VERSION ""

NS_ :

BS_:

BU_: AHLM ASBS CADM CBC DIAGNOST DPDM DTCM ECM EHPS ESC ESL ESM ETM EVCU2 GPF IC IRCM LTM OCM ORC PTS RF_HUB SCCM SGW TBM TCM

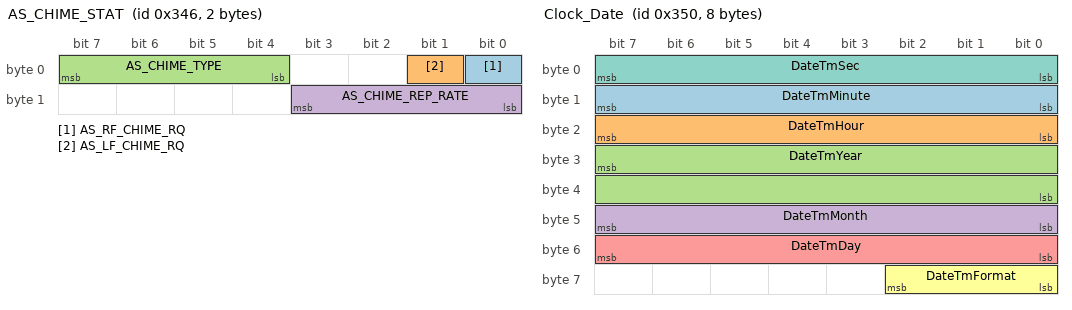
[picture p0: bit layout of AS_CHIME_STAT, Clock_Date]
BO_ 838 AS_CHIME_STAT: 2 CADM
 SG_ AS_RF_CHIME_RQ : 0|1@1+ (1,0) [0|0] ""  CBC,SGW
 SG_ AS_LF_CHIME_RQ : 1|1@1+ (1,0) [0|0] ""  CBC,SGW
 SG_ AS_CHIME_TYPE : 4|4@1+ (1,0) [0|0] ""  CBC,ORC,SGW
 SG_ AS_CHIME_REP_RATE : 8|4@1+ (1,0) [0|15] "Hz"  CBC,SGW

BO_ 840 ESP_C1: 8 ESC
 SG_ FailSafeError : 7|16@0+ (1,0) [0|65534] ""  CADM,IRCM,SGW

BO_ 848 Clock_Date: 8 CBC
 SG_ DateTmMinute : 8|8@1+ (1,0) [0|59] "min"  EVCU2,IC,RF_HUB,SGW
 SG_ DateTmHour : 16|8@1+ (1,0) [0|23] "Hours"  EVCU2,IC,RF_HUB,SGW
 SG_ DateTmYear : 31|16@0+ (1,0) [0|65534] "Years"  EVCU2,IC,RF_HUB,SGW
 SG_ DateTmMonth : 40|8@1+ (1,0) [1|12] "Months"  EVCU2,IC,RF_HUB,SGW
 SG_ DateTmDay : 48|8@1+ (1,0) [1|31] "Days"  EVCU2,IC,RF_HUB,SGW
 SG_ DateTmFormat : 56|3@1+ (1,0) [0|0] ""  EVCU2,IC,SGW
 SG_ DateTmSec : 0|8@1+ (1,0) [0|59] "sec"  EVCU2,IC,SGW

BO_ 850 ECM_APPL2: 8 DIAGNOST
 SG_ ECM_APPL2 : 7|64@0+ (1,0) [0|0] ""  ECM

BO_ 856 COMPASS_A1: 4 CBC
 SG_ CMP_DIR : 0|4@1+ (1,0) [0|0] ""  IC,SGW

BO_ 860 DIRECT_INFO: 6 CBC
 SG_ NAVPrsnt : 30|1@1+ (1,0) [0|0] ""  IC,SGW

BO_ 864 ECM_APPL1: 8 ECM
 SG_ ECM_APPL1 : 7|64@0+ (1,0) [0|0] ""  DIAGNOST,SGW

BO_ 872 TCM_HSA: 8 TCM
 SG_ TCM_HSA : 7|64@0+ (1,0) [0|0] ""  DIAGNOST,SGW

BO_ 880 ECM_APPL3: 8 ECM
 SG_ ECM_APPL3 : 7|64@0+ (1,0) [0|0] ""  DIAGNOST,SGW

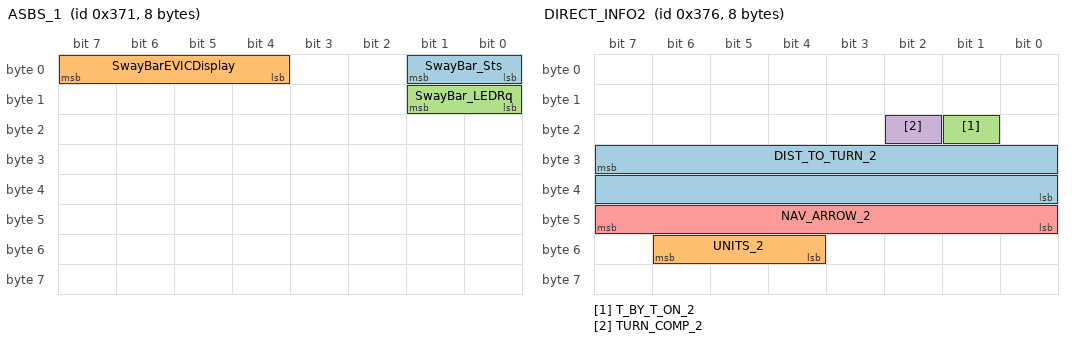
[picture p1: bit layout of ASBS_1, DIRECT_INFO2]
BO_ 881 ASBS_1: 8 ASBS
 SG_ SwayBar_Sts : 0|2@1+ (1,0) [0|0] ""  ETM,IC,SGW
 SG_ SwayBarEVICDisplay : 4|4@1+ (1,0) [0|0] ""  ETM,IC,SGW
 SG_ SwayBar_LEDRq : 8|2@1+ (1,0) [0|0] ""  CBC,SGW

BO_ 886 DIRECT_INFO2: 8 CBC
 SG_ DIST_TO_TURN_2 : 31|16@0+ (1,0) [0|65534] ""  IC,SGW
 SG_ UNITS_2 : 52|3@1+ (1,0) [0|0] ""  IC,SGW
 SG_ T_BY_T_ON_2 : 17|1@1+ (1,0) [0|0] ""  IC,SGW
 SG_ TURN_COMP_2 : 18|1@1+ (1,0) [0|0] ""  IC,SGW
 SG_ NAV_ARROW_2 : 40|8@1+ (1,0) [1|63] "Arrow"  IC,SGW

BO_ 888 TCM_HSB: 8 TCM
 SG_ TCM_HSB : 7|64@0+ (1,0) [0|0] ""  DIAGNOST,SGW

BO_ 896 ECM_APPL4: 8 ECM
 SG_ ECM_APPL4 : 7|64@0+ (1,0) [0|0] ""  DIAGNOST,SGW

BO_ 897 VehCfg7: 8 CBC
 SG_ VC_PBTyp : 29|3@1+ (1,0) [0|0] ""  CADM,IRCM,ORC,RF_HUB,SGW
 SG_ VC_TPMS_Configuration : 32|3@1+ (1,0) [0|0] ""  IC,RF_HUB,SGW
 SG_ VC_SmartAlternator : 35|1@1+ (1,0) [0|0] ""  ECM,RF_HUB,SGW
 SG_ VC_HybridType : 36|3@1+ (1,0) [0|0] ""  AHLM,CADM,DTCM,ECM,EHPS,ESC,EVCU2,IC,IRCM,ORC,PTS,RF_HUB,SGW,TCM
 SG_ VC_TSBM_Prsnt : 39|1@1+ (1,0) [0|0] ""  RF_HUB,SGW
 SG_ VC_ADR_PRSNT : 40|1@1+ (1,0) [0|0] ""  RF_HUB,SGW
 SG_ VC_Temp_Display_Resolution : 42|1@1+ (1,0) [0|0] ""  RF_HUB,SGW
 SG_ VC_AGSprsnt : 41|1@1+ (1,0) [0|0] ""  RF_HUB,SGW
 SG_ VC_PTCPrsnt : 43|1@1+ (1,0) [0|0] ""  ECM,RF_HUB,SGW
 SG_ VC_Glovebox : 44|1@1+ (1,0) [0|0] ""  RF_HUB,SGW
 SG_ VC_MOC_Type : 45|2@1+ (1,0) [0|0] ""  RF_HUB,SGW
 SG_ VC_SUNR_Prsnt : 47|1@1+ (1,0) [0|0] ""  RF_HUB,SGW
 SG_ VC_Brake_Type : 56|4@1+ (1,0) [0|0] ""  RF_HUB,SGW
 SG_ VC_Suspension_Type : 60|4@1+ (1,0) [0|0] ""  RF_HUB,SGW
 SG_ VC_GlareFree_Prsnt : 48|1@1+ (1,0) [0|0] ""  RF_HUB,SGW
 SG_ VC_PAD_Lamp_Ctrl : 49|1@1+ (1,0) [0|0] ""  RF_HUB,SGW
 SG_ VC_Vehicle_Package : 50|3@1+ (1,0) [0|0] ""  RF_HUB,SGW
 SG_ VC_TrafficSignInfo : 53|1@1+ (1,0) [0|0] ""  CADM,IC,RF_HUB,SGW
 SG_ VC_LaneCentering : 54|1@1+ (1,0) [0|0] ""  RF_HUB,SGW
 SG_ VC_LDW_Audio : 55|1@1+ (1,0) [0|0] ""  RF_HUB,SGW
 SG_ VC_VehCfg7_Stat : 0|2@1+ (1,0) [0|0] ""  CADM,DTCM,ECM,EHPS,ESC,EVCU2,IC,IRCM,ORC,PTS,RF_HUB,SCCM,SGW,TCM
 SG_ VC_LDW : 2|1@1+ (1,0) [0|0] ""  CADM,IC,IRCM,ORC,RF_HUB,SGW
 SG_ VC_TrnsDrvMdPrsnt : 3|1@1+ (1,0) [0|0] ""  RF_HUB,SGW,TCM
 SG_ VC_PdlsMdPrsnt : 4|1@1+ (1,0) [0|0] ""  RF_HUB,SGW,TCM
 SG_ VC_DST_Present : 5|1@1+ (1,0) [0|0] ""  ORC,RF_HUB,SGW
 SG_ VC_STP_PRSNT : 6|1@1+ (1,0) [0|0] ""  RF_HUB,SGW
 SG_ VC_eShifter_Prsnt : 7|1@1+ (1,0) [0|0] ""  RF_HUB,SGW
 SG_ VC_TransType : 8|6@1+ (1,0) [0|0] ""  DTCM,ESC,IC,RF_HUB,SGW
 SG_ VC_AS_ERS : 14|2@1+ (1,0) [0|0] ""  RF_HUB,SGW,TCM
 SG_ VC_TeenKey : 16|1@1+ (1,0) [0|0] ""  RF_HUB,SGW
 SG_ VC_SVC_Prsnt : 17|1@1+ (1,0) [0|0] ""  RF_HUB,SGW
 SG_ VC_FullSpeedRange_FCW : 18|1@1+ (1,0) [0|0] ""  CADM,ESC,IC,IRCM,RF_HUB,SGW
 SG_ VC_ACC_Type : 19|2@1+ (1,0) [0|0] ""  CADM,ECM,ESC,EVCU2,IC,IRCM,ORC,RF_HUB,SCCM,SGW,TCM
 SG_ VC_SuspPrsnt : 21|1@1+ (1,0) [0|0] ""  RF_HUB,SGW
 SG_ VC_DampingPrsnt : 22|1@1+ (1,0) [0|0] ""  RF_HUB,SGW
 SG_ VC_Trans_N_Hold_Prsnt : 23|1@1+ (1,0) [0|0] ""  RF_HUB,SGW
 SG_ VC_RedKey : 24|1@1+ (1,0) [0|0] ""  RF_HUB,SGW
 SG_ VC_ABSM : 25|1@1+ (1,0) [0|0] ""  RF_HUB,SGW
 SG_ VC_AxleLockerPrsnt : 26|2@1+ (1,0) [0|0] ""  DTCM,IC,RF_HUB,SGW
 SG_ VC_Trans_Equipped : 28|1@1+ (1,0) [0|0] ""  CADM,CBC,DTCM,ESC,IC,IRCM,ORC,PTS,RF_HUB,SGW

BO_ 898 VehCfgBu7: 8 RF_HUB
 SG_ VC_BU_VehCfg7_Stat : 0|2@1+ (1,0) [0|0] ""  CBC,SGW
 SG_ VC_BU_LDW : 2|1@1+ (1,0) [0|0] ""  CBC,SGW
 SG_ VC_BU_TrnsDrvMdPrsnt : 3|1@1+ (1,0) [0|0] ""  CBC,SGW
 SG_ VC_BU_PdlsMdPrsnt : 4|1@1+ (1,0) [0|0] ""  CBC,SGW
 SG_ VC_BU_DST_Present : 5|1@1+ (1,0) [0|0] ""  CBC,SGW
 SG_ VC_BU_STP_PRSNT : 6|1@1+ (1,0) [0|0] ""  CBC,SGW
 SG_ VC_BU_eShifter_Prsnt : 7|1@1+ (1,0) [0|0] ""  CBC,SGW
 SG_ VC_BU_TransType : 8|6@1+ (1,0) [0|0] ""  CBC,SGW
 SG_ VC_BU_AS_ERS : 14|2@1+ (1,0) [0|0] ""  CBC,SGW
 SG_ VC_BU_TeenKey : 16|1@1+ (1,0) [0|0] ""  CBC,SGW
 SG_ VC_BU_SVC_Prsnt : 17|1@1+ (1,0) [0|0] ""  CBC,SGW
 SG_ VC_BU_FullSpeedRange_FCW : 18|1@1+ (1,0) [0|0] ""  CBC,SGW
 SG_ VC_BU_ACC_Type : 19|2@1+ (1,0) [0|0] ""  CBC,SGW
 SG_ VC_BU_SuspPrsnt : 21|1@1+ (1,0) [0|0] ""  CBC,SGW
 SG_ VC_BU_DampingPrsnt : 22|1@1+ (1,0) [0|0] ""  CBC,SGW
 SG_ VC_BU_Trans_N_Hold_Prsnt : 23|1@1+ (1,0) [0|0] ""  CBC,SGW
 SG_ VC_BU_RedKey : 24|1@1+ (1,0) [0|0] ""  CBC,SGW
 SG_ VC_BU_ABSM : 25|1@1+ (1,0) [0|0] ""  CBC,SGW
 SG_ VC_BU_AxleLockerPrsnt : 26|2@1+ (1,0) [0|0] ""  CBC,SGW
 SG_ VC_BU_Trans_Equipped : 28|1@1+ (1,0) [0|0] ""  CBC,SGW
 SG_ VC_BU_PBTyp : 29|3@1+ (1,0) [0|0] ""  CBC,SGW
 SG_ VC_BU_TPMS_Configuration : 32|3@1+ (1,0) [0|0] ""  CBC,SGW
 SG_ VC_BU_SmartAlternator : 35|1@1+ (1,0) [0|0] ""  CBC,SGW
 SG_ VC_BU_HybridType : 36|3@1+ (1,0) [0|0] ""  CBC,SGW
 SG_ VC_BU_TSBM_Prsnt : 39|1@1+ (1,0) [0|0] ""  CBC,SGW
 SG_ VC_BU_ADR_PRSNT : 40|1@1+ (1,0) [0|0] ""  CBC,SGW
 SG_ VC_BU_Temp_Display_Resolution : 42|1@1+ (1,0) [0|0] ""  CBC,SGW
 SG_ VC_BU_AGSprsnt : 41|1@1+ (1,0) [0|0] ""  CBC,SGW
 SG_ VC_BU_PTCPrsnt : 43|1@1+ (1,0) [0|0] ""  CBC,SGW
 SG_ VC_BU_Glovebox : 44|1@1+ (1,0) [0|0] ""  CBC,SGW
 SG_ VC_BU_MOC_Type : 45|2@1+ (1,0) [0|0] ""  CBC,SGW
 SG_ VC_BU_SUNR_Prsnt : 47|1@1+ (1,0) [0|0] ""  CBC,SGW
 SG_ VC_BU_Brake_Type : 56|4@1+ (1,0) [0|0] ""  CBC,SGW
 SG_ VC_BU_Suspension_Type : 60|4@1+ (1,0) [0|0] ""  CBC,SGW
 SG_ VC_BU_GlareFree_Prsnt : 48|1@1+ (1,0) [0|0] ""  CBC,SGW
 SG_ VC_BU_PAD_Lamp_Ctrl : 49|1@1+ (1,0) [0|0] ""  CBC,SGW
 SG_ VC_BU_Vehicle_Package : 50|3@1+ (1,0) [0|0] ""  CBC,SGW
 SG_ VC_BU_TrafficSignInfo : 53|1@1+ (1,0) [0|0] ""  CBC,SGW
 SG_ VC_BU_LDW_Audio : 55|1@1+ (1,0) [0|0] ""  CBC,SGW
 SG_ VC_BU_LaneCentering : 54|1@1+ (1,0) [0|0] ""  CBC,SGW

BO_ 904 TCM_HSC: 8 TCM
 SG_ TCM_HSC : 7|64@0+ (1,0) [0|0] ""  DIAGNOST,SGW

BO_ 906 VehCfg8: 8 CBC
 SG_ VC_VehCfg8_Stat : 0|2@1+ (1,0) [0|0] ""  DTCM,ECM,EVCU2,IC,IRCM,RF_HUB,SGW,TCM
 SG_ VC_TIPL_LOT : 39|1@1+ (1,0) [0|0] ""  RF_HUB,SGW
 SG_ VC_STFA_Prsnt : 53|1@1+ (1,0) [0|0] ""  RF_HUB,SGW
 SG_ VC_Trans_Brake_PRSNT : 8|1@1+ (1,0) [0|0] ""  RF_HUB,SGW
 SG_ VC_Steering_Cfactor : 2|2@1+ (1,0) [0|0] ""  CADM,IRCM,RF_HUB,SGW
 SG_ VC_LineLock_PRSNT : 4|1@1+ (1,0) [0|0] ""  RF_HUB,SGW
 SG_ VC_HighOctane_PRSNT : 7|1@1+ (1,0) [0|0] ""  RF_HUB,SGW
 SG_ VC_CHILLER_PRSNT : 6|1@1+ (1,0) [0|0] ""  RF_HUB,SGW
 SG_ VC_ARC_PRSNT : 5|1@1+ (1,0) [0|0] ""  RF_HUB,SGW
 SG_ VC_Speedometer_Tolerance : 9|4@1+ (1,0) [0|0] ""  CADM,ECM,EVCU2,IC,IRCM,RF_HUB,SGW
 SG_ VC_Increasing_Speed_Constant : 13|3@1+ (1,0) [0|0] ""  CADM,ECM,EVCU2,IC,IRCM,RF_HUB,SGW
 SG_ VC_OvertakingBan : 16|1@1+ (1,0) [0|0] ""  IC,RF_HUB,SGW
 SG_ VC_SBL_FBL_CORNERING_PRSNT : 17|2@1+ (1,0) [0|0] ""  RF_HUB,SGW
 SG_ VC_BEAM_SHAPING_PRSNT : 19|1@1+ (1,0) [0|0] ""  RF_HUB,SGW
 SG_ VC_DBL_PRSNT : 20|1@1+ (1,0) [0|0] ""  RF_HUB,SGW
 SG_ VC_FADPrsnt : 38|1@1+ (1,0) [0|0] ""  DTCM,RF_HUB,SGW
 SG_ VC_AVAC_PRSNT : 21|1@1+ (1,0) [0|0] ""  RF_HUB,SGW
 SG_ VC_WHL_BASE_LENGTH : 56|4@1+ (1,0) [0|0] ""  CADM,IRCM,RF_HUB,SGW
 SG_ VC_VP_Level : 43|4@1+ (1,0) [0|0] ""  EVCU2,RF_HUB,SGW
 SG_ VC_OFFRoadModePrsnt : 22|1@1+ (1,0) [0|0] ""  CADM,DTCM,ECM,ESC,EVCU2,IC,IRCM,RF_HUB,SGW,TCM
 SG_ VC_OFFroad_Camera : 23|1@1+ (1,0) [0|0] ""  RF_HUB,SGW
 SG_ VC_PPPAHardBtn : 24|1@1+ (1,0) [0|0] ""  RF_HUB,SGW
 SG_ VC_PEB_PRSNT : 62|1@1+ (1,0) [0|0] ""  RF_HUB,SGW
 SG_ VC_TACHO_TYPE : 54|2@1+ (1,0) [0|0] ""  ECM,IC,RF_HUB,SGW
 SG_ VC_INDIA_SPEED_WARNING : 41|1@1+ (1,0) [0|0] ""  IC,RF_HUB,SGW

BO_ 907 VehCfgBu8: 8 RF_HUB
 SG_ VC_BU_Increasing_Speed_Constant : 13|3@1+ (1,0) [0|0] ""  CBC,SGW
 SG_ VC_BU_OvertakingBan : 16|1@1+ (1,0) [0|0] ""  CBC,SGW
 SG_ VC_BU_SBL_FBL_CORNERING_PRSNT : 17|2@1+ (1,0) [0|0] ""  CBC,SGW
 SG_ VC_BU_BEAM_SHAPING_PRSNT : 19|1@1+ (1,0) [0|0] ""  CBC,SGW
 SG_ VC_BU_DBL_PRSNT : 20|1@1+ (1,0) [0|0] ""  CBC,SGW
 SG_ VC_BU_FADPrsnt : 38|1@1+ (1,0) [0|0] ""  CBC,SGW
 SG_ VC_BU_AVAC_PRSNT : 21|1@1+ (1,0) [0|0] ""  CBC,SGW
 SG_ VC_BU_WHL_BASE_LENGTH : 56|4@1+ (1,0) [0|0] ""  CBC,SGW
 SG_ VC_BU_VP_Level : 43|4@1+ (1,0) [0|0] ""  CBC,SGW
 SG_ VC_BU_OFFRoadModePrsnt : 22|1@1+ (1,0) [0|0] ""  CBC,SGW
 SG_ VC_BU_OFFroad_Camera : 23|1@1+ (1,0) [0|0] ""  CBC,SGW
 SG_ VC_BU_PPPAHardBtn : 24|1@1+ (1,0) [0|0] ""  CBC,SGW
 SG_ VC_BU_Speedometer_Tolerance : 9|4@1+ (1,0) [0|0] ""  CBC,SGW
 SG_ VC_BU_VehCfg8_Stat : 0|2@1+ (1,0) [0|0] ""  CBC,SGW
 SG_ VC_BU_TIPL_LOT : 39|1@1+ (1,0) [0|0] ""  CBC,SGW
 SG_ VC_BU_STFA_Prsnt : 53|1@1+ (1,0) [0|0] ""  CBC,SGW
 SG_ VC_BU_Steering_Cfactor : 2|2@1+ (1,0) [0|0] ""  CBC,SGW
 SG_ VC_BU_LineLock_PRSNT : 4|1@1+ (1,0) [0|0] ""  CBC,SGW
 SG_ VC_BU_ARC_PRSNT : 5|1@1+ (1,0) [0|0] ""  CBC,SGW
 SG_ VC_BU_CHILLER_PRSNT : 6|1@1+ (1,0) [0|0] ""  CBC,SGW
 SG_ VC_BU_HighOctane_PRSNT : 7|1@1+ (1,0) [0|0] ""  CBC,SGW
 SG_ VC_BU_Trans_Brake_PRSNT : 8|1@1+ (1,0) [0|0] ""  CBC,SGW
 SG_ VC_BU_PEB_PRSNT : 62|1@1+ (1,0) [0|0] ""  CBC,SGW
 SG_ VC_BU_TACHO_TYPE : 54|2@1+ (1,0) [0|0] ""  CBC,SGW
 SG_ VC_BU_INDIA_SPEED_WARNING : 41|1@1+ (1,0) [0|0] ""  CBC,SGW

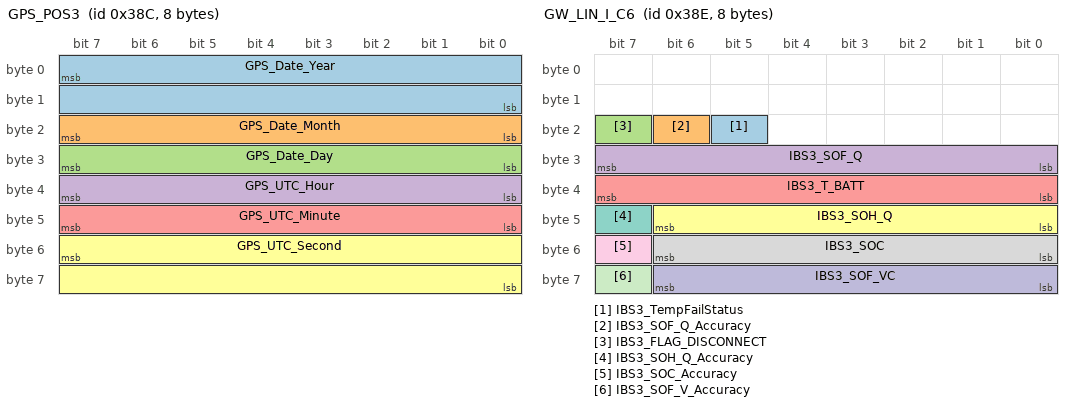
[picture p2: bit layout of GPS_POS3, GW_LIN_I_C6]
BO_ 908 GPS_POS3: 8 CBC
 SG_ GPS_Date_Year : 7|16@0+ (1,0) [0|65534] "Years"  EVCU2,ORC,SGW
 SG_ GPS_Date_Month : 16|8@1+ (1,0) [1|12] "Months"  EVCU2,ORC,SGW
 SG_ GPS_Date_Day : 24|8@1+ (1,0) [1|31] "Days"  EVCU2,ORC,SGW
 SG_ GPS_UTC_Hour : 32|8@1+ (1,0) [0|23] "h"  EVCU2,ORC,SGW
 SG_ GPS_UTC_Minute : 40|8@1+ (1,0) [0|59] "min"  EVCU2,ORC,SGW
 SG_ GPS_UTC_Second : 55|16@0+ (0.01,0) [0|59.99] "s"  EVCU2,ORC,SGW

BO_ 910 GW_LIN_I_C6: 8 CBC
 SG_ IBS3_TempFailStatus : 21|1@1+ (1,0) [0|0] ""  ECM,EVCU2,SGW
 SG_ IBS3_SOF_Q_Accuracy : 22|1@1+ (1,0) [0|0] ""  ECM,SGW
 SG_ IBS3_FLAG_DISCONNECT : 23|1@1+ (1,0) [0|0] ""  ECM,SGW
 SG_ IBS3_SOF_Q : 24|8@1+ (1,0) [0|254] "Ah"  ECM,SGW
 SG_ IBS3_T_BATT : 32|8@1+ (1,-40) [-40|105] "∞C"  ECM,ETM,EVCU2,SGW,TBM
 SG_ IBS3_SOH_Q : 40|7@1+ (2,0) [0|252] "Ah"  ECM,SGW
 SG_ IBS3_SOH_Q_Accuracy : 47|1@1+ (1,0) [0|0] ""  ECM,SGW
 SG_ IBS3_SOC : 48|7@1+ (1,0) [0|100] "%"  ECM,ETM,EVCU2,ORC,SGW,TBM
 SG_ IBS3_SOC_Accuracy : 55|1@1+ (1,0) [0|0] ""  ECM,ETM,EVCU2,SGW,TBM
 SG_ IBS3_SOF_VC : 56|7@1+ (0.05,5) [5|11.3] "V"  ECM,SGW
 SG_ IBS3_SOF_V_Accuracy : 63|1@1+ (1,0) [0|0] ""  ECM,SGW

BO_ 912 ECM_APPL5: 8 ECM
 SG_ ECM_APPL5 : 7|64@0+ (1,0) [0|0] ""  DIAGNOST,SGW

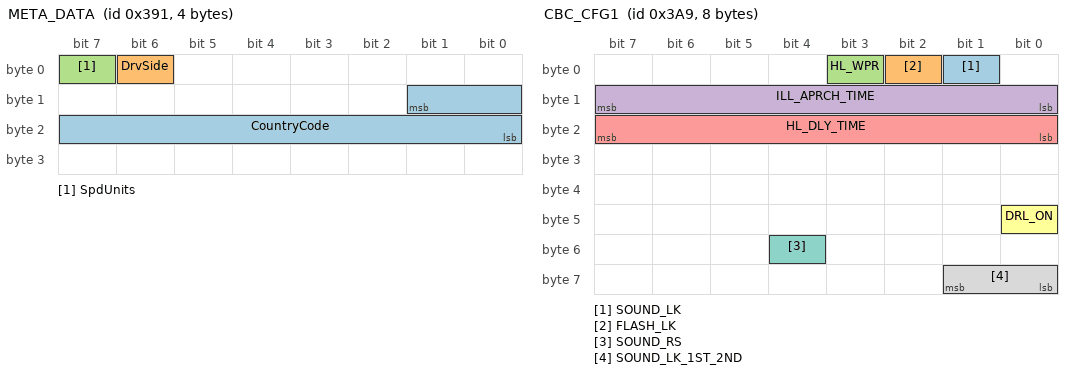
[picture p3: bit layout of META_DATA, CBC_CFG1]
BO_ 913 META_DATA: 4 CBC
 SG_ CountryCode : 9|10@0+ (1,0) [0|0] ""  CADM,SGW
 SG_ DrvSide : 6|1@1+ (1,0) [0|0] ""  CADM,SGW
 SG_ SpdUnits : 7|1@1+ (1,0) [0|0] ""  CADM,SGW

BO_ 920 TCM_HSD: 8 TCM
 SG_ TCM_HSD : 7|64@0+ (1,0) [0|0] ""  DIAGNOST,SGW

BO_ 926 NET_CFG_EPT: 3 CBC
 SG_ NetCfg_IDCM_ePT : 15|1@1+ (1,0) [0|0] ""  RF_HUB,SGW,TBM
 SG_ NetCfg_MCPA_ePT : 16|1@1+ (1,0) [0|0] ""  RF_HUB,SGW
 SG_ NET_CFG_STAT_ePT : 0|2@1+ (1,0) [0|0] ""  ESC,ESM,EVCU2,ORC,RF_HUB,SGW
 SG_ NetCfg_EBCM_ePT : 2|1@1+ (1,0) [0|0] ""  RF_HUB,SGW
 SG_ NetCfg_ORC_ePT : 3|1@1+ (1,0) [0|0] ""  RF_HUB,SGW,TBM
 SG_ NetCfg_ESM_ePT : 4|1@1+ (1,0) [0|0] ""  RF_HUB,SGW,TBM
 SG_ NetCfg_ESC_ePT : 5|1@1+ (1,0) [0|0] ""  RF_HUB,SGW,TBM
 SG_ NetCfg_ECM_ePT : 6|1@1+ (1,0) [0|0] ""  RF_HUB,SGW,TBM
 SG_ NetCfg_HCP_ePT : 7|1@1+ (1,0) [0|0] ""  RF_HUB,SGW
 SG_ NetCfg_OBCM_ePT : 8|1@1+ (1,0) [0|0] ""  RF_HUB,SGW
 SG_ NetCfg_AHCP_ePT : 9|1@1+ (1,0) [0|0] ""  RF_HUB,SGW
 SG_ NetCfg_SCA_ePT : 10|1@1+ (1,0) [0|0] ""  RF_HUB,SGW
 SG_ NetCfg_EAC_ePT : 11|1@1+ (1,0) [0|0] ""  RF_HUB,SGW
 SG_ NetCfg_BPCM_ePT : 12|1@1+ (1,0) [0|0] ""  RF_HUB,SGW,TBM
 SG_ NetCfg_APM_ePT : 13|1@1+ (1,0) [0|0] ""  RF_HUB,SGW
 SG_ NetCfg_BSMO_ePT : 14|1@1+ (1,0) [0|0] ""  RF_HUB,SGW,TBM
 SG_ NetCfg_EVCU2_ePT : 19|1@1+ (1,0) [0|0] ""  RF_HUB,SGW,TBM

BO_ 927 BU_NET_CFG_ePT: 3 RF_HUB
 SG_ BU_NET_CFG_STAT_ePT : 0|2@1+ (1,0) [0|0] ""  CBC,SGW
 SG_ BU_NetCfg_EBCM_ePT : 2|1@1+ (1,0) [0|0] ""  CBC,SGW
 SG_ BU_NetCfg_ORC_ePT : 3|1@1+ (1,0) [0|0] ""  CBC,SGW
 SG_ BU_NetCfg_ESM_ePT : 4|1@1+ (1,0) [0|0] ""  CBC,SGW
 SG_ BU_NetCfg_ESC_ePT : 5|1@1+ (1,0) [0|0] ""  CBC,SGW
 SG_ BU_NetCfg_ECM_ePT : 6|1@1+ (1,0) [0|0] ""  CBC,SGW
 SG_ BU_NetCfg_HCP_ePT : 7|1@1+ (1,0) [0|0] ""  CBC,SGW
 SG_ BU_NetCfg_OBCM_ePT : 8|1@1+ (1,0) [0|0] ""  CBC,SGW
 SG_ BU_NetCfg_AHCP_ePT : 9|1@1+ (1,0) [0|0] ""  CBC,SGW
 SG_ BU_NetCfg_SCA_ePT : 10|1@1+ (1,0) [0|0] ""  CBC,SGW
 SG_ BU_NetCfg_EAC_ePT : 11|1@1+ (1,0) [0|0] ""  CBC,SGW
 SG_ BU_NetCfg_BPCM_ePT : 12|1@1+ (1,0) [0|0] ""  CBC,SGW
 SG_ BU_NetCfg_APM_ePT : 13|1@1+ (1,0) [0|0] ""  CBC,SGW
 SG_ BU_NetCfg_BSMO_ePT : 14|1@1+ (1,0) [0|0] ""  CBC,SGW
 SG_ BU_NetCfg_IDCM_ePT : 15|1@1+ (1,0) [0|0] ""  CBC,SGW
 SG_ BU_NetCfg_MCPA_ePT : 16|1@1+ (1,0) [0|0] ""  CBC,SGW
 SG_ BU_NetCfg_EVCU2_ePT : 17|1@1+ (1,0) [0|0] ""  CBC,SGW
 SG_ BU_NetCfg_MCPB_ePT : 18|1@1+ (1,0) [0|0] ""  CBC,SGW

BO_ 928 ECM_APPL6: 8 ECM
 SG_ ECM_APPL6 : 7|64@0+ (1,0) [0|0] ""  DIAGNOST,SGW

BO_ 929 Radio_A3: 8 CBC
 SG_ Nav_Display_Cluster_Setting : 54|1@1+ (1,0) [0|0] ""  IC,SGW

BO_ 936 ECM_APPL7: 8 ECM
 SG_ ECM_APPL7 : 7|64@0+ (1,0) [0|0] ""  DIAGNOST,SGW

BO_ 937 CBC_CFG1: 8 CBC
 SG_ SOUND_LK : 1|1@1+ (1,0) [0|0] ""  SGW
 SG_ FLASH_LK : 2|1@1+ (1,0) [0|0] ""  SGW
 SG_ HL_WPR : 3|1@1+ (1,0) [0|0] ""  SGW
 SG_ ILL_APRCH_TIME : 8|8@1+ (1,0) [0|254] "sec"  SGW
 SG_ HL_DLY_TIME : 16|8@1+ (1,0) [0|254] "sec"  SGW
 SG_ DRL_ON : 40|1@1+ (1,0) [0|0] ""  SGW
 SG_ SOUND_RS : 52|1@1+ (1,0) [0|0] ""  SGW
 SG_ SOUND_LK_1ST_2ND : 56|2@1+ (1,0) [0|0] ""  SGW

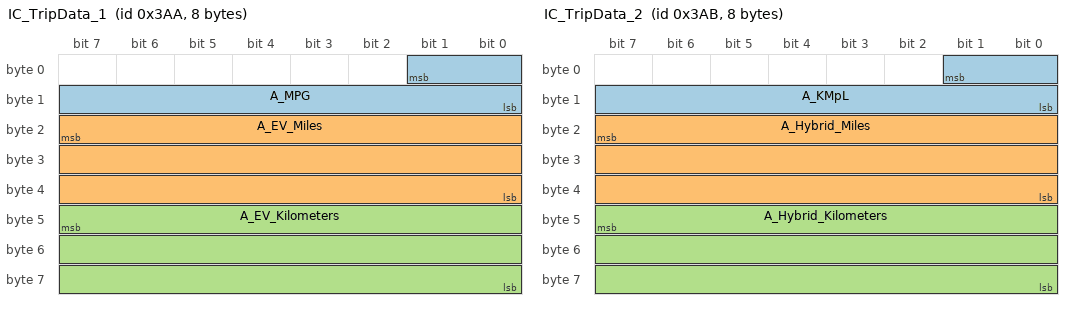
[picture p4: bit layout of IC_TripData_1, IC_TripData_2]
BO_ 938 IC_TripData_1: 8 IC
 SG_ A_MPG : 1|10@0+ (0.1,0) [0|99.9] "MPG"  ETM,SGW,TBM
 SG_ A_EV_Miles : 23|24@0+ (0.1,0) [0|9999.9] "Mile"  ETM,SGW,TBM
 SG_ A_EV_Kilometers : 47|24@0+ (0.1,0) [0|16093.3] "km"  ETM,SGW,TBM

BO_ 939 IC_TripData_2: 8 IC
 SG_ A_KMpL : 1|10@0+ (0.1,0) [0|99.9] "kmpl"  ETM,SGW,TBM
 SG_ A_Hybrid_Miles : 23|24@0+ (0.1,0) [0|9999.9] "Mile"  ETM,SGW,TBM
 SG_ A_Hybrid_Kilometers : 47|24@0+ (0.1,0) [0|16093.3] "km"  ETM,SGW,TBM

BO_ 940 IC_TripData_3: 8 IC
 SG_ A_Total_Dist_Miles : 23|24@0+ (0.1,0) [0|9999.9] "Mile"  ETM,SGW,TBM
 SG_ A_Total_Dist_Kilometers : 47|24@0+ (0.1,0) [0|16093.3] "km"  ETM,SGW,TBM

BO_TX_BU_ 838 : CADM,IRCM;
BO_TX_BU_ 850 : DIAGNOST,SGW;
CM_ SG_ 838 AS_RF_CHIME_RQ "AS right front chime on request; True = [1]";
CM_ SG_ 838 AS_LF_CHIME_RQ "AS left front chime on request; True = [1]";
CM_ SG_ 838 AS_CHIME_TYPE "AS chime type";
CM_ SG_ 838 AS_CHIME_REP_RATE "AS chime repetition rate";
CM_ SG_ 840 FailSafeError "Fail safe error";
CM_ SG_ 848 DateTmMinute "Time of day: MINUTES";
CM_ SG_ 848 DateTmHour "Time of day: HOURS";
CM_ SG_ 848 DateTmYear "Date year";
CM_ SG_ 848 DateTmMonth "Month";
CM_ SG_ 848 DateTmDay "Day";
CM_ SG_ 848 DateTmFormat "Date and Time Format";
CM_ SG_ 848 DateTmSec "Time of day: SECONDS";
CM_ SG_ 850 ECM_APPL2 "Application";
CM_ SG_ 856 CMP_DIR "Compass direction (WK/LX)";
CM_ SG_ 860 NAVPrsnt "A navigation system module is present";
CM_ SG_ 864 ECM_APPL1 "Application";
CM_ SG_ 872 TCM_HSA "Manual control at test bench";
CM_ SG_ 880 ECM_APPL3 "CCP synchronous - TDC event DAQ";
CM_ SG_ 881 SwayBar_Sts "Swaybar status";
CM_ SG_ 881 SwayBarEVICDisplay "Sway Bar HMI display request";
CM_ SG_ 881 SwayBar_LEDRq "Sway Bar disconnect switch LED request";
CM_ SG_ 886 DIST_TO_TURN_2 "Numeric distance to next turn";
CM_ SG_ 886 UNITS_2 "Unit of measure";
CM_ SG_ 886 T_BY_T_ON_2 "Turn by turn on";
CM_ SG_ 886 TURN_COMP_2 "Turn complete";
CM_ SG_ 886 NAV_ARROW_2 "Navigation arrow type";
CM_ SG_ 888 TCM_HSB "Manual control at test bench";
CM_ SG_ 896 ECM_APPL4 "CCP 5ms DAQ  (from ENGINE to external tool)";
CM_ SG_ 897 VC_PBTyp "Park brake type";
CM_ SG_ 897 VC_TPMS_Configuration "TPMS configuration";
CM_ SG_ 897 VC_SmartAlternator "Smart alternator is present; True = [1]";
CM_ SG_ 897 VC_HybridType "Identify the kind of hybrid vehicle";
CM_ SG_ 897 VC_TSBM_Prsnt "TSBM LIN slave is present; True = [1]";
CM_ SG_ 897 VC_ADR_PRSNT "ADR feature present; True = [1]";
CM_ SG_ 897 VC_Temp_Display_Resolution "Toggle between 0.5degC and 1degC temperature display";
CM_ SG_ 897 VC_AGSprsnt "AGS Present/Absent;  Present = 1";
CM_ SG_ 897 VC_PTCPrsnt "PTC Present/Absent;  Present = 1";
CM_ SG_ 897 VC_Glovebox "Glovebox control; Present = 1";
CM_ SG_ 897 VC_MOC_Type "Motor on caliper type";
CM_ SG_ 897 VC_SUNR_Prsnt "Sunroof is present; True = 1";
CM_ SG_ 897 VC_Brake_Type "Brake type";
CM_ SG_ 897 VC_Suspension_Type "Suspension type";
CM_ SG_ 897 VC_GlareFree_Prsnt "Glare Free Present";
CM_ SG_ 897 VC_PAD_Lamp_Ctrl "ECU Controlling PAD Lamp";
CM_ SG_ 897 VC_Vehicle_Package "Vehicle Package Content";
CM_ SG_ 897 VC_TrafficSignInfo "Traffic Sign Information Feature";
CM_ SG_ 897 VC_LaneCentering "Lane Centering / HAS feature";
CM_ SG_ 897 VC_LDW_Audio "LDW without Haptic Feedback feature";
CM_ SG_ 897 VC_VehCfg7_Stat "Configuration messages status 7";
CM_ SG_ 897 VC_LDW "Lane Departure Warning present; present = [1]";
CM_ SG_ 897 VC_TrnsDrvMdPrsnt "Transmission drive mode feature; present = [1]";
CM_ SG_ 897 VC_PdlsMdPrsnt "Paddles lock-out feature; present = [1]";
CM_ SG_ 897 VC_DST_Present "Dynamic steering torque present; True = [1]";
CM_ SG_ 897 VC_STP_PRSNT "Super trac pack present; True = [1]";
CM_ SG_ 897 VC_eShifter_Prsnt "e-shifter present; present = [1]";
CM_ SG_ 897 VC_TransType "Automatic transmission type";
CM_ SG_ 897 VC_AS_ERS "Shift feature autostick / electronic range select status";
CM_ SG_ 897 VC_TeenKey "TeenKey feature is present; Present = [1]";
CM_ SG_ 897 VC_SVC_Prsnt "Surround view camera; present = [1]";
CM_ SG_ 897 VC_FullSpeedRange_FCW "Full speed range forward collision warning plus system present; Present = 1";
CM_ SG_ 897 VC_ACC_Type "Type of adaptive cruise control (ACC) system present";
CM_ SG_ 897 VC_SuspPrsnt "NetCfg_ASCM contains suspension; present = [1]";
CM_ SG_ 897 VC_DampingPrsnt "NetCfg_ASCM contains active damping; present = [1]";
CM_ SG_ 897 VC_Trans_N_Hold_Prsnt "Transmission neutral hold feature; present = [1]";
CM_ SG_ 897 VC_RedKey "RedKey feature is present; Present = [1]";
CM_ SG_ 897 VC_ABSM "Active Blind Spot present; present = [1]";
CM_ SG_ 897 VC_AxleLockerPrsnt "Axle locker configuration";
CM_ SG_ 897 VC_Trans_Equipped "Transmission equipped: 0 = Automatic & 1 = Manual";
CM_ SG_ 898 VC_BU_VehCfg7_Stat "Backup for Configuration messages status 7";
CM_ SG_ 898 VC_BU_LDW "Lane departure warning present; present = [1]";
CM_ SG_ 898 VC_BU_TrnsDrvMdPrsnt "Backup for transmission drive mode feature; present = [1]";
CM_ SG_ 898 VC_BU_PdlsMdPrsnt "Backup for paddles lock-out feature; present = [1]";
CM_ SG_ 898 VC_BU_DST_Present "Backup for dynamic steering torque present; True = [1]";
CM_ SG_ 898 VC_BU_STP_PRSNT "Backup for super trac pack present; True = [1]";
CM_ SG_ 898 VC_BU_eShifter_Prsnt "Backup for e-shifter present; present = [1]";
CM_ SG_ 898 VC_BU_TransType "Backup for automatic transmission type";
CM_ SG_ 898 VC_BU_AS_ERS "Backup for shift feature autostick / electronic range select status";
CM_ SG_ 898 VC_BU_TeenKey "Backup for teenKey feature is present; Present = [1]";
CM_ SG_ 898 VC_BU_SVC_Prsnt "Backup for surround view camera; present = [1]";
CM_ SG_ 898 VC_BU_FullSpeedRange_FCW "Backup for full speed range forward collision warning plus system present; Present = 1";
CM_ SG_ 898 VC_BU_ACC_Type "Backup for type of adaptive cruise control (ACC) system present";
CM_ SG_ 898 VC_BU_SuspPrsnt "backup for ASCM contains suspension; present = [1]";
CM_ SG_ 898 VC_BU_DampingPrsnt "Backup for ASCM contains active damping; present = [1]";
CM_ SG_ 898 VC_BU_Trans_N_Hold_Prsnt "Backup for Transmission neutral hold feature; present = [1]";
CM_ SG_ 898 VC_BU_RedKey "Backup for RedKey feature is present; Present = [1]";
CM_ SG_ 898 VC_BU_ABSM "Backup for Active Blind Spot present; present = [1]";
CM_ SG_ 898 VC_BU_AxleLockerPrsnt "Backup for axle locker configuration";
CM_ SG_ 898 VC_BU_Trans_Equipped "Backup for Transmission equipped: 0 = Automatic & 1 = Manual";
CM_ SG_ 898 VC_BU_PBTyp "Backup for park brake type";
CM_ SG_ 898 VC_BU_TPMS_Configuration "Backup for TPMS configuration";
CM_ SG_ 898 VC_BU_SmartAlternator "Backup for smart alternator is present; True = [1]";
CM_ SG_ 898 VC_BU_HybridType "Backup for identify the kind of hybrid vehicle";
CM_ SG_ 898 VC_BU_TSBM_Prsnt "Backup for TSBM LIN slave is present; True = [1]";
CM_ SG_ 898 VC_BU_ADR_PRSNT "Backup for ADR feature present; True = [1]";
CM_ SG_ 898 VC_BU_Temp_Display_Resolution "Backup for toggle between 0.5degC and 1degC temperature display";
CM_ SG_ 898 VC_BU_AGSprsnt "Backup for AGS present/absent config signal;  Present = 1";
CM_ SG_ 898 VC_BU_PTCPrsnt "Backup for PTC present/absent config signal;  Present = 1";
CM_ SG_ 898 VC_BU_Glovebox "Backup for Glovebox control; Present = 1";
CM_ SG_ 898 VC_BU_MOC_Type "Backup for motor on caliper type";
CM_ SG_ 898 VC_BU_SUNR_Prsnt "Backup for sunroof is present; True = 1";
CM_ SG_ 898 VC_BU_Brake_Type "Backup for brake type";
CM_ SG_ 898 VC_BU_Suspension_Type "Backup for suspension type";
CM_ SG_ 898 VC_BU_GlareFree_Prsnt "Glare Free Present";
CM_ SG_ 898 VC_BU_PAD_Lamp_Ctrl "ECU Controlling PAD Lamp";
CM_ SG_ 898 VC_BU_Vehicle_Package "Vehicle Package Content";
CM_ SG_ 898 VC_BU_TrafficSignInfo "Backup for Traffic Sign Information Feature";
CM_ SG_ 898 VC_BU_LDW_Audio "LDW without Haptic Feedback feature";
CM_ SG_ 898 VC_BU_LaneCentering "Lane Centering / HAS feature";
CM_ SG_ 904 TCM_HSC "Manual control at test bench";
CM_ SG_ 906 VC_VehCfg8_Stat "Configuration messages status 8";
CM_ SG_ 906 VC_TIPL_LOT "Traffic in Parallel and Lock on Target (1=present)";
CM_ SG_ 906 VC_STFA_Prsnt "Selectable Tire Fill Alert Present; True = [1]";
CM_ SG_ 906 VC_Trans_Brake_PRSNT "Transmission Brake feature present; True = [1]";
CM_ SG_ 906 VC_Steering_Cfactor "Steering Cfactor feature";
CM_ SG_ 906 VC_LineLock_PRSNT "Line Lock feature present; True = [1]";
CM_ SG_ 906 VC_HighOctane_PRSNT "High Octane feature present; True = [1]";
CM_ SG_ 906 VC_CHILLER_PRSNT "Chiller present; True = [1]";
CM_ SG_ 906 VC_ARC_PRSNT "After Run Cooling (Race Cool Down) feature present; True = [1]";
CM_ SG_ 906 VC_Speedometer_Tolerance "Speedometer Tolerance Percentage (Gain for Speedometer Biasing)";
CM_ SG_ 906 VC_Increasing_Speed_Constant "Increasing Speed Constant (Offset for Speedometer Biasing)";
CM_ SG_ 906 VC_OvertakingBan "Overtaking Ban present; present = [1]";
CM_ SG_ 906 VC_SBL_FBL_CORNERING_PRSNT "Configuration messages status 8";
CM_ SG_ 906 VC_BEAM_SHAPING_PRSNT "Present = 1";
CM_ SG_ 906 VC_DBL_PRSNT "Present = 1";
CM_ SG_ 906 VC_FADPrsnt "Present = 1";
CM_ SG_ 906 VC_AVAC_PRSNT "Present = 1";
CM_ SG_ 906 VC_WHL_BASE_LENGTH "Wheel Base Length";
CM_ SG_ 906 VC_VP_Level "Radio Type Identifier";
CM_ SG_ 906 VC_OFFRoadModePrsnt "OFF ROAD MODE Present, Present = 1";
CM_ SG_ 906 VC_OFFroad_Camera "OFF Road Camera Present, Present = 1";
CM_ SG_ 906 VC_PPPAHardBtn "PPPA Hard button present, Present = 1";
CM_ SG_ 906 VC_PEB_PRSNT "Vehicle config to learn the presence of PEB";
CM_ SG_ 906 VC_TACHO_TYPE "CBC VC Config of Tachometer Type";
CM_ SG_ 906 VC_INDIA_SPEED_WARNING "INDIA EQUIPPED SPEED WARNING Feature";
CM_ SG_ 907 VC_BU_Increasing_Speed_Constant "Backup for Increasing Speed Constant (Offset for Speedometer Biasing)";
CM_ SG_ 907 VC_BU_OvertakingBan "Backup for Overtaking Ban present; present = [1]";
CM_ SG_ 907 VC_BU_SBL_FBL_CORNERING_PRSNT "Configuration messages status 8";
CM_ SG_ 907 VC_BU_BEAM_SHAPING_PRSNT "Present = 1";
CM_ SG_ 907 VC_BU_DBL_PRSNT "Present = 1";
CM_ SG_ 907 VC_BU_FADPrsnt "Present = 1";
CM_ SG_ 907 VC_BU_AVAC_PRSNT "Present = 1";
CM_ SG_ 907 VC_BU_WHL_BASE_LENGTH "Back up Wheel Base Length";
CM_ SG_ 907 VC_BU_VP_Level "Back up for Radio Type Identifier";
CM_ SG_ 907 VC_BU_OFFRoadModePrsnt "OFF ROAD MODE Present BackUp Configuration, Present = 1";
CM_ SG_ 907 VC_BU_OFFroad_Camera "OFF Road Camera Present, Present = 1";
CM_ SG_ 907 VC_BU_PPPAHardBtn "PPPA Hard button present; Present = [1]";
CM_ SG_ 907 VC_BU_Speedometer_Tolerance "Backup for Speedometer Tolerance Percentage (Gain for Speedometer Biasing)";
CM_ SG_ 907 VC_BU_VehCfg8_Stat "Backup for Configuration messages status 8";
CM_ SG_ 907 VC_BU_TIPL_LOT "Backup for Traffic in Parallel and Lock on Target (1=present)";
CM_ SG_ 907 VC_BU_STFA_Prsnt "Back up for Selectable Tire Fill Alert Present; True = [1]";
CM_ SG_ 907 VC_BU_Steering_Cfactor "Backup for Steering Cfactor feature";
CM_ SG_ 907 VC_BU_LineLock_PRSNT "Backup for Line Lock feature present; True = [1]";
CM_ SG_ 907 VC_BU_ARC_PRSNT "Backup for After Run Cooling (Race Cool Down) feature present; True = [1]";
CM_ SG_ 907 VC_BU_CHILLER_PRSNT "Backup for Chiller present; True = [1]";
CM_ SG_ 907 VC_BU_HighOctane_PRSNT "Backup for High Octane feature present; True = [1]";
CM_ SG_ 907 VC_BU_Trans_Brake_PRSNT "Backup for Transmission Brake feature present; True = [1]";
CM_ SG_ 907 VC_BU_PEB_PRSNT "Vehicle config to learn the presence of PEB";
CM_ SG_ 907 VC_BU_TACHO_TYPE "Backup Vehicle Configuration 8 Packet";
CM_ SG_ 907 VC_BU_INDIA_SPEED_WARNING "Back up for INDIA EQUIPPED SPEED WARNING Feature";
CM_ SG_ 908 GPS_Date_Year "GPS date year";
CM_ SG_ 908 GPS_Date_Month "GPS date month";
CM_ SG_ 908 GPS_Date_Day "GPS date day";
CM_ SG_ 908 GPS_UTC_Hour "GPS UTC hour";
CM_ SG_ 908 GPS_UTC_Minute "GPS UTC minute";
CM_ SG_ 908 GPS_UTC_Second "GPS UTC second";
CM_ SG_ 910 IBS3_TempFailStatus "Failure of ASIC Temperature meas. (internal defect)";
CM_ SG_ 910 IBS3_SOF_Q_Accuracy "SOF_Q accuracy status";
CM_ SG_ 910 IBS3_FLAG_DISCONNECT "Battery disconnection flag";
CM_ SG_ 910 IBS3_SOF_Q "Residual battery charge in Ah";
CM_ SG_ 910 IBS3_T_BATT "Battery temperature";
CM_ SG_ 910 IBS3_SOH_Q "State of health related to capacity (energy)";
CM_ SG_ 910 IBS3_SOH_Q_Accuracy "SOH_Q accuracy status";
CM_ SG_ 910 IBS3_SOC "State of charge";
CM_ SG_ 910 IBS3_SOC_Accuracy "SOC accuracy status";
CM_ SG_ 910 IBS3_SOF_VC "Predicted initial battery voltage dip during cranking (old CG spec)";
CM_ SG_ 910 IBS3_SOF_V_Accuracy "SOF_V accuracy; Data reliable = [0], unreliable = [1]";
CM_ SG_ 912 ECM_APPL5 "CCP 10ms DAQ  (from ENGINE to external tool)";
CM_ SG_ 913 CountryCode "Country Code (Coding based on ISO 3166-1 numeric)";
CM_ SG_ 913 DrvSide "Driving Side";
CM_ SG_ 913 SpdUnits "Speed Units";
CM_ SG_ 920 TCM_HSD "Manual control at test bench";
CM_ SG_ 926 NetCfg_IDCM_ePT "Integrated Dual Charge Module Net Config (1=present)";
CM_ SG_ 926 NetCfg_MCPA_ePT "Motor Control Processor A (1=present)";
CM_ SG_ 926 NET_CFG_STAT_ePT "Network configuration status.";
CM_ SG_ 926 NetCfg_EBCM_ePT "Electronic Boost Control Module (1=present)";
CM_ SG_ 926 NetCfg_ORC_ePT "Occupant Restraint Controller (1=present)";
CM_ SG_ 926 NetCfg_ESM_ePT "Electronic Shifter Module (1=present)";
CM_ SG_ 926 NetCfg_ESC_ePT "Electronic Stability Control (1=present)";
CM_ SG_ 926 NetCfg_ECM_ePT "Engine Controller Module (1=present)";
CM_ SG_ 926 NetCfg_HCP_ePT "Hybrid Control Processor (1=present)";
CM_ SG_ 926 NetCfg_OBCM_ePT "On Board Charging Module. 1=present";
CM_ SG_ 926 NetCfg_AHCP_ePT "Transmission Control Processor (1=present)";
CM_ SG_ 926 NetCfg_SCA_ePT "Smart Cluch Actuator (1=present)";
CM_ SG_ 926 NetCfg_EAC_ePT "Electric AC Compressor (1=present)";
CM_ SG_ 926 NetCfg_BPCM_ePT "Battery Pack Control Module (1=present)";
CM_ SG_ 926 NetCfg_APM_ePT "Auxiliary Power Module (1=present)";
CM_ SG_ 926 NetCfg_BSMO_ePT "Brake System Module - OBD (1=present)";
CM_ SG_ 926 NetCfg_EVCU2_ePT "Electric Vehicle Control Unit 2 (1=present)";
CM_ SG_ 927 BU_NET_CFG_STAT_ePT "Backup for network configuration status";
CM_ SG_ 927 BU_NetCfg_EBCM_ePT "Backup for Electronic Boost Control Module (1=present)";
CM_ SG_ 927 BU_NetCfg_ORC_ePT "Backup for Occupant Restraint Controller (1=present)";
CM_ SG_ 927 BU_NetCfg_ESM_ePT "Backup for Electronic Shifter Module (1=present)";
CM_ SG_ 927 BU_NetCfg_ESC_ePT "Backup for Electronic Stability Control (1=present)";
CM_ SG_ 927 BU_NetCfg_ECM_ePT "Backup for Engine Controller Module (1=present)";
CM_ SG_ 927 BU_NetCfg_HCP_ePT "Backup for Hybrid Control Processor (1=present)";
CM_ SG_ 927 BU_NetCfg_OBCM_ePT "Backup for On Board Charging Module (1=present)";
CM_ SG_ 927 BU_NetCfg_AHCP_ePT "Backup for Auxiliary Hybrid Control Processor (1=present)";
CM_ SG_ 927 BU_NetCfg_SCA_ePT "Backup for Smart Cluch Actuator (1=present)";
CM_ SG_ 927 BU_NetCfg_EAC_ePT "Backup for Electric AC Compressor (1=present)";
CM_ SG_ 927 BU_NetCfg_BPCM_ePT "Backup for Battery Pack Control Module (1=present)";
CM_ SG_ 927 BU_NetCfg_APM_ePT "Backup for Auxiliary Power Module (1=present)";
CM_ SG_ 927 BU_NetCfg_BSMO_ePT "Backup for Brake System Module - OBD (1=present)";
CM_ SG_ 927 BU_NetCfg_IDCM_ePT "Backup for Integrated Dual Charge Module Net Config (1=present)";
CM_ SG_ 927 BU_NetCfg_MCPA_ePT "Backup for Motor Control Processor A (1=present)";
CM_ SG_ 927 BU_NetCfg_EVCU2_ePT "Electric Vehicle Control Unit 2 (1=present)";
CM_ SG_ 927 BU_NetCfg_MCPB_ePT "Motor Control Processor B (1=present)";
CM_ SG_ 928 ECM_APPL6 "CCP 80ms DAQ  (from ENGINE to external tool)";
CM_ SG_ 929 Nav_Display_Cluster_Setting "Navigation Setting for Turn by Turn display on the Cluster;0h: Not_Active,1h: Active";
CM_ SG_ 936 ECM_APPL7 "Application";
CM_ SG_ 937 SOUND_LK "Sound horn on lock; no = [0], yes = [1]";
CM_ SG_ 937 FLASH_LK "Flash lamps with lock; no = [0], yes = [1]";
CM_ SG_ 937 HL_WPR "Headlamp on with wiper; no = [0], yes =[1]";
CM_ SG_ 937 ILL_APRCH_TIME "Illuminated approach time";
CM_ SG_ 937 HL_DLY_TIME "Headlamp delay time";
CM_ SG_ 937 DRL_ON "Daytime running lamps on; enabled = [1]";
CM_ SG_ 937 SOUND_RS "Sound horn on Remote Start ; no = [0], yes = [1]";
CM_ SG_ 937 SOUND_LK_1ST_2ND "Sound horn on lock status";
CM_ SG_ 938 A_MPG "Trip A Combined fuel economy in US MPG";
CM_ SG_ 938 A_EV_Miles "Trip A EV distance in US miles";
CM_ SG_ 938 A_EV_Kilometers "Trip A EV distance in kilometers";
CM_ SG_ 939 A_KMpL "Trip A Combined fuel economy in Km/L";
CM_ SG_ 939 A_Hybrid_Miles "Trip A hybrid distance in US miles";
CM_ SG_ 939 A_Hybrid_Kilometers "Trip A hybrid distance in kilometers";
CM_ SG_ 940 A_Total_Dist_Miles "Trip A total distance in US miles";
CM_ SG_ 940 A_Total_Dist_Kilometers "Trip A total distance in kilometers";
BA_DEF_ BO_  "App-Botschaft" ENUM  "nein","ja";
BA_DEF_ BO_  "CanMsgMinLen" INT 0 8;
BA_DEF_ BO_  "DiagRequest" ENUM  "nein","ja";
BA_DEF_ BO_  "DiagResponse" ENUM  "nein","ja";
BA_DEF_ BO_  "DiagState" ENUM  "nein","ja";
BA_DEF_ BO_  "GenMsgCycleTime" INT 0 65535;
BA_DEF_ BO_  "GenMsgCycleTimeActive" INT 0 65535;
BA_DEF_ BO_  "GenMsgDelayTime" INT 0 65535;
BA_DEF_ BO_  "GenMsgNrOfRepetitions" INT 0 65535;
BA_DEF_ BO_  "GenMsgSendType" ENUM  "cyclicX","spontanX","cyclicIfActiveX","spontanWithDelay","cyclicAndSpontanX","cyclicAndSpontanWithDelay","spontanWithRepitition","cyclicIfActiveAndSpontanWD","cyclicIfActiveFast","cyclicWithRepeatOnDemand","none";
BA_DEF_ BO_  "GenMsgStartDelayTime" INT 0 65535;
BA_DEF_ BO_  "GenMsgStartValue" STRING ;
BA_DEF_ BO_  "NWM-Botschaft" ENUM  "nein","ja";
BA_DEF_ BO_  "TpTxIndex" INT 0 99;
BA_DEF_ SG_  "FlexKomComment" STRING ;
BA_DEF_ SG_  "FlexKomIsMotorola" ENUM  "nein","ja";
BA_DEF_ SG_  "FlexKomSID" INT 0 2147483647;
BA_DEF_ SG_  "FlexKomSigLaenge" INT 0 64;
BA_DEF_ SG_  "FlexKomSigName" STRING ;
BA_DEF_ SG_  "FlexKomSigStartPos" INT 0 63;
BA_DEF_ SG_  "FlexKomSigStartValue" STRING ;
BA_DEF_ SG_  "GenSigCycleTime" INT 0 65535;
BA_DEF_ SG_  "GenSigCycleTimeActive" INT 0 65535;
BA_DEF_ SG_  "GenSigSendType" ENUM  "cyclicX","spontanX","cyclicIfActiveX","spontanWithDelay","cyclicAndSpontanX","cyclicAndSpontanWithDelay","spontanWithRepitition","cyclicIfActiveAndSpontanWD","cyclicIfActiveFast","cyclicWithRepeatOnDemand","none";
BA_DEF_ SG_  "GenSigSNA" STRING ;
BA_DEF_ SG_  "GenSigStartValue" HEX 0 2147483648;
BA_DEF_ SG_  "GenSigTimeout_AHLM" INT 0 65535;
BA_DEF_ SG_  "GenSigTimeout_ASBS" INT 0 65535;
BA_DEF_ SG_  "GenSigTimeout_CBC" INT 0 65535;
BA_DEF_ SG_  "GenSigTimeout_DPDM" INT 0 65535;
BA_DEF_ SG_  "GenSigTimeout_DTCM" INT 0 65535;
BA_DEF_ SG_  "GenSigTimeout_EHPS" INT 0 65535;
BA_DEF_ SG_  "GenSigTimeout_ESC" INT 0 65535;
BA_DEF_ SG_  "GenSigTimeout_ESL" INT 0 65535;
BA_DEF_ SG_  "GenSigTimeout_ESM" INT 0 65535;
BA_DEF_ SG_  "GenSigTimeout_ETM" INT 0 65535;
BA_DEF_ SG_  "GenSigTimeout_IC" INT 0 65535;
BA_DEF_ SG_  "GenSigTimeout_OCM" INT 0 65535;
BA_DEF_ SG_  "GenSigTimeout_ORC" INT 0 65535;
BA_DEF_ SG_  "GenSigTimeout_PTS" INT 0 65535;
BA_DEF_ SG_  "GenSigTimeout_RF_HUB" INT 0 65535;
BA_DEF_ SG_  "GenSigTimeout_SCCM" INT 0 65535;
BA_DEF_ SG_  "GenSigTimeout_TBM" INT 0 65535;
BA_DEF_ SG_  "GenSigTimeout_TCM" INT 0 65535;
BA_DEF_ SG_  "GenSigTimeout_TPM" INT 0 65535;
BA_DEF_ SG_  "RID" STRING ;
BA_DEF_ SG_  "SystemSignalLongSymbol" STRING ;
BA_DEF_DEF_  "App-Botschaft" "nein";
BA_DEF_DEF_  "CanMsgMinLen" 0;
BA_DEF_DEF_  "DiagRequest" "nein";
BA_DEF_DEF_  "DiagResponse" "nein";
BA_DEF_DEF_  "DiagState" "nein";
BA_DEF_DEF_  "GenMsgCycleTime" 0;
BA_DEF_DEF_  "GenMsgCycleTimeActive" 0;
BA_DEF_DEF_  "GenMsgDelayTime" 0;
BA_DEF_DEF_  "GenMsgNrOfRepetitions" 0;
BA_DEF_DEF_  "GenMsgSendType" "cyclicX";
BA_DEF_DEF_  "GenMsgStartDelayTime" 0;
BA_DEF_DEF_  "GenMsgStartValue" "";
BA_DEF_DEF_  "NWM-Botschaft" "nein";
BA_DEF_DEF_  "TpTxIndex" 0;
BA_DEF_DEF_  "FlexKomComment" "";
BA_DEF_DEF_  "FlexKomIsMotorola" "nein";
BA_DEF_DEF_  "FlexKomSID" 0;
BA_DEF_DEF_  "FlexKomSigLaenge" 0;
BA_DEF_DEF_  "FlexKomSigName" "";
BA_DEF_DEF_  "FlexKomSigStartPos" 0;
BA_DEF_DEF_  "FlexKomSigStartValue" "";
BA_DEF_DEF_  "GenSigCycleTime" 0;
BA_DEF_DEF_  "GenSigCycleTimeActive" 0;
BA_DEF_DEF_  "GenSigSendType" "cyclicX";
BA_DEF_DEF_  "GenSigSNA" "";
BA_DEF_DEF_  "GenSigStartValue" 0;
BA_DEF_DEF_  "GenSigTimeout_AHLM" 0;
BA_DEF_DEF_  "GenSigTimeout_ASBS" 0;
BA_DEF_DEF_  "GenSigTimeout_CBC" 0;
BA_DEF_DEF_  "GenSigTimeout_DPDM" 0;
BA_DEF_DEF_  "GenSigTimeout_DTCM" 0;
BA_DEF_DEF_  "GenSigTimeout_EHPS" 0;
BA_DEF_DEF_  "GenSigTimeout_ESC" 0;
BA_DEF_DEF_  "GenSigTimeout_ESL" 0;
BA_DEF_DEF_  "GenSigTimeout_ESM" 0;
BA_DEF_DEF_  "GenSigTimeout_ETM" 0;
BA_DEF_DEF_  "GenSigTimeout_IC" 0;
BA_DEF_DEF_  "GenSigTimeout_OCM" 0;
BA_DEF_DEF_  "GenSigTimeout_ORC" 0;
BA_DEF_DEF_  "GenSigTimeout_PTS" 0;
BA_DEF_DEF_  "GenSigTimeout_RF_HUB" 0;
BA_DEF_DEF_  "GenSigTimeout_SCCM" 0;
BA_DEF_DEF_  "GenSigTimeout_TBM" 0;
BA_DEF_DEF_  "GenSigTimeout_TCM" 0;
BA_DEF_DEF_  "GenSigTimeout_TPM" 0;
BA_DEF_DEF_  "RID" "";
BA_DEF_DEF_  "SystemSignalLongSymbol" "";
BA_ "GenMsgStartValue" BO_ 838 "0000h";
BA_ "GenMsgSendType" BO_ 838 5;
BA_ "GenMsgNrOfRepetitions" BO_ 838 2;
BA_ "GenMsgDelayTime" BO_ 838 20;
BA_ "GenMsgCycleTime" BO_ 838 1000;
BA_ "GenMsgStartValue" BO_ 840 "0000000000000000h";
BA_ "GenMsgSendType" BO_ 840 1;
BA_ "GenMsgNrOfRepetitions" BO_ 840 2;
BA_ "GenMsgDelayTime" BO_ 840 20;
BA_ "GenMsgStartValue" BO_ 848 "FFFFFFFFFFFFFF3Fh";
BA_ "GenMsgNrOfRepetitions" BO_ 848 2;
BA_ "GenMsgDelayTime" BO_ 848 20;
BA_ "GenMsgCycleTime" BO_ 848 1000;
BA_ "GenMsgStartValue" BO_ 850 "0000000000000000h";
BA_ "GenMsgSendType" BO_ 850 1;
BA_ "GenMsgNrOfRepetitions" BO_ 850 2;
BA_ "GenMsgDelayTime" BO_ 850 20;
BA_ "GenMsgStartValue" BO_ 856 "FF000000h";
BA_ "GenMsgStartDelayTime" BO_ 856 50;
BA_ "GenMsgNrOfRepetitions" BO_ 856 2;
BA_ "GenMsgDelayTime" BO_ 856 20;
BA_ "GenMsgCycleTime" BO_ 856 1000;
BA_ "GenMsgStartValue" BO_ 860 "000000000FFFh";
BA_ "GenMsgSendType" BO_ 860 5;
BA_ "GenMsgNrOfRepetitions" BO_ 860 2;
BA_ "GenMsgDelayTime" BO_ 860 20;
BA_ "GenMsgCycleTime" BO_ 860 1000;
BA_ "GenMsgStartValue" BO_ 864 "0000000000000000h";
BA_ "GenMsgSendType" BO_ 864 1;
BA_ "GenMsgNrOfRepetitions" BO_ 864 2;
BA_ "GenMsgDelayTime" BO_ 864 20;
BA_ "GenMsgStartValue" BO_ 872 "0000000000000000h";
BA_ "GenMsgSendType" BO_ 872 1;
BA_ "GenMsgNrOfRepetitions" BO_ 872 2;
BA_ "GenMsgDelayTime" BO_ 872 20;
BA_ "GenMsgStartValue" BO_ 880 "0000000000000000h";
BA_ "GenMsgSendType" BO_ 880 1;
BA_ "GenMsgNrOfRepetitions" BO_ 880 2;
BA_ "GenMsgDelayTime" BO_ 880 20;
BA_ "GenMsgStartValue" BO_ 881 "0000000000000000h";
BA_ "GenMsgSendType" BO_ 881 5;
BA_ "GenMsgNrOfRepetitions" BO_ 881 2;
BA_ "GenMsgDelayTime" BO_ 881 20;
BA_ "GenMsgCycleTime" BO_ 881 1000;
BA_ "GenMsgStartValue" BO_ 886 "FFFF000000000FFFh";
BA_ "GenMsgStartDelayTime" BO_ 886 120;
BA_ "GenMsgSendType" BO_ 886 5;
BA_ "GenMsgNrOfRepetitions" BO_ 886 2;
BA_ "GenMsgDelayTime" BO_ 886 20;
BA_ "GenMsgCycleTime" BO_ 886 1000;
BA_ "GenMsgStartValue" BO_ 888 "0000000000000000h";
BA_ "GenMsgSendType" BO_ 888 1;
BA_ "GenMsgNrOfRepetitions" BO_ 888 2;
BA_ "GenMsgDelayTime" BO_ 888 20;
BA_ "GenMsgStartValue" BO_ 896 "0000000000000000h";
BA_ "GenMsgSendType" BO_ 896 1;
BA_ "GenMsgNrOfRepetitions" BO_ 896 2;
BA_ "GenMsgDelayTime" BO_ 896 20;
BA_ "GenMsgStartValue" BO_ 897 "033F000000000000h";
BA_ "GenMsgSendType" BO_ 897 5;
BA_ "GenMsgNrOfRepetitions" BO_ 897 2;
BA_ "GenMsgDelayTime" BO_ 897 20;
BA_ "GenMsgCycleTime" BO_ 897 2000;
BA_ "GenMsgStartValue" BO_ 898 "033F000000000000h";
BA_ "GenMsgSendType" BO_ 898 1;
BA_ "GenMsgNrOfRepetitions" BO_ 898 2;
BA_ "GenMsgDelayTime" BO_ 898 20;
BA_ "GenMsgStartValue" BO_ 904 "0000000000000000h";
BA_ "GenMsgSendType" BO_ 904 1;
BA_ "GenMsgNrOfRepetitions" BO_ 904 2;
BA_ "GenMsgDelayTime" BO_ 904 20;
BA_ "GenMsgStartValue" BO_ 906 "0300000000000000h";
BA_ "GenMsgSendType" BO_ 906 5;
BA_ "GenMsgNrOfRepetitions" BO_ 906 2;
BA_ "GenMsgDelayTime" BO_ 906 20;
BA_ "GenMsgCycleTime" BO_ 906 2000;
BA_ "GenMsgStartValue" BO_ 907 "0300000000000000h";
BA_ "GenMsgSendType" BO_ 907 1;
BA_ "GenMsgNrOfRepetitions" BO_ 907 2;
BA_ "GenMsgDelayTime" BO_ 907 20;
BA_ "GenMsgStartValue" BO_ 908 "FFFFFFFFFFFFFFFFh";
BA_ "GenMsgNrOfRepetitions" BO_ 908 2;
BA_ "GenMsgDelayTime" BO_ 908 20;
BA_ "GenMsgCycleTime" BO_ 908 1000;
BA_ "GenMsgStartValue" BO_ 910 "000000FFFF7F7F00h";
BA_ "GenMsgNrOfRepetitions" BO_ 910 2;
BA_ "GenMsgDelayTime" BO_ 910 20;
BA_ "GenMsgCycleTime" BO_ 910 2000;
BA_ "GenMsgStartValue" BO_ 912 "0000000000000000h";
BA_ "GenMsgSendType" BO_ 912 1;
BA_ "GenMsgNrOfRepetitions" BO_ 912 2;
BA_ "GenMsgDelayTime" BO_ 912 20;
BA_ "GenMsgStartValue" BO_ 913 "0000000000000000h";
BA_ "GenMsgNrOfRepetitions" BO_ 913 2;
BA_ "GenMsgDelayTime" BO_ 913 20;
BA_ "GenMsgCycleTime" BO_ 913 5000;
BA_ "GenMsgStartValue" BO_ 920 "0000000000000000h";
BA_ "GenMsgSendType" BO_ 920 1;
BA_ "GenMsgNrOfRepetitions" BO_ 920 2;
BA_ "GenMsgDelayTime" BO_ 920 20;
BA_ "GenMsgStartValue" BO_ 926 "030000h";
BA_ "GenMsgSendType" BO_ 926 5;
BA_ "GenMsgNrOfRepetitions" BO_ 926 2;
BA_ "GenMsgDelayTime" BO_ 926 20;
BA_ "GenMsgCycleTime" BO_ 926 2000;
BA_ "GenMsgStartValue" BO_ 927 "030000h";
BA_ "GenMsgSendType" BO_ 927 1;
BA_ "GenMsgNrOfRepetitions" BO_ 927 2;
BA_ "GenMsgDelayTime" BO_ 927 20;
BA_ "GenMsgStartValue" BO_ 928 "0000000000000000h";
BA_ "GenMsgSendType" BO_ 928 1;
BA_ "GenMsgNrOfRepetitions" BO_ 928 2;
BA_ "GenMsgDelayTime" BO_ 928 20;
BA_ "GenMsgStartValue" BO_ 929 "07FFFFFFFF004000h";
BA_ "GenMsgSendType" BO_ 929 5;
BA_ "GenMsgNrOfRepetitions" BO_ 929 2;
BA_ "GenMsgDelayTime" BO_ 929 20;
BA_ "GenMsgCycleTime" BO_ 929 1000;
BA_ "GenMsgStartValue" BO_ 936 "0000000000000000h";
BA_ "GenMsgSendType" BO_ 936 1;
BA_ "GenMsgNrOfRepetitions" BO_ 936 2;
BA_ "GenMsgDelayTime" BO_ 936 20;
BA_ "GenMsgStartValue" BO_ 937 "00FFFFFFFF60C003h";
BA_ "GenMsgStartDelayTime" BO_ 937 10;
BA_ "GenMsgSendType" BO_ 937 5;
BA_ "GenMsgNrOfRepetitions" BO_ 937 2;
BA_ "GenMsgDelayTime" BO_ 937 20;
BA_ "GenMsgCycleTime" BO_ 937 1000;
BA_ "GenMsgStartValue" BO_ 938 "0000000000000000h";
BA_ "GenMsgNrOfRepetitions" BO_ 938 2;
BA_ "GenMsgDelayTime" BO_ 938 20;
BA_ "GenMsgCycleTime" BO_ 938 1000;
BA_ "GenMsgStartValue" BO_ 939 "0000000000000000h";
BA_ "GenMsgStartDelayTime" BO_ 939 50;
BA_ "GenMsgNrOfRepetitions" BO_ 939 2;
BA_ "GenMsgDelayTime" BO_ 939 20;
BA_ "GenMsgCycleTime" BO_ 939 1000;
BA_ "GenMsgStartValue" BO_ 940 "00FF000000000000h";
BA_ "GenMsgStartDelayTime" BO_ 940 100;
BA_ "GenMsgNrOfRepetitions" BO_ 940 2;
BA_ "GenMsgDelayTime" BO_ 940 20;
BA_ "GenMsgCycleTime" BO_ 940 1000;
BA_ "RID" SG_ 838 AS_RF_CHIME_RQ "1245";
BA_ "GenSigSNA" SG_ 838 AS_RF_CHIME_RQ "0h";
BA_ "GenSigSendType" SG_ 838 AS_RF_CHIME_RQ 5;
BA_ "GenSigCycleTime" SG_ 838 AS_RF_CHIME_RQ 1000;
BA_ "FlexKomSigStartValue" SG_ 838 AS_RF_CHIME_RQ "0000h";
BA_ "FlexKomSigStartPos" SG_ 838 AS_RF_CHIME_RQ 7;
BA_ "FlexKomSigName" SG_ 838 AS_RF_CHIME_RQ "AS_CHIME_STAT";
BA_ "FlexKomSigLaenge" SG_ 838 AS_RF_CHIME_RQ 16;
BA_ "FlexKomSID" SG_ 838 AS_RF_CHIME_RQ 1016;
BA_ "FlexKomIsMotorola" SG_ 838 AS_RF_CHIME_RQ 1;
BA_ "FlexKomComment" SG_ 838 AS_RF_CHIME_RQ "AS chime status";
BA_ "RID" SG_ 838 AS_LF_CHIME_RQ "1121";
BA_ "GenSigSNA" SG_ 838 AS_LF_CHIME_RQ "0h";
BA_ "GenSigSendType" SG_ 838 AS_LF_CHIME_RQ 5;
BA_ "GenSigCycleTime" SG_ 838 AS_LF_CHIME_RQ 1000;
BA_ "FlexKomSigStartValue" SG_ 838 AS_LF_CHIME_RQ "0000h";
BA_ "FlexKomSigStartPos" SG_ 838 AS_LF_CHIME_RQ 7;
BA_ "FlexKomSigName" SG_ 838 AS_LF_CHIME_RQ "AS_CHIME_STAT";
BA_ "FlexKomSigLaenge" SG_ 838 AS_LF_CHIME_RQ 16;
BA_ "FlexKomSID" SG_ 838 AS_LF_CHIME_RQ 1016;
BA_ "FlexKomIsMotorola" SG_ 838 AS_LF_CHIME_RQ 1;
BA_ "FlexKomComment" SG_ 838 AS_LF_CHIME_RQ "AS chime status";
BA_ "RID" SG_ 838 AS_CHIME_TYPE "1056";
BA_ "GenSigTimeout_ORC" SG_ 838 AS_CHIME_TYPE 3500;
BA_ "GenSigTimeout_IC" SG_ 838 AS_CHIME_TYPE 10500;
BA_ "GenSigSNA" SG_ 838 AS_CHIME_TYPE "Fh";
BA_ "GenSigSendType" SG_ 838 AS_CHIME_TYPE 5;
BA_ "GenSigCycleTime" SG_ 838 AS_CHIME_TYPE 1000;
BA_ "FlexKomSigStartValue" SG_ 838 AS_CHIME_TYPE "0000h";
BA_ "FlexKomSigStartPos" SG_ 838 AS_CHIME_TYPE 7;
BA_ "FlexKomSigName" SG_ 838 AS_CHIME_TYPE "AS_CHIME_STAT";
BA_ "FlexKomSigLaenge" SG_ 838 AS_CHIME_TYPE 16;
BA_ "FlexKomSID" SG_ 838 AS_CHIME_TYPE 1016;
BA_ "FlexKomIsMotorola" SG_ 838 AS_CHIME_TYPE 1;
BA_ "FlexKomComment" SG_ 838 AS_CHIME_TYPE "AS chime status";
BA_ "RID" SG_ 838 AS_CHIME_REP_RATE "1192";
BA_ "GenSigSNA" SG_ 838 AS_CHIME_REP_RATE "0h";
BA_ "GenSigSendType" SG_ 838 AS_CHIME_REP_RATE 5;
BA_ "GenSigCycleTime" SG_ 838 AS_CHIME_REP_RATE 1000;
BA_ "FlexKomSigStartValue" SG_ 838 AS_CHIME_REP_RATE "0000h";
BA_ "FlexKomSigStartPos" SG_ 838 AS_CHIME_REP_RATE 7;
BA_ "FlexKomSigName" SG_ 838 AS_CHIME_REP_RATE "AS_CHIME_STAT";
BA_ "FlexKomSigLaenge" SG_ 838 AS_CHIME_REP_RATE 16;
BA_ "FlexKomSID" SG_ 838 AS_CHIME_REP_RATE 1016;
BA_ "FlexKomIsMotorola" SG_ 838 AS_CHIME_REP_RATE 1;
BA_ "FlexKomComment" SG_ 838 AS_CHIME_REP_RATE "AS chime status";
BA_ "GenSigSNA" SG_ 840 FailSafeError "FFFFh";
BA_ "GenSigSendType" SG_ 840 FailSafeError 1;
BA_ "FlexKomSigStartValue" SG_ 840 FailSafeError "0000h";
BA_ "FlexKomSigStartPos" SG_ 840 FailSafeError 7;
BA_ "FlexKomSigName" SG_ 840 FailSafeError "FailSafeError";
BA_ "FlexKomSigLaenge" SG_ 840 FailSafeError 16;
BA_ "FlexKomSID" SG_ 840 FailSafeError 13;
BA_ "FlexKomIsMotorola" SG_ 840 FailSafeError 1;
BA_ "FlexKomComment" SG_ 840 FailSafeError "Fail safe error";
BA_ "RID" SG_ 848 DateTmMinute "1174";
BA_ "GenSigTimeout_RF_HUB" SG_ 848 DateTmMinute 10500;
BA_ "GenSigTimeout_IC" SG_ 848 DateTmMinute 10500;
BA_ "GenSigStartValue" SG_ 848 DateTmMinute 255;
BA_ "GenSigSNA" SG_ 848 DateTmMinute "FFh";
BA_ "GenSigCycleTime" SG_ 848 DateTmMinute 1000;
BA_ "FlexKomSigStartValue" SG_ 848 DateTmMinute "FFFFFFh";
BA_ "FlexKomSigStartPos" SG_ 848 DateTmMinute 7;
BA_ "FlexKomSigName" SG_ 848 DateTmMinute "Clock";
BA_ "FlexKomSigLaenge" SG_ 848 DateTmMinute 24;
BA_ "FlexKomSID" SG_ 848 DateTmMinute 398;
BA_ "FlexKomIsMotorola" SG_ 848 DateTmMinute 1;
BA_ "FlexKomComment" SG_ 848 DateTmMinute "Time of day clock";
BA_ "RID" SG_ 848 DateTmHour "1116";
BA_ "GenSigTimeout_RF_HUB" SG_ 848 DateTmHour 10500;
BA_ "GenSigTimeout_IC" SG_ 848 DateTmHour 10500;
BA_ "GenSigStartValue" SG_ 848 DateTmHour 255;
BA_ "GenSigSNA" SG_ 848 DateTmHour "FFh";
BA_ "GenSigCycleTime" SG_ 848 DateTmHour 1000;
BA_ "FlexKomSigStartValue" SG_ 848 DateTmHour "FFFFFFh";
BA_ "FlexKomSigStartPos" SG_ 848 DateTmHour 7;
BA_ "FlexKomSigName" SG_ 848 DateTmHour "Clock";
BA_ "FlexKomSigLaenge" SG_ 848 DateTmHour 24;
BA_ "FlexKomSID" SG_ 848 DateTmHour 398;
BA_ "FlexKomIsMotorola" SG_ 848 DateTmHour 1;
BA_ "FlexKomComment" SG_ 848 DateTmHour "Time of day clock";
BA_ "RID" SG_ 848 DateTmYear "1218";
BA_ "GenSigTimeout_RF_HUB" SG_ 848 DateTmYear 10500;
BA_ "GenSigTimeout_IC" SG_ 848 DateTmYear 10500;
BA_ "GenSigStartValue" SG_ 848 DateTmYear 65535;
BA_ "GenSigSNA" SG_ 848 DateTmYear "FFFFh";
BA_ "GenSigCycleTime" SG_ 848 DateTmYear 1000;
BA_ "FlexKomSigStartValue" SG_ 848 DateTmYear "FFFFFFFFh";
BA_ "FlexKomSigStartPos" SG_ 848 DateTmYear 31;
BA_ "FlexKomSigName" SG_ 848 DateTmYear "DATE";
BA_ "FlexKomSigLaenge" SG_ 848 DateTmYear 32;
BA_ "FlexKomSID" SG_ 848 DateTmYear 645;
BA_ "FlexKomIsMotorola" SG_ 848 DateTmYear 1;
BA_ "FlexKomComment" SG_ 848 DateTmYear "DATE";
BA_ "RID" SG_ 848 DateTmMonth "1112";
BA_ "GenSigTimeout_RF_HUB" SG_ 848 DateTmMonth 10500;
BA_ "GenSigTimeout_IC" SG_ 848 DateTmMonth 10500;
BA_ "GenSigStartValue" SG_ 848 DateTmMonth 255;
BA_ "GenSigSNA" SG_ 848 DateTmMonth "FFh";
BA_ "GenSigCycleTime" SG_ 848 DateTmMonth 1000;
BA_ "FlexKomSigStartValue" SG_ 848 DateTmMonth "FFFFFFFFh";
BA_ "FlexKomSigStartPos" SG_ 848 DateTmMonth 31;
BA_ "FlexKomSigName" SG_ 848 DateTmMonth "DATE";
BA_ "FlexKomSigLaenge" SG_ 848 DateTmMonth 32;
BA_ "FlexKomSID" SG_ 848 DateTmMonth 645;
BA_ "FlexKomIsMotorola" SG_ 848 DateTmMonth 1;
BA_ "FlexKomComment" SG_ 848 DateTmMonth "DATE";
BA_ "RID" SG_ 848 DateTmDay "1029";
BA_ "GenSigTimeout_RF_HUB" SG_ 848 DateTmDay 10500;
BA_ "GenSigTimeout_IC" SG_ 848 DateTmDay 10500;
BA_ "GenSigStartValue" SG_ 848 DateTmDay 255;
BA_ "GenSigSNA" SG_ 848 DateTmDay "FFh";
BA_ "GenSigCycleTime" SG_ 848 DateTmDay 1000;
BA_ "FlexKomSigStartValue" SG_ 848 DateTmDay "FFFFFFFFh";
BA_ "FlexKomSigStartPos" SG_ 848 DateTmDay 31;
BA_ "FlexKomSigName" SG_ 848 DateTmDay "DATE";
BA_ "FlexKomSigLaenge" SG_ 848 DateTmDay 32;
BA_ "FlexKomSID" SG_ 848 DateTmDay 645;
BA_ "FlexKomIsMotorola" SG_ 848 DateTmDay 1;
BA_ "FlexKomComment" SG_ 848 DateTmDay "DATE";
BA_ "RID" SG_ 848 DateTmFormat "1111";
BA_ "GenSigTimeout_IC" SG_ 848 DateTmFormat 10500;
BA_ "GenSigStartValue" SG_ 848 DateTmFormat 7;
BA_ "GenSigSNA" SG_ 848 DateTmFormat "7h";
BA_ "GenSigCycleTime" SG_ 848 DateTmFormat 1000;
BA_ "FlexKomSigStartValue" SG_ 848 DateTmFormat "07h";
BA_ "FlexKomSigStartPos" SG_ 848 DateTmFormat 58;
BA_ "FlexKomSigName" SG_ 848 DateTmFormat "DateTmFormat";
BA_ "FlexKomSigLaenge" SG_ 848 DateTmFormat 3;
BA_ "FlexKomSID" SG_ 848 DateTmFormat 971;
BA_ "FlexKomIsMotorola" SG_ 848 DateTmFormat 1;
BA_ "FlexKomComment" SG_ 848 DateTmFormat "Date and Time Format";
BA_ "RID" SG_ 848 DateTmSec "1071";
BA_ "GenSigTimeout_RF_HUB" SG_ 848 DateTmSec 10500;
BA_ "GenSigTimeout_IC" SG_ 848 DateTmSec 10500;
BA_ "GenSigStartValue" SG_ 848 DateTmSec 255;
BA_ "GenSigSNA" SG_ 848 DateTmSec "FFh";
BA_ "GenSigCycleTime" SG_ 848 DateTmSec 1000;
BA_ "FlexKomSigStartValue" SG_ 848 DateTmSec "FFFFFFh";
BA_ "FlexKomSigStartPos" SG_ 848 DateTmSec 7;
BA_ "FlexKomSigName" SG_ 848 DateTmSec "Clock";
BA_ "FlexKomSigLaenge" SG_ 848 DateTmSec 24;
BA_ "FlexKomSID" SG_ 848 DateTmSec 398;
BA_ "FlexKomIsMotorola" SG_ 848 DateTmSec 1;
BA_ "FlexKomComment" SG_ 848 DateTmSec "Time of day clock";
BA_ "GenSigSNA" SG_ 850 ECM_APPL2 "0h";
BA_ "GenSigSendType" SG_ 850 ECM_APPL2 1;
BA_ "FlexKomSigStartValue" SG_ 850 ECM_APPL2 "0000000000000000h";
BA_ "FlexKomSigStartPos" SG_ 850 ECM_APPL2 7;
BA_ "FlexKomSigName" SG_ 850 ECM_APPL2 "ECM_APPL2";
BA_ "FlexKomSigLaenge" SG_ 850 ECM_APPL2 64;
BA_ "FlexKomSID" SG_ 850 ECM_APPL2 1110;
BA_ "FlexKomIsMotorola" SG_ 850 ECM_APPL2 1;
BA_ "FlexKomComment" SG_ 850 ECM_APPL2 "Application";
BA_ "RID" SG_ 856 CMP_DIR "289";
BA_ "GenSigTimeout_IC" SG_ 856 CMP_DIR 10500;
BA_ "GenSigStartValue" SG_ 856 CMP_DIR 15;
BA_ "GenSigSNA" SG_ 856 CMP_DIR "Fh";
BA_ "GenSigCycleTime" SG_ 856 CMP_DIR 1000;
BA_ "FlexKomSigStartValue" SG_ 856 CMP_DIR "0Fh";
BA_ "FlexKomSigStartPos" SG_ 856 CMP_DIR 3;
BA_ "FlexKomSigName" SG_ 856 CMP_DIR "CMP_DIR";
BA_ "FlexKomSigLaenge" SG_ 856 CMP_DIR 4;
BA_ "FlexKomSID" SG_ 856 CMP_DIR 817;
BA_ "FlexKomIsMotorola" SG_ 856 CMP_DIR 1;
BA_ "FlexKomComment" SG_ 856 CMP_DIR "Compass direction (WK/LX)";
BA_ "RID" SG_ 860 NAVPrsnt "1198";
BA_ "GenSigSNA" SG_ 860 NAVPrsnt "0h";
BA_ "GenSigSendType" SG_ 860 NAVPrsnt 5;
BA_ "GenSigCycleTime" SG_ 860 NAVPrsnt 1000;
BA_ "FlexKomSigStartValue" SG_ 860 NAVPrsnt "00000000h";
BA_ "FlexKomSigStartPos" SG_ 860 NAVPrsnt 7;
BA_ "FlexKomSigName" SG_ 860 NAVPrsnt "TURN_INFO";
BA_ "FlexKomSigLaenge" SG_ 860 NAVPrsnt 32;
BA_ "FlexKomSID" SG_ 860 NAVPrsnt 986;
BA_ "FlexKomIsMotorola" SG_ 860 NAVPrsnt 1;
BA_ "FlexKomComment" SG_ 860 NAVPrsnt "Navigation turn information packet";
BA_ "GenSigSNA" SG_ 864 ECM_APPL1 "0h";
BA_ "GenSigSendType" SG_ 864 ECM_APPL1 1;
BA_ "FlexKomSigStartValue" SG_ 864 ECM_APPL1 "0000000000000000h";
BA_ "FlexKomSigStartPos" SG_ 864 ECM_APPL1 7;
BA_ "FlexKomSigName" SG_ 864 ECM_APPL1 "ECM_APPL1";
BA_ "FlexKomSigLaenge" SG_ 864 ECM_APPL1 64;
BA_ "FlexKomSID" SG_ 864 ECM_APPL1 780;
BA_ "FlexKomIsMotorola" SG_ 864 ECM_APPL1 1;
BA_ "FlexKomComment" SG_ 864 ECM_APPL1 "Application";
BA_ "GenSigSNA" SG_ 872 TCM_HSA "0h";
BA_ "GenSigSendType" SG_ 872 TCM_HSA 1;
BA_ "FlexKomSigStartValue" SG_ 872 TCM_HSA "0000000000000000h";
BA_ "FlexKomSigStartPos" SG_ 872 TCM_HSA 7;
BA_ "FlexKomSigName" SG_ 872 TCM_HSA "TCM_HSA";
BA_ "FlexKomSigLaenge" SG_ 872 TCM_HSA 64;
BA_ "FlexKomSID" SG_ 872 TCM_HSA 799;
BA_ "FlexKomIsMotorola" SG_ 872 TCM_HSA 1;
BA_ "FlexKomComment" SG_ 872 TCM_HSA "Manual control at test bench";
BA_ "GenSigSNA" SG_ 880 ECM_APPL3 "0h";
BA_ "GenSigSendType" SG_ 880 ECM_APPL3 1;
BA_ "FlexKomSigStartValue" SG_ 880 ECM_APPL3 "0000000000000000h";
BA_ "FlexKomSigStartPos" SG_ 880 ECM_APPL3 7;
BA_ "FlexKomSigName" SG_ 880 ECM_APPL3 "ECM_APPL3";
BA_ "FlexKomSigLaenge" SG_ 880 ECM_APPL3 64;
BA_ "FlexKomSID" SG_ 880 ECM_APPL3 781;
BA_ "FlexKomIsMotorola" SG_ 880 ECM_APPL3 1;
BA_ "FlexKomComment" SG_ 880 ECM_APPL3 "CCP synchronous - TDC event DAQ";
BA_ "GenSigTimeout_IC" SG_ 881 SwayBar_Sts 10500;
BA_ "GenSigSNA" SG_ 881 SwayBar_Sts "3h";
BA_ "GenSigSendType" SG_ 881 SwayBar_Sts 5;
BA_ "GenSigCycleTime" SG_ 881 SwayBar_Sts 1000;
BA_ "FlexKomSigStartValue" SG_ 881 SwayBar_Sts "0000000000000000h";
BA_ "FlexKomSigStartPos" SG_ 881 SwayBar_Sts 7;
BA_ "FlexKomSigName" SG_ 881 SwayBar_Sts "ASBS_1_Pkt";
BA_ "FlexKomSigLaenge" SG_ 881 SwayBar_Sts 64;
BA_ "FlexKomSID" SG_ 881 SwayBar_Sts 2631;
BA_ "FlexKomIsMotorola" SG_ 881 SwayBar_Sts 1;
BA_ "FlexKomComment" SG_ 881 SwayBar_Sts "ASBS message 1 packet";
BA_ "GenSigTimeout_IC" SG_ 881 SwayBarEVICDisplay 10500;
BA_ "GenSigSNA" SG_ 881 SwayBarEVICDisplay "Fh";
BA_ "GenSigSendType" SG_ 881 SwayBarEVICDisplay 5;
BA_ "GenSigCycleTime" SG_ 881 SwayBarEVICDisplay 1000;
BA_ "FlexKomSigStartValue" SG_ 881 SwayBarEVICDisplay "0000000000000000h";
BA_ "FlexKomSigStartPos" SG_ 881 SwayBarEVICDisplay 7;
BA_ "FlexKomSigName" SG_ 881 SwayBarEVICDisplay "ASBS_1_Pkt";
BA_ "FlexKomSigLaenge" SG_ 881 SwayBarEVICDisplay 64;
BA_ "FlexKomSID" SG_ 881 SwayBarEVICDisplay 2631;
BA_ "FlexKomIsMotorola" SG_ 881 SwayBarEVICDisplay 1;
BA_ "FlexKomComment" SG_ 881 SwayBarEVICDisplay "ASBS message 1 packet";
BA_ "GenSigTimeout_CBC" SG_ 881 SwayBar_LEDRq 10500;
BA_ "GenSigSNA" SG_ 881 SwayBar_LEDRq "3h";
BA_ "GenSigSendType" SG_ 881 SwayBar_LEDRq 5;
BA_ "GenSigCycleTime" SG_ 881 SwayBar_LEDRq 1000;
BA_ "FlexKomSigStartValue" SG_ 881 SwayBar_LEDRq "0000000000000000h";
BA_ "FlexKomSigStartPos" SG_ 881 SwayBar_LEDRq 7;
BA_ "FlexKomSigName" SG_ 881 SwayBar_LEDRq "ASBS_1_Pkt";
BA_ "FlexKomSigLaenge" SG_ 881 SwayBar_LEDRq 64;
BA_ "FlexKomSID" SG_ 881 SwayBar_LEDRq 2631;
BA_ "FlexKomIsMotorola" SG_ 881 SwayBar_LEDRq 1;
BA_ "FlexKomComment" SG_ 881 SwayBar_LEDRq "ASBS message 1 packet";
BA_ "RID" SG_ 886 DIST_TO_TURN_2 "6607";
BA_ "GenSigSNA" SG_ 886 DIST_TO_TURN_2 "FFFFh";
BA_ "GenSigSendType" SG_ 886 DIST_TO_TURN_2 5;
BA_ "GenSigCycleTime" SG_ 886 DIST_TO_TURN_2 1000;
BA_ "FlexKomSigStartValue" SG_ 886 DIST_TO_TURN_2 "FFFF000000000FFFh";
BA_ "FlexKomSigStartPos" SG_ 886 DIST_TO_TURN_2 7;
BA_ "FlexKomSigName" SG_ 886 DIST_TO_TURN_2 "DIRECT_INFO2";
BA_ "FlexKomSigLaenge" SG_ 886 DIST_TO_TURN_2 64;
BA_ "FlexKomSID" SG_ 886 DIST_TO_TURN_2 3117;
BA_ "FlexKomIsMotorola" SG_ 886 DIST_TO_TURN_2 1;
BA_ "FlexKomComment" SG_ 886 DIST_TO_TURN_2 "DIRECT_INFO2";
BA_ "RID" SG_ 886 UNITS_2 "6601";
BA_ "GenSigSNA" SG_ 886 UNITS_2 "7h";
BA_ "GenSigSendType" SG_ 886 UNITS_2 5;
BA_ "GenSigCycleTime" SG_ 886 UNITS_2 1000;
BA_ "FlexKomSigStartValue" SG_ 886 UNITS_2 "FFFF000000000FFFh";
BA_ "FlexKomSigStartPos" SG_ 886 UNITS_2 7;
BA_ "FlexKomSigName" SG_ 886 UNITS_2 "DIRECT_INFO2";
BA_ "FlexKomSigLaenge" SG_ 886 UNITS_2 64;
BA_ "FlexKomSID" SG_ 886 UNITS_2 3117;
BA_ "FlexKomIsMotorola" SG_ 886 UNITS_2 1;
BA_ "FlexKomComment" SG_ 886 UNITS_2 "DIRECT_INFO2";
BA_ "RID" SG_ 886 T_BY_T_ON_2 "6600";
BA_ "GenSigSNA" SG_ 886 T_BY_T_ON_2 "0h";
BA_ "GenSigSendType" SG_ 886 T_BY_T_ON_2 5;
BA_ "GenSigCycleTime" SG_ 886 T_BY_T_ON_2 1000;
BA_ "FlexKomSigStartValue" SG_ 886 T_BY_T_ON_2 "FFFF000000000FFFh";
BA_ "FlexKomSigStartPos" SG_ 886 T_BY_T_ON_2 7;
BA_ "FlexKomSigName" SG_ 886 T_BY_T_ON_2 "DIRECT_INFO2";
BA_ "FlexKomSigLaenge" SG_ 886 T_BY_T_ON_2 64;
BA_ "FlexKomSID" SG_ 886 T_BY_T_ON_2 3117;
BA_ "FlexKomIsMotorola" SG_ 886 T_BY_T_ON_2 1;
BA_ "FlexKomComment" SG_ 886 T_BY_T_ON_2 "DIRECT_INFO2";
BA_ "RID" SG_ 886 TURN_COMP_2 "6606";
BA_ "GenSigSNA" SG_ 886 TURN_COMP_2 "0h";
BA_ "GenSigSendType" SG_ 886 TURN_COMP_2 5;
BA_ "GenSigCycleTime" SG_ 886 TURN_COMP_2 1000;
BA_ "FlexKomSigStartValue" SG_ 886 TURN_COMP_2 "FFFF000000000FFFh";
BA_ "FlexKomSigStartPos" SG_ 886 TURN_COMP_2 7;
BA_ "FlexKomSigName" SG_ 886 TURN_COMP_2 "DIRECT_INFO2";
BA_ "FlexKomSigLaenge" SG_ 886 TURN_COMP_2 64;
BA_ "FlexKomSID" SG_ 886 TURN_COMP_2 3117;
BA_ "FlexKomIsMotorola" SG_ 886 TURN_COMP_2 1;
BA_ "FlexKomComment" SG_ 886 TURN_COMP_2 "DIRECT_INFO2";
BA_ "RID" SG_ 886 NAV_ARROW_2 "6605";
BA_ "GenSigSNA" SG_ 886 NAV_ARROW_2 "0h";
BA_ "GenSigSendType" SG_ 886 NAV_ARROW_2 5;
BA_ "GenSigCycleTime" SG_ 886 NAV_ARROW_2 1000;
BA_ "FlexKomSigStartValue" SG_ 886 NAV_ARROW_2 "FFFF000000000FFFh";
BA_ "FlexKomSigStartPos" SG_ 886 NAV_ARROW_2 7;
BA_ "FlexKomSigName" SG_ 886 NAV_ARROW_2 "DIRECT_INFO2";
BA_ "FlexKomSigLaenge" SG_ 886 NAV_ARROW_2 64;
BA_ "FlexKomSID" SG_ 886 NAV_ARROW_2 3117;
BA_ "FlexKomIsMotorola" SG_ 886 NAV_ARROW_2 1;
BA_ "FlexKomComment" SG_ 886 NAV_ARROW_2 "DIRECT_INFO2";
BA_ "GenSigSNA" SG_ 888 TCM_HSB "0h";
BA_ "GenSigSendType" SG_ 888 TCM_HSB 1;
BA_ "FlexKomSigStartValue" SG_ 888 TCM_HSB "0000000000000000h";
BA_ "FlexKomSigStartPos" SG_ 888 TCM_HSB 7;
BA_ "FlexKomSigName" SG_ 888 TCM_HSB "TCM_HSB";
BA_ "FlexKomSigLaenge" SG_ 888 TCM_HSB 64;
BA_ "FlexKomSID" SG_ 888 TCM_HSB 800;
BA_ "FlexKomIsMotorola" SG_ 888 TCM_HSB 1;
BA_ "FlexKomComment" SG_ 888 TCM_HSB "Manual control at test bench";
BA_ "GenSigSNA" SG_ 896 ECM_APPL4 "0h";
BA_ "GenSigSendType" SG_ 896 ECM_APPL4 1;
BA_ "FlexKomSigStartValue" SG_ 896 ECM_APPL4 "0000000000000000h";
BA_ "FlexKomSigStartPos" SG_ 896 ECM_APPL4 7;
BA_ "FlexKomSigName" SG_ 896 ECM_APPL4 "ECM_APPL4";
BA_ "FlexKomSigLaenge" SG_ 896 ECM_APPL4 64;
BA_ "FlexKomSID" SG_ 896 ECM_APPL4 782;
BA_ "FlexKomIsMotorola" SG_ 896 ECM_APPL4 1;
BA_ "FlexKomComment" SG_ 896 ECM_APPL4 "CCP 5ms DAQ  (from ENGINE to external tool)";
BA_ "GenSigTimeout_ORC" SG_ 897 VC_PBTyp 7000;
BA_ "GenSigSNA" SG_ 897 VC_PBTyp "7h";
BA_ "GenSigSendType" SG_ 897 VC_PBTyp 5;
BA_ "GenSigCycleTime" SG_ 897 VC_PBTyp 2000;
BA_ "FlexKomSigStartValue" SG_ 897 VC_PBTyp "033F000000000000h";
BA_ "FlexKomSigStartPos" SG_ 897 VC_PBTyp 7;
BA_ "FlexKomSigName" SG_ 897 VC_PBTyp "VehCfg7_Pkt";
BA_ "FlexKomSigLaenge" SG_ 897 VC_PBTyp 64;
BA_ "FlexKomSID" SG_ 897 VC_PBTyp 2026;
BA_ "FlexKomIsMotorola" SG_ 897 VC_PBTyp 1;
BA_ "FlexKomComment" SG_ 897 VC_PBTyp "Vehicle Configuration 7 Packet";
BA_ "GenSigTimeout_IC" SG_ 897 VC_TPMS_Configuration 21000;
BA_ "GenSigSNA" SG_ 897 VC_TPMS_Configuration "7h";
BA_ "GenSigSendType" SG_ 897 VC_TPMS_Configuration 5;
BA_ "GenSigCycleTime" SG_ 897 VC_TPMS_Configuration 2000;
BA_ "FlexKomSigStartValue" SG_ 897 VC_TPMS_Configuration "033F000000000000h";
BA_ "FlexKomSigStartPos" SG_ 897 VC_TPMS_Configuration 7;
BA_ "FlexKomSigName" SG_ 897 VC_TPMS_Configuration "VehCfg7_Pkt";
BA_ "FlexKomSigLaenge" SG_ 897 VC_TPMS_Configuration 64;
BA_ "FlexKomSID" SG_ 897 VC_TPMS_Configuration 2026;
BA_ "FlexKomIsMotorola" SG_ 897 VC_TPMS_Configuration 1;
BA_ "FlexKomComment" SG_ 897 VC_TPMS_Configuration "Vehicle Configuration 7 Packet";
BA_ "GenSigSNA" SG_ 897 VC_SmartAlternator "0h";
BA_ "GenSigSendType" SG_ 897 VC_SmartAlternator 5;
BA_ "GenSigCycleTime" SG_ 897 VC_SmartAlternator 2000;
BA_ "FlexKomSigStartValue" SG_ 897 VC_SmartAlternator "033F000000000000h";
BA_ "FlexKomSigStartPos" SG_ 897 VC_SmartAlternator 7;
BA_ "FlexKomSigName" SG_ 897 VC_SmartAlternator "VehCfg7_Pkt";
BA_ "FlexKomSigLaenge" SG_ 897 VC_SmartAlternator 64;
BA_ "FlexKomSID" SG_ 897 VC_SmartAlternator 2026;
BA_ "FlexKomIsMotorola" SG_ 897 VC_SmartAlternator 1;
BA_ "FlexKomComment" SG_ 897 VC_SmartAlternator "Vehicle Configuration 7 Packet";
BA_ "GenSigTimeout_ORC" SG_ 897 VC_HybridType 7000;
BA_ "GenSigSNA" SG_ 897 VC_HybridType "0h";
BA_ "GenSigSendType" SG_ 897 VC_HybridType 5;
BA_ "GenSigCycleTime" SG_ 897 VC_HybridType 2000;
BA_ "FlexKomSigStartValue" SG_ 897 VC_HybridType "033F000000000000h";
BA_ "FlexKomSigStartPos" SG_ 897 VC_HybridType 7;
BA_ "FlexKomSigName" SG_ 897 VC_HybridType "VehCfg7_Pkt";
BA_ "FlexKomSigLaenge" SG_ 897 VC_HybridType 64;
BA_ "FlexKomSID" SG_ 897 VC_HybridType 2026;
BA_ "FlexKomIsMotorola" SG_ 897 VC_HybridType 1;
BA_ "FlexKomComment" SG_ 897 VC_HybridType "Vehicle Configuration 7 Packet";
BA_ "GenSigSNA" SG_ 897 VC_TSBM_Prsnt "0h";
BA_ "GenSigSendType" SG_ 897 VC_TSBM_Prsnt 5;
BA_ "GenSigCycleTime" SG_ 897 VC_TSBM_Prsnt 2000;
BA_ "FlexKomSigStartValue" SG_ 897 VC_TSBM_Prsnt "033F000000000000h";
BA_ "FlexKomSigStartPos" SG_ 897 VC_TSBM_Prsnt 7;
BA_ "FlexKomSigName" SG_ 897 VC_TSBM_Prsnt "VehCfg7_Pkt";
BA_ "FlexKomSigLaenge" SG_ 897 VC_TSBM_Prsnt 64;
BA_ "FlexKomSID" SG_ 897 VC_TSBM_Prsnt 2026;
BA_ "FlexKomIsMotorola" SG_ 897 VC_TSBM_Prsnt 1;
BA_ "FlexKomComment" SG_ 897 VC_TSBM_Prsnt "Vehicle Configuration 7 Packet";
BA_ "GenSigSNA" SG_ 897 VC_ADR_PRSNT "0h";
BA_ "GenSigSendType" SG_ 897 VC_ADR_PRSNT 5;
BA_ "GenSigCycleTime" SG_ 897 VC_ADR_PRSNT 2000;
BA_ "FlexKomSigStartValue" SG_ 897 VC_ADR_PRSNT "033F000000000000h";
BA_ "FlexKomSigStartPos" SG_ 897 VC_ADR_PRSNT 7;
BA_ "FlexKomSigName" SG_ 897 VC_ADR_PRSNT "VehCfg7_Pkt";
BA_ "FlexKomSigLaenge" SG_ 897 VC_ADR_PRSNT 64;
BA_ "FlexKomSID" SG_ 897 VC_ADR_PRSNT 2026;
BA_ "FlexKomIsMotorola" SG_ 897 VC_ADR_PRSNT 1;
BA_ "FlexKomComment" SG_ 897 VC_ADR_PRSNT "Vehicle Configuration 7 Packet";
BA_ "GenSigSNA" SG_ 897 VC_Temp_Display_Resolution "0h";
BA_ "GenSigSendType" SG_ 897 VC_Temp_Display_Resolution 5;
BA_ "GenSigCycleTime" SG_ 897 VC_Temp_Display_Resolution 2000;
BA_ "FlexKomSigStartValue" SG_ 897 VC_Temp_Display_Resolution "033F000000000000h";
BA_ "FlexKomSigStartPos" SG_ 897 VC_Temp_Display_Resolution 7;
BA_ "FlexKomSigName" SG_ 897 VC_Temp_Display_Resolution "VehCfg7_Pkt";
BA_ "FlexKomSigLaenge" SG_ 897 VC_Temp_Display_Resolution 64;
BA_ "FlexKomSID" SG_ 897 VC_Temp_Display_Resolution 2026;
BA_ "FlexKomIsMotorola" SG_ 897 VC_Temp_Display_Resolution 1;
BA_ "FlexKomComment" SG_ 897 VC_Temp_Display_Resolution "Vehicle Configuration 7 Packet";
BA_ "GenSigSNA" SG_ 897 VC_AGSprsnt "0h";
BA_ "GenSigSendType" SG_ 897 VC_AGSprsnt 5;
BA_ "GenSigCycleTime" SG_ 897 VC_AGSprsnt 2000;
BA_ "FlexKomSigStartValue" SG_ 897 VC_AGSprsnt "033F000000000000h";
BA_ "FlexKomSigStartPos" SG_ 897 VC_AGSprsnt 7;
BA_ "FlexKomSigName" SG_ 897 VC_AGSprsnt "VehCfg7_Pkt";
BA_ "FlexKomSigLaenge" SG_ 897 VC_AGSprsnt 64;
BA_ "FlexKomSID" SG_ 897 VC_AGSprsnt 2026;
BA_ "FlexKomIsMotorola" SG_ 897 VC_AGSprsnt 1;
BA_ "FlexKomComment" SG_ 897 VC_AGSprsnt "Vehicle Configuration 7 Packet";
BA_ "GenSigSNA" SG_ 897 VC_PTCPrsnt "0h";
BA_ "GenSigSendType" SG_ 897 VC_PTCPrsnt 5;
BA_ "GenSigCycleTime" SG_ 897 VC_PTCPrsnt 2000;
BA_ "FlexKomSigStartValue" SG_ 897 VC_PTCPrsnt "033F000000000000h";
BA_ "FlexKomSigStartPos" SG_ 897 VC_PTCPrsnt 7;
BA_ "FlexKomSigName" SG_ 897 VC_PTCPrsnt "VehCfg7_Pkt";
BA_ "FlexKomSigLaenge" SG_ 897 VC_PTCPrsnt 64;
BA_ "FlexKomSID" SG_ 897 VC_PTCPrsnt 2026;
BA_ "FlexKomIsMotorola" SG_ 897 VC_PTCPrsnt 1;
BA_ "FlexKomComment" SG_ 897 VC_PTCPrsnt "Vehicle Configuration 7 Packet";
BA_ "GenSigSNA" SG_ 897 VC_Glovebox "0h";
BA_ "GenSigSendType" SG_ 897 VC_Glovebox 5;
BA_ "GenSigCycleTime" SG_ 897 VC_Glovebox 2000;
BA_ "FlexKomSigStartValue" SG_ 897 VC_Glovebox "033F000000000000h";
BA_ "FlexKomSigStartPos" SG_ 897 VC_Glovebox 7;
BA_ "FlexKomSigName" SG_ 897 VC_Glovebox "VehCfg7_Pkt";
BA_ "FlexKomSigLaenge" SG_ 897 VC_Glovebox 64;
BA_ "FlexKomSID" SG_ 897 VC_Glovebox 2026;
BA_ "FlexKomIsMotorola" SG_ 897 VC_Glovebox 1;
BA_ "FlexKomComment" SG_ 897 VC_Glovebox "Vehicle Configuration 7 Packet";
BA_ "GenSigTimeout_IC" SG_ 897 VC_MOC_Type 21000;
BA_ "GenSigSNA" SG_ 897 VC_MOC_Type "0h";
BA_ "GenSigSendType" SG_ 897 VC_MOC_Type 5;
BA_ "GenSigCycleTime" SG_ 897 VC_MOC_Type 2000;
BA_ "FlexKomSigStartValue" SG_ 897 VC_MOC_Type "033F000000000000h";
BA_ "FlexKomSigStartPos" SG_ 897 VC_MOC_Type 7;
BA_ "FlexKomSigName" SG_ 897 VC_MOC_Type "VehCfg7_Pkt";
BA_ "FlexKomSigLaenge" SG_ 897 VC_MOC_Type 64;
BA_ "FlexKomSID" SG_ 897 VC_MOC_Type 2026;
BA_ "FlexKomIsMotorola" SG_ 897 VC_MOC_Type 1;
BA_ "FlexKomComment" SG_ 897 VC_MOC_Type "Vehicle Configuration 7 Packet";
BA_ "GenSigSNA" SG_ 897 VC_SUNR_Prsnt "0h";
BA_ "GenSigSendType" SG_ 897 VC_SUNR_Prsnt 5;
BA_ "GenSigCycleTime" SG_ 897 VC_SUNR_Prsnt 2000;
BA_ "FlexKomSigStartValue" SG_ 897 VC_SUNR_Prsnt "033F000000000000h";
BA_ "FlexKomSigStartPos" SG_ 897 VC_SUNR_Prsnt 7;
BA_ "FlexKomSigName" SG_ 897 VC_SUNR_Prsnt "VehCfg7_Pkt";
BA_ "FlexKomSigLaenge" SG_ 897 VC_SUNR_Prsnt 64;
BA_ "FlexKomSID" SG_ 897 VC_SUNR_Prsnt 2026;
BA_ "FlexKomIsMotorola" SG_ 897 VC_SUNR_Prsnt 1;
BA_ "FlexKomComment" SG_ 897 VC_SUNR_Prsnt "Vehicle Configuration 7 Packet";
BA_ "GenSigSNA" SG_ 897 VC_Brake_Type "0h";
BA_ "GenSigSendType" SG_ 897 VC_Brake_Type 5;
BA_ "GenSigCycleTime" SG_ 897 VC_Brake_Type 2000;
BA_ "FlexKomSigStartValue" SG_ 897 VC_Brake_Type "033F000000000000h";
BA_ "FlexKomSigStartPos" SG_ 897 VC_Brake_Type 7;
BA_ "FlexKomSigName" SG_ 897 VC_Brake_Type "VehCfg7_Pkt";
BA_ "FlexKomSigLaenge" SG_ 897 VC_Brake_Type 64;
BA_ "FlexKomSID" SG_ 897 VC_Brake_Type 2026;
BA_ "FlexKomIsMotorola" SG_ 897 VC_Brake_Type 1;
BA_ "FlexKomComment" SG_ 897 VC_Brake_Type "Vehicle Configuration 7 Packet";
BA_ "GenSigSNA" SG_ 897 VC_Suspension_Type "0h";
BA_ "GenSigSendType" SG_ 897 VC_Suspension_Type 5;
BA_ "GenSigCycleTime" SG_ 897 VC_Suspension_Type 2000;
BA_ "FlexKomSigStartValue" SG_ 897 VC_Suspension_Type "033F000000000000h";
BA_ "FlexKomSigStartPos" SG_ 897 VC_Suspension_Type 7;
BA_ "FlexKomSigName" SG_ 897 VC_Suspension_Type "VehCfg7_Pkt";
BA_ "FlexKomSigLaenge" SG_ 897 VC_Suspension_Type 64;
BA_ "FlexKomSID" SG_ 897 VC_Suspension_Type 2026;
BA_ "FlexKomIsMotorola" SG_ 897 VC_Suspension_Type 1;
BA_ "FlexKomComment" SG_ 897 VC_Suspension_Type "Vehicle Configuration 7 Packet";
BA_ "GenSigSNA" SG_ 897 VC_GlareFree_Prsnt "0h";
BA_ "GenSigSendType" SG_ 897 VC_GlareFree_Prsnt 5;
BA_ "GenSigCycleTime" SG_ 897 VC_GlareFree_Prsnt 2000;
BA_ "FlexKomSigStartValue" SG_ 897 VC_GlareFree_Prsnt "033F000000000000h";
BA_ "FlexKomSigStartPos" SG_ 897 VC_GlareFree_Prsnt 7;
BA_ "FlexKomSigName" SG_ 897 VC_GlareFree_Prsnt "VehCfg7_Pkt";
BA_ "FlexKomSigLaenge" SG_ 897 VC_GlareFree_Prsnt 64;
BA_ "FlexKomSID" SG_ 897 VC_GlareFree_Prsnt 2026;
BA_ "FlexKomIsMotorola" SG_ 897 VC_GlareFree_Prsnt 1;
BA_ "FlexKomComment" SG_ 897 VC_GlareFree_Prsnt "Vehicle Configuration 7 Packet";
BA_ "GenSigSNA" SG_ 897 VC_PAD_Lamp_Ctrl "0h";
BA_ "GenSigSendType" SG_ 897 VC_PAD_Lamp_Ctrl 5;
BA_ "GenSigCycleTime" SG_ 897 VC_PAD_Lamp_Ctrl 2000;
BA_ "FlexKomSigStartValue" SG_ 897 VC_PAD_Lamp_Ctrl "033F000000000000h";
BA_ "FlexKomSigStartPos" SG_ 897 VC_PAD_Lamp_Ctrl 7;
BA_ "FlexKomSigName" SG_ 897 VC_PAD_Lamp_Ctrl "VehCfg7_Pkt";
BA_ "FlexKomSigLaenge" SG_ 897 VC_PAD_Lamp_Ctrl 64;
BA_ "FlexKomSID" SG_ 897 VC_PAD_Lamp_Ctrl 2026;
BA_ "FlexKomIsMotorola" SG_ 897 VC_PAD_Lamp_Ctrl 1;
BA_ "FlexKomComment" SG_ 897 VC_PAD_Lamp_Ctrl "Vehicle Configuration 7 Packet";
BA_ "GenSigSNA" SG_ 897 VC_Vehicle_Package "0h";
BA_ "GenSigSendType" SG_ 897 VC_Vehicle_Package 5;
BA_ "GenSigCycleTime" SG_ 897 VC_Vehicle_Package 2000;
BA_ "FlexKomSigStartValue" SG_ 897 VC_Vehicle_Package "033F000000000000h";
BA_ "FlexKomSigStartPos" SG_ 897 VC_Vehicle_Package 7;
BA_ "FlexKomSigName" SG_ 897 VC_Vehicle_Package "VehCfg7_Pkt";
BA_ "FlexKomSigLaenge" SG_ 897 VC_Vehicle_Package 64;
BA_ "FlexKomSID" SG_ 897 VC_Vehicle_Package 2026;
BA_ "FlexKomIsMotorola" SG_ 897 VC_Vehicle_Package 1;
BA_ "FlexKomComment" SG_ 897 VC_Vehicle_Package "Vehicle Configuration 7 Packet";
BA_ "GenSigSNA" SG_ 897 VC_TrafficSignInfo "0h";
BA_ "GenSigSendType" SG_ 897 VC_TrafficSignInfo 5;
BA_ "GenSigCycleTime" SG_ 897 VC_TrafficSignInfo 2000;
BA_ "FlexKomSigStartValue" SG_ 897 VC_TrafficSignInfo "033F000000000000h";
BA_ "FlexKomSigStartPos" SG_ 897 VC_TrafficSignInfo 7;
BA_ "FlexKomSigName" SG_ 897 VC_TrafficSignInfo "VehCfg7_Pkt";
BA_ "FlexKomSigLaenge" SG_ 897 VC_TrafficSignInfo 64;
BA_ "FlexKomSID" SG_ 897 VC_TrafficSignInfo 2026;
BA_ "FlexKomIsMotorola" SG_ 897 VC_TrafficSignInfo 1;
BA_ "FlexKomComment" SG_ 897 VC_TrafficSignInfo "Vehicle Configuration 7 Packet";
BA_ "GenSigSNA" SG_ 897 VC_LaneCentering "0h";
BA_ "GenSigSendType" SG_ 897 VC_LaneCentering 5;
BA_ "GenSigCycleTime" SG_ 897 VC_LaneCentering 2000;
BA_ "FlexKomSigStartValue" SG_ 897 VC_LaneCentering "033F000000000000h";
BA_ "FlexKomSigStartPos" SG_ 897 VC_LaneCentering 7;
BA_ "FlexKomSigName" SG_ 897 VC_LaneCentering "VehCfg7_Pkt";
BA_ "FlexKomSigLaenge" SG_ 897 VC_LaneCentering 64;
BA_ "FlexKomSID" SG_ 897 VC_LaneCentering 2026;
BA_ "FlexKomIsMotorola" SG_ 897 VC_LaneCentering 1;
BA_ "FlexKomComment" SG_ 897 VC_LaneCentering "Vehicle Configuration 7 Packet";
BA_ "GenSigSNA" SG_ 897 VC_LDW_Audio "0h";
BA_ "GenSigSendType" SG_ 897 VC_LDW_Audio 5;
BA_ "GenSigCycleTime" SG_ 897 VC_LDW_Audio 2000;
BA_ "FlexKomSigStartValue" SG_ 897 VC_LDW_Audio "033F000000000000h";
BA_ "FlexKomSigStartPos" SG_ 897 VC_LDW_Audio 7;
BA_ "FlexKomSigName" SG_ 897 VC_LDW_Audio "VehCfg7_Pkt";
BA_ "FlexKomSigLaenge" SG_ 897 VC_LDW_Audio 64;
BA_ "FlexKomSID" SG_ 897 VC_LDW_Audio 2026;
BA_ "FlexKomIsMotorola" SG_ 897 VC_LDW_Audio 1;
BA_ "FlexKomComment" SG_ 897 VC_LDW_Audio "Vehicle Configuration 7 Packet";
BA_ "GenSigTimeout_ORC" SG_ 897 VC_VehCfg7_Stat 7000;
BA_ "GenSigTimeout_IC" SG_ 897 VC_VehCfg7_Stat 21000;
BA_ "GenSigStartValue" SG_ 897 VC_VehCfg7_Stat 3;
BA_ "GenSigSNA" SG_ 897 VC_VehCfg7_Stat "3h";
BA_ "GenSigSendType" SG_ 897 VC_VehCfg7_Stat 5;
BA_ "GenSigCycleTime" SG_ 897 VC_VehCfg7_Stat 2000;
BA_ "FlexKomSigStartValue" SG_ 897 VC_VehCfg7_Stat "033F000000000000h";
BA_ "FlexKomSigStartPos" SG_ 897 VC_VehCfg7_Stat 7;
BA_ "FlexKomSigName" SG_ 897 VC_VehCfg7_Stat "VehCfg7_Pkt";
BA_ "FlexKomSigLaenge" SG_ 897 VC_VehCfg7_Stat 64;
BA_ "FlexKomSID" SG_ 897 VC_VehCfg7_Stat 2026;
BA_ "FlexKomIsMotorola" SG_ 897 VC_VehCfg7_Stat 1;
BA_ "FlexKomComment" SG_ 897 VC_VehCfg7_Stat "Vehicle Configuration 7 Packet";
BA_ "GenSigTimeout_ORC" SG_ 897 VC_LDW 7000;
BA_ "GenSigSNA" SG_ 897 VC_LDW "0h";
BA_ "GenSigSendType" SG_ 897 VC_LDW 5;
BA_ "GenSigCycleTime" SG_ 897 VC_LDW 2000;
BA_ "FlexKomSigStartValue" SG_ 897 VC_LDW "033F000000000000h";
BA_ "FlexKomSigStartPos" SG_ 897 VC_LDW 7;
BA_ "FlexKomSigName" SG_ 897 VC_LDW "VehCfg7_Pkt";
BA_ "FlexKomSigLaenge" SG_ 897 VC_LDW 64;
BA_ "FlexKomSID" SG_ 897 VC_LDW 2026;
BA_ "FlexKomIsMotorola" SG_ 897 VC_LDW 1;
BA_ "FlexKomComment" SG_ 897 VC_LDW "Vehicle Configuration 7 Packet";
BA_ "GenSigTimeout_IC" SG_ 897 VC_TrnsDrvMdPrsnt 21000;
BA_ "GenSigSNA" SG_ 897 VC_TrnsDrvMdPrsnt "0h";
BA_ "GenSigSendType" SG_ 897 VC_TrnsDrvMdPrsnt 5;
BA_ "GenSigCycleTime" SG_ 897 VC_TrnsDrvMdPrsnt 2000;
BA_ "FlexKomSigStartValue" SG_ 897 VC_TrnsDrvMdPrsnt "033F000000000000h";
BA_ "FlexKomSigStartPos" SG_ 897 VC_TrnsDrvMdPrsnt 7;
BA_ "FlexKomSigName" SG_ 897 VC_TrnsDrvMdPrsnt "VehCfg7_Pkt";
BA_ "FlexKomSigLaenge" SG_ 897 VC_TrnsDrvMdPrsnt 64;
BA_ "FlexKomSID" SG_ 897 VC_TrnsDrvMdPrsnt 2026;
BA_ "FlexKomIsMotorola" SG_ 897 VC_TrnsDrvMdPrsnt 1;
BA_ "FlexKomComment" SG_ 897 VC_TrnsDrvMdPrsnt "Vehicle Configuration 7 Packet";
BA_ "GenSigTimeout_IC" SG_ 897 VC_PdlsMdPrsnt 21000;
BA_ "GenSigSNA" SG_ 897 VC_PdlsMdPrsnt "0h";
BA_ "GenSigSendType" SG_ 897 VC_PdlsMdPrsnt 5;
BA_ "GenSigCycleTime" SG_ 897 VC_PdlsMdPrsnt 2000;
BA_ "FlexKomSigStartValue" SG_ 897 VC_PdlsMdPrsnt "033F000000000000h";
BA_ "FlexKomSigStartPos" SG_ 897 VC_PdlsMdPrsnt 7;
BA_ "FlexKomSigName" SG_ 897 VC_PdlsMdPrsnt "VehCfg7_Pkt";
BA_ "FlexKomSigLaenge" SG_ 897 VC_PdlsMdPrsnt 64;
BA_ "FlexKomSID" SG_ 897 VC_PdlsMdPrsnt 2026;
BA_ "FlexKomIsMotorola" SG_ 897 VC_PdlsMdPrsnt 1;
BA_ "FlexKomComment" SG_ 897 VC_PdlsMdPrsnt "Vehicle Configuration 7 Packet";
BA_ "GenSigTimeout_ORC" SG_ 897 VC_DST_Present 7000;
BA_ "GenSigSNA" SG_ 897 VC_DST_Present "0h";
BA_ "GenSigSendType" SG_ 897 VC_DST_Present 5;
BA_ "GenSigCycleTime" SG_ 897 VC_DST_Present 2000;
BA_ "FlexKomSigStartValue" SG_ 897 VC_DST_Present "033F000000000000h";
BA_ "FlexKomSigStartPos" SG_ 897 VC_DST_Present 7;
BA_ "FlexKomSigName" SG_ 897 VC_DST_Present "VehCfg7_Pkt";
BA_ "FlexKomSigLaenge" SG_ 897 VC_DST_Present 64;
BA_ "FlexKomSID" SG_ 897 VC_DST_Present 2026;
BA_ "FlexKomIsMotorola" SG_ 897 VC_DST_Present 1;
BA_ "FlexKomComment" SG_ 897 VC_DST_Present "Vehicle Configuration 7 Packet";
BA_ "GenSigTimeout_IC" SG_ 897 VC_STP_PRSNT 21000;
BA_ "GenSigSNA" SG_ 897 VC_STP_PRSNT "0h";
BA_ "GenSigSendType" SG_ 897 VC_STP_PRSNT 5;
BA_ "GenSigCycleTime" SG_ 897 VC_STP_PRSNT 2000;
BA_ "FlexKomSigStartValue" SG_ 897 VC_STP_PRSNT "033F000000000000h";
BA_ "FlexKomSigStartPos" SG_ 897 VC_STP_PRSNT 7;
BA_ "FlexKomSigName" SG_ 897 VC_STP_PRSNT "VehCfg7_Pkt";
BA_ "FlexKomSigLaenge" SG_ 897 VC_STP_PRSNT 64;
BA_ "FlexKomSID" SG_ 897 VC_STP_PRSNT 2026;
BA_ "FlexKomIsMotorola" SG_ 897 VC_STP_PRSNT 1;
BA_ "FlexKomComment" SG_ 897 VC_STP_PRSNT "Vehicle Configuration 7 Packet";
BA_ "GenSigTimeout_RF_HUB" SG_ 897 VC_eShifter_Prsnt 21000;
BA_ "GenSigSNA" SG_ 897 VC_eShifter_Prsnt "0h";
BA_ "GenSigSendType" SG_ 897 VC_eShifter_Prsnt 5;
BA_ "GenSigCycleTime" SG_ 897 VC_eShifter_Prsnt 2000;
BA_ "FlexKomSigStartValue" SG_ 897 VC_eShifter_Prsnt "033F000000000000h";
BA_ "FlexKomSigStartPos" SG_ 897 VC_eShifter_Prsnt 7;
BA_ "FlexKomSigName" SG_ 897 VC_eShifter_Prsnt "VehCfg7_Pkt";
BA_ "FlexKomSigLaenge" SG_ 897 VC_eShifter_Prsnt 64;
BA_ "FlexKomSID" SG_ 897 VC_eShifter_Prsnt 2026;
BA_ "FlexKomIsMotorola" SG_ 897 VC_eShifter_Prsnt 1;
BA_ "FlexKomComment" SG_ 897 VC_eShifter_Prsnt "Vehicle Configuration 7 Packet";
BA_ "GenSigTimeout_IC" SG_ 897 VC_TransType 21000;
BA_ "GenSigStartValue" SG_ 897 VC_TransType 63;
BA_ "GenSigSNA" SG_ 897 VC_TransType "3Fh";
BA_ "GenSigSendType" SG_ 897 VC_TransType 5;
BA_ "GenSigCycleTime" SG_ 897 VC_TransType 2000;
BA_ "FlexKomSigStartValue" SG_ 897 VC_TransType "033F000000000000h";
BA_ "FlexKomSigStartPos" SG_ 897 VC_TransType 7;
BA_ "FlexKomSigName" SG_ 897 VC_TransType "VehCfg7_Pkt";
BA_ "FlexKomSigLaenge" SG_ 897 VC_TransType 64;
BA_ "FlexKomSID" SG_ 897 VC_TransType 2026;
BA_ "FlexKomIsMotorola" SG_ 897 VC_TransType 1;
BA_ "FlexKomComment" SG_ 897 VC_TransType "Vehicle Configuration 7 Packet";
BA_ "GenSigTimeout_IC" SG_ 897 VC_AS_ERS 21000;
BA_ "GenSigSNA" SG_ 897 VC_AS_ERS "3h";
BA_ "GenSigSendType" SG_ 897 VC_AS_ERS 5;
BA_ "GenSigCycleTime" SG_ 897 VC_AS_ERS 2000;
BA_ "FlexKomSigStartValue" SG_ 897 VC_AS_ERS "033F000000000000h";
BA_ "FlexKomSigStartPos" SG_ 897 VC_AS_ERS 7;
BA_ "FlexKomSigName" SG_ 897 VC_AS_ERS "VehCfg7_Pkt";
BA_ "FlexKomSigLaenge" SG_ 897 VC_AS_ERS 64;
BA_ "FlexKomSID" SG_ 897 VC_AS_ERS 2026;
BA_ "FlexKomIsMotorola" SG_ 897 VC_AS_ERS 1;
BA_ "FlexKomComment" SG_ 897 VC_AS_ERS "Vehicle Configuration 7 Packet";
BA_ "GenSigTimeout_RF_HUB" SG_ 897 VC_TeenKey 21000;
BA_ "GenSigSNA" SG_ 897 VC_TeenKey "0h";
BA_ "GenSigSendType" SG_ 897 VC_TeenKey 5;
BA_ "GenSigCycleTime" SG_ 897 VC_TeenKey 2000;
BA_ "FlexKomSigStartValue" SG_ 897 VC_TeenKey "033F000000000000h";
BA_ "FlexKomSigStartPos" SG_ 897 VC_TeenKey 7;
BA_ "FlexKomSigName" SG_ 897 VC_TeenKey "VehCfg7_Pkt";
BA_ "FlexKomSigLaenge" SG_ 897 VC_TeenKey 64;
BA_ "FlexKomSID" SG_ 897 VC_TeenKey 2026;
BA_ "FlexKomIsMotorola" SG_ 897 VC_TeenKey 1;
BA_ "FlexKomComment" SG_ 897 VC_TeenKey "Vehicle Configuration 7 Packet";
BA_ "GenSigSNA" SG_ 897 VC_SVC_Prsnt "0h";
BA_ "GenSigSendType" SG_ 897 VC_SVC_Prsnt 5;
BA_ "GenSigCycleTime" SG_ 897 VC_SVC_Prsnt 2000;
BA_ "FlexKomSigStartValue" SG_ 897 VC_SVC_Prsnt "033F000000000000h";
BA_ "FlexKomSigStartPos" SG_ 897 VC_SVC_Prsnt 7;
BA_ "FlexKomSigName" SG_ 897 VC_SVC_Prsnt "VehCfg7_Pkt";
BA_ "FlexKomSigLaenge" SG_ 897 VC_SVC_Prsnt 64;
BA_ "FlexKomSID" SG_ 897 VC_SVC_Prsnt 2026;
BA_ "FlexKomIsMotorola" SG_ 897 VC_SVC_Prsnt 1;
BA_ "FlexKomComment" SG_ 897 VC_SVC_Prsnt "Vehicle Configuration 7 Packet";
BA_ "GenSigTimeout_ORC" SG_ 897 VC_FullSpeedRange_FCW 7000;
BA_ "GenSigSNA" SG_ 897 VC_FullSpeedRange_FCW "0h";
BA_ "GenSigSendType" SG_ 897 VC_FullSpeedRange_FCW 5;
BA_ "GenSigCycleTime" SG_ 897 VC_FullSpeedRange_FCW 2000;
BA_ "FlexKomSigStartValue" SG_ 897 VC_FullSpeedRange_FCW "033F000000000000h";
BA_ "FlexKomSigStartPos" SG_ 897 VC_FullSpeedRange_FCW 7;
BA_ "FlexKomSigName" SG_ 897 VC_FullSpeedRange_FCW "VehCfg7_Pkt";
BA_ "FlexKomSigLaenge" SG_ 897 VC_FullSpeedRange_FCW 64;
BA_ "FlexKomSID" SG_ 897 VC_FullSpeedRange_FCW 2026;
BA_ "FlexKomIsMotorola" SG_ 897 VC_FullSpeedRange_FCW 1;
BA_ "FlexKomComment" SG_ 897 VC_FullSpeedRange_FCW "Vehicle Configuration 7 Packet";
BA_ "GenSigTimeout_ORC" SG_ 897 VC_ACC_Type 7000;
BA_ "GenSigSNA" SG_ 897 VC_ACC_Type "0h";
BA_ "GenSigSendType" SG_ 897 VC_ACC_Type 5;
BA_ "GenSigCycleTime" SG_ 897 VC_ACC_Type 2000;
BA_ "FlexKomSigStartValue" SG_ 897 VC_ACC_Type "033F000000000000h";
BA_ "FlexKomSigStartPos" SG_ 897 VC_ACC_Type 7;
BA_ "FlexKomSigName" SG_ 897 VC_ACC_Type "VehCfg7_Pkt";
BA_ "FlexKomSigLaenge" SG_ 897 VC_ACC_Type 64;
BA_ "FlexKomSID" SG_ 897 VC_ACC_Type 2026;
BA_ "FlexKomIsMotorola" SG_ 897 VC_ACC_Type 1;
BA_ "FlexKomComment" SG_ 897 VC_ACC_Type "Vehicle Configuration 7 Packet";
BA_ "GenSigTimeout_IC" SG_ 897 VC_SuspPrsnt 21000;
BA_ "GenSigSNA" SG_ 897 VC_SuspPrsnt "0h";
BA_ "GenSigSendType" SG_ 897 VC_SuspPrsnt 5;
BA_ "GenSigCycleTime" SG_ 897 VC_SuspPrsnt 2000;
BA_ "FlexKomSigStartValue" SG_ 897 VC_SuspPrsnt "033F000000000000h";
BA_ "FlexKomSigStartPos" SG_ 897 VC_SuspPrsnt 7;
BA_ "FlexKomSigName" SG_ 897 VC_SuspPrsnt "VehCfg7_Pkt";
BA_ "FlexKomSigLaenge" SG_ 897 VC_SuspPrsnt 64;
BA_ "FlexKomSID" SG_ 897 VC_SuspPrsnt 2026;
BA_ "FlexKomIsMotorola" SG_ 897 VC_SuspPrsnt 1;
BA_ "FlexKomComment" SG_ 897 VC_SuspPrsnt "Vehicle Configuration 7 Packet";
BA_ "GenSigTimeout_IC" SG_ 897 VC_DampingPrsnt 21000;
BA_ "GenSigSNA" SG_ 897 VC_DampingPrsnt "0h";
BA_ "GenSigSendType" SG_ 897 VC_DampingPrsnt 5;
BA_ "GenSigCycleTime" SG_ 897 VC_DampingPrsnt 2000;
BA_ "FlexKomSigStartValue" SG_ 897 VC_DampingPrsnt "033F000000000000h";
BA_ "FlexKomSigStartPos" SG_ 897 VC_DampingPrsnt 7;
BA_ "FlexKomSigName" SG_ 897 VC_DampingPrsnt "VehCfg7_Pkt";
BA_ "FlexKomSigLaenge" SG_ 897 VC_DampingPrsnt 64;
BA_ "FlexKomSID" SG_ 897 VC_DampingPrsnt 2026;
BA_ "FlexKomIsMotorola" SG_ 897 VC_DampingPrsnt 1;
BA_ "FlexKomComment" SG_ 897 VC_DampingPrsnt "Vehicle Configuration 7 Packet";
BA_ "GenSigSNA" SG_ 897 VC_Trans_N_Hold_Prsnt "0h";
BA_ "GenSigSendType" SG_ 897 VC_Trans_N_Hold_Prsnt 5;
BA_ "GenSigCycleTime" SG_ 897 VC_Trans_N_Hold_Prsnt 2000;
BA_ "FlexKomSigStartValue" SG_ 897 VC_Trans_N_Hold_Prsnt "033F000000000000h";
BA_ "FlexKomSigStartPos" SG_ 897 VC_Trans_N_Hold_Prsnt 7;
BA_ "FlexKomSigName" SG_ 897 VC_Trans_N_Hold_Prsnt "VehCfg7_Pkt";
BA_ "FlexKomSigLaenge" SG_ 897 VC_Trans_N_Hold_Prsnt 64;
BA_ "FlexKomSID" SG_ 897 VC_Trans_N_Hold_Prsnt 2026;
BA_ "FlexKomIsMotorola" SG_ 897 VC_Trans_N_Hold_Prsnt 1;
BA_ "FlexKomComment" SG_ 897 VC_Trans_N_Hold_Prsnt "Vehicle Configuration 7 Packet";
BA_ "GenSigTimeout_RF_HUB" SG_ 897 VC_RedKey 21000;
BA_ "GenSigSNA" SG_ 897 VC_RedKey "0h";
BA_ "GenSigSendType" SG_ 897 VC_RedKey 5;
BA_ "GenSigCycleTime" SG_ 897 VC_RedKey 2000;
BA_ "FlexKomSigStartValue" SG_ 897 VC_RedKey "033F000000000000h";
BA_ "FlexKomSigStartPos" SG_ 897 VC_RedKey 7;
BA_ "FlexKomSigName" SG_ 897 VC_RedKey "VehCfg7_Pkt";
BA_ "FlexKomSigLaenge" SG_ 897 VC_RedKey 64;
BA_ "FlexKomSID" SG_ 897 VC_RedKey 2026;
BA_ "FlexKomIsMotorola" SG_ 897 VC_RedKey 1;
BA_ "FlexKomComment" SG_ 897 VC_RedKey "Vehicle Configuration 7 Packet";
BA_ "GenSigTimeout_IC" SG_ 897 VC_ABSM 21000;
BA_ "GenSigSNA" SG_ 897 VC_ABSM "0h";
BA_ "GenSigSendType" SG_ 897 VC_ABSM 5;
BA_ "GenSigCycleTime" SG_ 897 VC_ABSM 2000;
BA_ "FlexKomSigStartValue" SG_ 897 VC_ABSM "033F000000000000h";
BA_ "FlexKomSigStartPos" SG_ 897 VC_ABSM 7;
BA_ "FlexKomSigName" SG_ 897 VC_ABSM "VehCfg7_Pkt";
BA_ "FlexKomSigLaenge" SG_ 897 VC_ABSM 64;
BA_ "FlexKomSID" SG_ 897 VC_ABSM 2026;
BA_ "FlexKomIsMotorola" SG_ 897 VC_ABSM 1;
BA_ "FlexKomComment" SG_ 897 VC_ABSM "Vehicle Configuration 7 Packet";
BA_ "GenSigSNA" SG_ 897 VC_AxleLockerPrsnt "0h";
BA_ "GenSigSendType" SG_ 897 VC_AxleLockerPrsnt 5;
BA_ "GenSigCycleTime" SG_ 897 VC_AxleLockerPrsnt 2000;
BA_ "FlexKomSigStartValue" SG_ 897 VC_AxleLockerPrsnt "033F000000000000h";
BA_ "FlexKomSigStartPos" SG_ 897 VC_AxleLockerPrsnt 7;
BA_ "FlexKomSigName" SG_ 897 VC_AxleLockerPrsnt "VehCfg7_Pkt";
BA_ "FlexKomSigLaenge" SG_ 897 VC_AxleLockerPrsnt 64;
BA_ "FlexKomSID" SG_ 897 VC_AxleLockerPrsnt 2026;
BA_ "FlexKomIsMotorola" SG_ 897 VC_AxleLockerPrsnt 1;
BA_ "FlexKomComment" SG_ 897 VC_AxleLockerPrsnt "Vehicle Configuration 7 Packet";
BA_ "GenSigTimeout_ORC" SG_ 897 VC_Trans_Equipped 7000;
BA_ "GenSigSNA" SG_ 897 VC_Trans_Equipped "0h";
BA_ "GenSigSendType" SG_ 897 VC_Trans_Equipped 5;
BA_ "GenSigCycleTime" SG_ 897 VC_Trans_Equipped 2000;
BA_ "FlexKomSigStartValue" SG_ 897 VC_Trans_Equipped "033F000000000000h";
BA_ "FlexKomSigStartPos" SG_ 897 VC_Trans_Equipped 7;
BA_ "FlexKomSigName" SG_ 897 VC_Trans_Equipped "VehCfg7_Pkt";
BA_ "FlexKomSigLaenge" SG_ 897 VC_Trans_Equipped 64;
BA_ "FlexKomSID" SG_ 897 VC_Trans_Equipped 2026;
BA_ "FlexKomIsMotorola" SG_ 897 VC_Trans_Equipped 1;
BA_ "FlexKomComment" SG_ 897 VC_Trans_Equipped "Vehicle Configuration 7 Packet";
BA_ "GenSigStartValue" SG_ 898 VC_BU_VehCfg7_Stat 3;
BA_ "GenSigSNA" SG_ 898 VC_BU_VehCfg7_Stat "3h";
BA_ "GenSigSendType" SG_ 898 VC_BU_VehCfg7_Stat 1;
BA_ "FlexKomSigStartValue" SG_ 898 VC_BU_VehCfg7_Stat "033F000000000000h";
BA_ "FlexKomSigStartPos" SG_ 898 VC_BU_VehCfg7_Stat 7;
BA_ "FlexKomSigName" SG_ 898 VC_BU_VehCfg7_Stat "VehCfgBU7_Pkt";
BA_ "FlexKomSigLaenge" SG_ 898 VC_BU_VehCfg7_Stat 64;
BA_ "FlexKomSID" SG_ 898 VC_BU_VehCfg7_Stat 2027;
BA_ "FlexKomIsMotorola" SG_ 898 VC_BU_VehCfg7_Stat 1;
BA_ "FlexKomComment" SG_ 898 VC_BU_VehCfg7_Stat "Backup for vehicle configuration 7 packet";
BA_ "GenSigSNA" SG_ 898 VC_BU_LDW "0h";
BA_ "GenSigSendType" SG_ 898 VC_BU_LDW 1;
BA_ "FlexKomSigStartValue" SG_ 898 VC_BU_LDW "033F000000000000h";
BA_ "FlexKomSigStartPos" SG_ 898 VC_BU_LDW 7;
BA_ "FlexKomSigName" SG_ 898 VC_BU_LDW "VehCfgBU7_Pkt";
BA_ "FlexKomSigLaenge" SG_ 898 VC_BU_LDW 64;
BA_ "FlexKomSID" SG_ 898 VC_BU_LDW 2027;
BA_ "FlexKomIsMotorola" SG_ 898 VC_BU_LDW 1;
BA_ "FlexKomComment" SG_ 898 VC_BU_LDW "Backup for vehicle configuration 7 packet";
BA_ "GenSigSNA" SG_ 898 VC_BU_TrnsDrvMdPrsnt "0h";
BA_ "GenSigSendType" SG_ 898 VC_BU_TrnsDrvMdPrsnt 1;
BA_ "FlexKomSigStartValue" SG_ 898 VC_BU_TrnsDrvMdPrsnt "033F000000000000h";
BA_ "FlexKomSigStartPos" SG_ 898 VC_BU_TrnsDrvMdPrsnt 7;
BA_ "FlexKomSigName" SG_ 898 VC_BU_TrnsDrvMdPrsnt "VehCfgBU7_Pkt";
BA_ "FlexKomSigLaenge" SG_ 898 VC_BU_TrnsDrvMdPrsnt 64;
BA_ "FlexKomSID" SG_ 898 VC_BU_TrnsDrvMdPrsnt 2027;
BA_ "FlexKomIsMotorola" SG_ 898 VC_BU_TrnsDrvMdPrsnt 1;
BA_ "FlexKomComment" SG_ 898 VC_BU_TrnsDrvMdPrsnt "Backup for vehicle configuration 7 packet";
BA_ "GenSigSNA" SG_ 898 VC_BU_PdlsMdPrsnt "0h";
BA_ "GenSigSendType" SG_ 898 VC_BU_PdlsMdPrsnt 1;
BA_ "FlexKomSigStartValue" SG_ 898 VC_BU_PdlsMdPrsnt "033F000000000000h";
BA_ "FlexKomSigStartPos" SG_ 898 VC_BU_PdlsMdPrsnt 7;
BA_ "FlexKomSigName" SG_ 898 VC_BU_PdlsMdPrsnt "VehCfgBU7_Pkt";
BA_ "FlexKomSigLaenge" SG_ 898 VC_BU_PdlsMdPrsnt 64;
BA_ "FlexKomSID" SG_ 898 VC_BU_PdlsMdPrsnt 2027;
BA_ "FlexKomIsMotorola" SG_ 898 VC_BU_PdlsMdPrsnt 1;
BA_ "FlexKomComment" SG_ 898 VC_BU_PdlsMdPrsnt "Backup for vehicle configuration 7 packet";
BA_ "GenSigSNA" SG_ 898 VC_BU_DST_Present "0h";
BA_ "GenSigSendType" SG_ 898 VC_BU_DST_Present 1;
BA_ "FlexKomSigStartValue" SG_ 898 VC_BU_DST_Present "033F000000000000h";
BA_ "FlexKomSigStartPos" SG_ 898 VC_BU_DST_Present 7;
BA_ "FlexKomSigName" SG_ 898 VC_BU_DST_Present "VehCfgBU7_Pkt";
BA_ "FlexKomSigLaenge" SG_ 898 VC_BU_DST_Present 64;
BA_ "FlexKomSID" SG_ 898 VC_BU_DST_Present 2027;
BA_ "FlexKomIsMotorola" SG_ 898 VC_BU_DST_Present 1;
BA_ "FlexKomComment" SG_ 898 VC_BU_DST_Present "Backup for vehicle configuration 7 packet";
BA_ "GenSigSNA" SG_ 898 VC_BU_STP_PRSNT "0h";
BA_ "GenSigSendType" SG_ 898 VC_BU_STP_PRSNT 1;
BA_ "FlexKomSigStartValue" SG_ 898 VC_BU_STP_PRSNT "033F000000000000h";
BA_ "FlexKomSigStartPos" SG_ 898 VC_BU_STP_PRSNT 7;
BA_ "FlexKomSigName" SG_ 898 VC_BU_STP_PRSNT "VehCfgBU7_Pkt";
BA_ "FlexKomSigLaenge" SG_ 898 VC_BU_STP_PRSNT 64;
BA_ "FlexKomSID" SG_ 898 VC_BU_STP_PRSNT 2027;
BA_ "FlexKomIsMotorola" SG_ 898 VC_BU_STP_PRSNT 1;
BA_ "FlexKomComment" SG_ 898 VC_BU_STP_PRSNT "Backup for vehicle configuration 7 packet";
BA_ "GenSigSNA" SG_ 898 VC_BU_eShifter_Prsnt "0h";
BA_ "GenSigSendType" SG_ 898 VC_BU_eShifter_Prsnt 1;
BA_ "FlexKomSigStartValue" SG_ 898 VC_BU_eShifter_Prsnt "033F000000000000h";
BA_ "FlexKomSigStartPos" SG_ 898 VC_BU_eShifter_Prsnt 7;
BA_ "FlexKomSigName" SG_ 898 VC_BU_eShifter_Prsnt "VehCfgBU7_Pkt";
BA_ "FlexKomSigLaenge" SG_ 898 VC_BU_eShifter_Prsnt 64;
BA_ "FlexKomSID" SG_ 898 VC_BU_eShifter_Prsnt 2027;
BA_ "FlexKomIsMotorola" SG_ 898 VC_BU_eShifter_Prsnt 1;
BA_ "FlexKomComment" SG_ 898 VC_BU_eShifter_Prsnt "Backup for vehicle configuration 7 packet";
BA_ "GenSigStartValue" SG_ 898 VC_BU_TransType 63;
BA_ "GenSigSNA" SG_ 898 VC_BU_TransType "3Fh";
BA_ "GenSigSendType" SG_ 898 VC_BU_TransType 1;
BA_ "FlexKomSigStartValue" SG_ 898 VC_BU_TransType "033F000000000000h";
BA_ "FlexKomSigStartPos" SG_ 898 VC_BU_TransType 7;
BA_ "FlexKomSigName" SG_ 898 VC_BU_TransType "VehCfgBU7_Pkt";
BA_ "FlexKomSigLaenge" SG_ 898 VC_BU_TransType 64;
BA_ "FlexKomSID" SG_ 898 VC_BU_TransType 2027;
BA_ "FlexKomIsMotorola" SG_ 898 VC_BU_TransType 1;
BA_ "FlexKomComment" SG_ 898 VC_BU_TransType "Backup for vehicle configuration 7 packet";
BA_ "GenSigSNA" SG_ 898 VC_BU_AS_ERS "3h";
BA_ "GenSigSendType" SG_ 898 VC_BU_AS_ERS 1;
BA_ "FlexKomSigStartValue" SG_ 898 VC_BU_AS_ERS "033F000000000000h";
BA_ "FlexKomSigStartPos" SG_ 898 VC_BU_AS_ERS 7;
BA_ "FlexKomSigName" SG_ 898 VC_BU_AS_ERS "VehCfgBU7_Pkt";
BA_ "FlexKomSigLaenge" SG_ 898 VC_BU_AS_ERS 64;
BA_ "FlexKomSID" SG_ 898 VC_BU_AS_ERS 2027;
BA_ "FlexKomIsMotorola" SG_ 898 VC_BU_AS_ERS 1;
BA_ "FlexKomComment" SG_ 898 VC_BU_AS_ERS "Backup for vehicle configuration 7 packet";
BA_ "GenSigSNA" SG_ 898 VC_BU_TeenKey "0h";
BA_ "GenSigSendType" SG_ 898 VC_BU_TeenKey 1;
BA_ "FlexKomSigStartValue" SG_ 898 VC_BU_TeenKey "033F000000000000h";
BA_ "FlexKomSigStartPos" SG_ 898 VC_BU_TeenKey 7;
BA_ "FlexKomSigName" SG_ 898 VC_BU_TeenKey "VehCfgBU7_Pkt";
BA_ "FlexKomSigLaenge" SG_ 898 VC_BU_TeenKey 64;
BA_ "FlexKomSID" SG_ 898 VC_BU_TeenKey 2027;
BA_ "FlexKomIsMotorola" SG_ 898 VC_BU_TeenKey 1;
BA_ "FlexKomComment" SG_ 898 VC_BU_TeenKey "Backup for vehicle configuration 7 packet";
BA_ "GenSigSNA" SG_ 898 VC_BU_SVC_Prsnt "0h";
BA_ "GenSigSendType" SG_ 898 VC_BU_SVC_Prsnt 1;
BA_ "FlexKomSigStartValue" SG_ 898 VC_BU_SVC_Prsnt "033F000000000000h";
BA_ "FlexKomSigStartPos" SG_ 898 VC_BU_SVC_Prsnt 7;
BA_ "FlexKomSigName" SG_ 898 VC_BU_SVC_Prsnt "VehCfgBU7_Pkt";
BA_ "FlexKomSigLaenge" SG_ 898 VC_BU_SVC_Prsnt 64;
BA_ "FlexKomSID" SG_ 898 VC_BU_SVC_Prsnt 2027;
BA_ "FlexKomIsMotorola" SG_ 898 VC_BU_SVC_Prsnt 1;
BA_ "FlexKomComment" SG_ 898 VC_BU_SVC_Prsnt "Backup for vehicle configuration 7 packet";
BA_ "GenSigSNA" SG_ 898 VC_BU_FullSpeedRange_FCW "0h";
BA_ "GenSigSendType" SG_ 898 VC_BU_FullSpeedRange_FCW 1;
BA_ "FlexKomSigStartValue" SG_ 898 VC_BU_FullSpeedRange_FCW "033F000000000000h";
BA_ "FlexKomSigStartPos" SG_ 898 VC_BU_FullSpeedRange_FCW 7;
BA_ "FlexKomSigName" SG_ 898 VC_BU_FullSpeedRange_FCW "VehCfgBU7_Pkt";
BA_ "FlexKomSigLaenge" SG_ 898 VC_BU_FullSpeedRange_FCW 64;
BA_ "FlexKomSID" SG_ 898 VC_BU_FullSpeedRange_FCW 2027;
BA_ "FlexKomIsMotorola" SG_ 898 VC_BU_FullSpeedRange_FCW 1;
BA_ "FlexKomComment" SG_ 898 VC_BU_FullSpeedRange_FCW "Backup for vehicle configuration 7 packet";
BA_ "GenSigSNA" SG_ 898 VC_BU_ACC_Type "0h";
BA_ "GenSigSendType" SG_ 898 VC_BU_ACC_Type 1;
BA_ "FlexKomSigStartValue" SG_ 898 VC_BU_ACC_Type "033F000000000000h";
BA_ "FlexKomSigStartPos" SG_ 898 VC_BU_ACC_Type 7;
BA_ "FlexKomSigName" SG_ 898 VC_BU_ACC_Type "VehCfgBU7_Pkt";
BA_ "FlexKomSigLaenge" SG_ 898 VC_BU_ACC_Type 64;
BA_ "FlexKomSID" SG_ 898 VC_BU_ACC_Type 2027;
BA_ "FlexKomIsMotorola" SG_ 898 VC_BU_ACC_Type 1;
BA_ "FlexKomComment" SG_ 898 VC_BU_ACC_Type "Backup for vehicle configuration 7 packet";
BA_ "GenSigSNA" SG_ 898 VC_BU_SuspPrsnt "0h";
BA_ "GenSigSendType" SG_ 898 VC_BU_SuspPrsnt 1;
BA_ "FlexKomSigStartValue" SG_ 898 VC_BU_SuspPrsnt "033F000000000000h";
BA_ "FlexKomSigStartPos" SG_ 898 VC_BU_SuspPrsnt 7;
BA_ "FlexKomSigName" SG_ 898 VC_BU_SuspPrsnt "VehCfgBU7_Pkt";
BA_ "FlexKomSigLaenge" SG_ 898 VC_BU_SuspPrsnt 64;
BA_ "FlexKomSID" SG_ 898 VC_BU_SuspPrsnt 2027;
BA_ "FlexKomIsMotorola" SG_ 898 VC_BU_SuspPrsnt 1;
BA_ "FlexKomComment" SG_ 898 VC_BU_SuspPrsnt "Backup for vehicle configuration 7 packet";
BA_ "GenSigSNA" SG_ 898 VC_BU_DampingPrsnt "0h";
BA_ "GenSigSendType" SG_ 898 VC_BU_DampingPrsnt 1;
BA_ "FlexKomSigStartValue" SG_ 898 VC_BU_DampingPrsnt "033F000000000000h";
BA_ "FlexKomSigStartPos" SG_ 898 VC_BU_DampingPrsnt 7;
BA_ "FlexKomSigName" SG_ 898 VC_BU_DampingPrsnt "VehCfgBU7_Pkt";
BA_ "FlexKomSigLaenge" SG_ 898 VC_BU_DampingPrsnt 64;
BA_ "FlexKomSID" SG_ 898 VC_BU_DampingPrsnt 2027;
BA_ "FlexKomIsMotorola" SG_ 898 VC_BU_DampingPrsnt 1;
BA_ "FlexKomComment" SG_ 898 VC_BU_DampingPrsnt "Backup for vehicle configuration 7 packet";
BA_ "GenSigSNA" SG_ 898 VC_BU_Trans_N_Hold_Prsnt "0h";
BA_ "GenSigSendType" SG_ 898 VC_BU_Trans_N_Hold_Prsnt 1;
BA_ "FlexKomSigStartValue" SG_ 898 VC_BU_Trans_N_Hold_Prsnt "033F000000000000h";
BA_ "FlexKomSigStartPos" SG_ 898 VC_BU_Trans_N_Hold_Prsnt 7;
BA_ "FlexKomSigName" SG_ 898 VC_BU_Trans_N_Hold_Prsnt "VehCfgBU7_Pkt";
BA_ "FlexKomSigLaenge" SG_ 898 VC_BU_Trans_N_Hold_Prsnt 64;
BA_ "FlexKomSID" SG_ 898 VC_BU_Trans_N_Hold_Prsnt 2027;
BA_ "FlexKomIsMotorola" SG_ 898 VC_BU_Trans_N_Hold_Prsnt 1;
BA_ "FlexKomComment" SG_ 898 VC_BU_Trans_N_Hold_Prsnt "Backup for vehicle configuration 7 packet";
BA_ "GenSigSNA" SG_ 898 VC_BU_RedKey "0h";
BA_ "GenSigSendType" SG_ 898 VC_BU_RedKey 1;
BA_ "FlexKomSigStartValue" SG_ 898 VC_BU_RedKey "033F000000000000h";
BA_ "FlexKomSigStartPos" SG_ 898 VC_BU_RedKey 7;
BA_ "FlexKomSigName" SG_ 898 VC_BU_RedKey "VehCfgBU7_Pkt";
BA_ "FlexKomSigLaenge" SG_ 898 VC_BU_RedKey 64;
BA_ "FlexKomSID" SG_ 898 VC_BU_RedKey 2027;
BA_ "FlexKomIsMotorola" SG_ 898 VC_BU_RedKey 1;
BA_ "FlexKomComment" SG_ 898 VC_BU_RedKey "Backup for vehicle configuration 7 packet";
BA_ "GenSigSNA" SG_ 898 VC_BU_ABSM "0h";
BA_ "GenSigSendType" SG_ 898 VC_BU_ABSM 1;
BA_ "FlexKomSigStartValue" SG_ 898 VC_BU_ABSM "033F000000000000h";
BA_ "FlexKomSigStartPos" SG_ 898 VC_BU_ABSM 7;
BA_ "FlexKomSigName" SG_ 898 VC_BU_ABSM "VehCfgBU7_Pkt";
BA_ "FlexKomSigLaenge" SG_ 898 VC_BU_ABSM 64;
BA_ "FlexKomSID" SG_ 898 VC_BU_ABSM 2027;
BA_ "FlexKomIsMotorola" SG_ 898 VC_BU_ABSM 1;
BA_ "FlexKomComment" SG_ 898 VC_BU_ABSM "Backup for vehicle configuration 7 packet";
BA_ "GenSigSNA" SG_ 898 VC_BU_AxleLockerPrsnt "0h";
BA_ "GenSigSendType" SG_ 898 VC_BU_AxleLockerPrsnt 1;
BA_ "FlexKomSigStartValue" SG_ 898 VC_BU_AxleLockerPrsnt "033F000000000000h";
BA_ "FlexKomSigStartPos" SG_ 898 VC_BU_AxleLockerPrsnt 7;
BA_ "FlexKomSigName" SG_ 898 VC_BU_AxleLockerPrsnt "VehCfgBU7_Pkt";
BA_ "FlexKomSigLaenge" SG_ 898 VC_BU_AxleLockerPrsnt 64;
BA_ "FlexKomSID" SG_ 898 VC_BU_AxleLockerPrsnt 2027;
BA_ "FlexKomIsMotorola" SG_ 898 VC_BU_AxleLockerPrsnt 1;
BA_ "FlexKomComment" SG_ 898 VC_BU_AxleLockerPrsnt "Backup for vehicle configuration 7 packet";
BA_ "GenSigSNA" SG_ 898 VC_BU_Trans_Equipped "0h";
BA_ "GenSigSendType" SG_ 898 VC_BU_Trans_Equipped 1;
BA_ "FlexKomSigStartValue" SG_ 898 VC_BU_Trans_Equipped "033F000000000000h";
BA_ "FlexKomSigStartPos" SG_ 898 VC_BU_Trans_Equipped 7;
BA_ "FlexKomSigName" SG_ 898 VC_BU_Trans_Equipped "VehCfgBU7_Pkt";
BA_ "FlexKomSigLaenge" SG_ 898 VC_BU_Trans_Equipped 64;
BA_ "FlexKomSID" SG_ 898 VC_BU_Trans_Equipped 2027;
BA_ "FlexKomIsMotorola" SG_ 898 VC_BU_Trans_Equipped 1;
BA_ "FlexKomComment" SG_ 898 VC_BU_Trans_Equipped "Backup for vehicle configuration 7 packet";
BA_ "GenSigSNA" SG_ 898 VC_BU_PBTyp "7h";
BA_ "GenSigSendType" SG_ 898 VC_BU_PBTyp 1;
BA_ "FlexKomSigStartValue" SG_ 898 VC_BU_PBTyp "033F000000000000h";
BA_ "FlexKomSigStartPos" SG_ 898 VC_BU_PBTyp 7;
BA_ "FlexKomSigName" SG_ 898 VC_BU_PBTyp "VehCfgBU7_Pkt";
BA_ "FlexKomSigLaenge" SG_ 898 VC_BU_PBTyp 64;
BA_ "FlexKomSID" SG_ 898 VC_BU_PBTyp 2027;
BA_ "FlexKomIsMotorola" SG_ 898 VC_BU_PBTyp 1;
BA_ "FlexKomComment" SG_ 898 VC_BU_PBTyp "Backup for vehicle configuration 7 packet";
BA_ "GenSigSNA" SG_ 898 VC_BU_TPMS_Configuration "7h";
BA_ "GenSigSendType" SG_ 898 VC_BU_TPMS_Configuration 1;
BA_ "FlexKomSigStartValue" SG_ 898 VC_BU_TPMS_Configuration "033F000000000000h";
BA_ "FlexKomSigStartPos" SG_ 898 VC_BU_TPMS_Configuration 7;
BA_ "FlexKomSigName" SG_ 898 VC_BU_TPMS_Configuration "VehCfgBU7_Pkt";
BA_ "FlexKomSigLaenge" SG_ 898 VC_BU_TPMS_Configuration 64;
BA_ "FlexKomSID" SG_ 898 VC_BU_TPMS_Configuration 2027;
BA_ "FlexKomIsMotorola" SG_ 898 VC_BU_TPMS_Configuration 1;
BA_ "FlexKomComment" SG_ 898 VC_BU_TPMS_Configuration "Backup for vehicle configuration 7 packet";
BA_ "GenSigSNA" SG_ 898 VC_BU_SmartAlternator "0h";
BA_ "GenSigSendType" SG_ 898 VC_BU_SmartAlternator 1;
BA_ "FlexKomSigStartValue" SG_ 898 VC_BU_SmartAlternator "033F000000000000h";
BA_ "FlexKomSigStartPos" SG_ 898 VC_BU_SmartAlternator 7;
BA_ "FlexKomSigName" SG_ 898 VC_BU_SmartAlternator "VehCfgBU7_Pkt";
BA_ "FlexKomSigLaenge" SG_ 898 VC_BU_SmartAlternator 64;
BA_ "FlexKomSID" SG_ 898 VC_BU_SmartAlternator 2027;
BA_ "FlexKomIsMotorola" SG_ 898 VC_BU_SmartAlternator 1;
BA_ "FlexKomComment" SG_ 898 VC_BU_SmartAlternator "Backup for vehicle configuration 7 packet";
BA_ "GenSigSNA" SG_ 898 VC_BU_HybridType "0h";
BA_ "GenSigSendType" SG_ 898 VC_BU_HybridType 1;
BA_ "FlexKomSigStartValue" SG_ 898 VC_BU_HybridType "033F000000000000h";
BA_ "FlexKomSigStartPos" SG_ 898 VC_BU_HybridType 7;
BA_ "FlexKomSigName" SG_ 898 VC_BU_HybridType "VehCfgBU7_Pkt";
BA_ "FlexKomSigLaenge" SG_ 898 VC_BU_HybridType 64;
BA_ "FlexKomSID" SG_ 898 VC_BU_HybridType 2027;
BA_ "FlexKomIsMotorola" SG_ 898 VC_BU_HybridType 1;
BA_ "FlexKomComment" SG_ 898 VC_BU_HybridType "Backup for vehicle configuration 7 packet";
BA_ "GenSigSNA" SG_ 898 VC_BU_TSBM_Prsnt "0h";
BA_ "GenSigSendType" SG_ 898 VC_BU_TSBM_Prsnt 1;
BA_ "FlexKomSigStartValue" SG_ 898 VC_BU_TSBM_Prsnt "033F000000000000h";
BA_ "FlexKomSigStartPos" SG_ 898 VC_BU_TSBM_Prsnt 7;
BA_ "FlexKomSigName" SG_ 898 VC_BU_TSBM_Prsnt "VehCfgBU7_Pkt";
BA_ "FlexKomSigLaenge" SG_ 898 VC_BU_TSBM_Prsnt 64;
BA_ "FlexKomSID" SG_ 898 VC_BU_TSBM_Prsnt 2027;
BA_ "FlexKomIsMotorola" SG_ 898 VC_BU_TSBM_Prsnt 1;
BA_ "FlexKomComment" SG_ 898 VC_BU_TSBM_Prsnt "Backup for vehicle configuration 7 packet";
BA_ "GenSigSNA" SG_ 898 VC_BU_ADR_PRSNT "0h";
BA_ "GenSigSendType" SG_ 898 VC_BU_ADR_PRSNT 1;
BA_ "FlexKomSigStartValue" SG_ 898 VC_BU_ADR_PRSNT "033F000000000000h";
BA_ "FlexKomSigStartPos" SG_ 898 VC_BU_ADR_PRSNT 7;
BA_ "FlexKomSigName" SG_ 898 VC_BU_ADR_PRSNT "VehCfgBU7_Pkt";
BA_ "FlexKomSigLaenge" SG_ 898 VC_BU_ADR_PRSNT 64;
BA_ "FlexKomSID" SG_ 898 VC_BU_ADR_PRSNT 2027;
BA_ "FlexKomIsMotorola" SG_ 898 VC_BU_ADR_PRSNT 1;
BA_ "FlexKomComment" SG_ 898 VC_BU_ADR_PRSNT "Backup for vehicle configuration 7 packet";
BA_ "GenSigSNA" SG_ 898 VC_BU_Temp_Display_Resolution "0h";
BA_ "GenSigSendType" SG_ 898 VC_BU_Temp_Display_Resolution 1;
BA_ "FlexKomSigStartValue" SG_ 898 VC_BU_Temp_Display_Resolution "033F000000000000h";
BA_ "FlexKomSigStartPos" SG_ 898 VC_BU_Temp_Display_Resolution 7;
BA_ "FlexKomSigName" SG_ 898 VC_BU_Temp_Display_Resolution "VehCfgBU7_Pkt";
BA_ "FlexKomSigLaenge" SG_ 898 VC_BU_Temp_Display_Resolution 64;
BA_ "FlexKomSID" SG_ 898 VC_BU_Temp_Display_Resolution 2027;
BA_ "FlexKomIsMotorola" SG_ 898 VC_BU_Temp_Display_Resolution 1;
BA_ "FlexKomComment" SG_ 898 VC_BU_Temp_Display_Resolution "Backup for vehicle configuration 7 packet";
BA_ "GenSigSNA" SG_ 898 VC_BU_AGSprsnt "0h";
BA_ "GenSigSendType" SG_ 898 VC_BU_AGSprsnt 1;
BA_ "FlexKomSigStartValue" SG_ 898 VC_BU_AGSprsnt "033F000000000000h";
BA_ "FlexKomSigStartPos" SG_ 898 VC_BU_AGSprsnt 7;
BA_ "FlexKomSigName" SG_ 898 VC_BU_AGSprsnt "VehCfgBU7_Pkt";
BA_ "FlexKomSigLaenge" SG_ 898 VC_BU_AGSprsnt 64;
BA_ "FlexKomSID" SG_ 898 VC_BU_AGSprsnt 2027;
BA_ "FlexKomIsMotorola" SG_ 898 VC_BU_AGSprsnt 1;
BA_ "FlexKomComment" SG_ 898 VC_BU_AGSprsnt "Backup for vehicle configuration 7 packet";
BA_ "GenSigSNA" SG_ 898 VC_BU_PTCPrsnt "0h";
BA_ "GenSigSendType" SG_ 898 VC_BU_PTCPrsnt 1;
BA_ "FlexKomSigStartValue" SG_ 898 VC_BU_PTCPrsnt "033F000000000000h";
BA_ "FlexKomSigStartPos" SG_ 898 VC_BU_PTCPrsnt 7;
BA_ "FlexKomSigName" SG_ 898 VC_BU_PTCPrsnt "VehCfgBU7_Pkt";
BA_ "FlexKomSigLaenge" SG_ 898 VC_BU_PTCPrsnt 64;
BA_ "FlexKomSID" SG_ 898 VC_BU_PTCPrsnt 2027;
BA_ "FlexKomIsMotorola" SG_ 898 VC_BU_PTCPrsnt 1;
BA_ "FlexKomComment" SG_ 898 VC_BU_PTCPrsnt "Backup for vehicle configuration 7 packet";
BA_ "GenSigSNA" SG_ 898 VC_BU_Glovebox "0h";
BA_ "GenSigSendType" SG_ 898 VC_BU_Glovebox 1;
BA_ "FlexKomSigStartValue" SG_ 898 VC_BU_Glovebox "033F000000000000h";
BA_ "FlexKomSigStartPos" SG_ 898 VC_BU_Glovebox 7;
BA_ "FlexKomSigName" SG_ 898 VC_BU_Glovebox "VehCfgBU7_Pkt";
BA_ "FlexKomSigLaenge" SG_ 898 VC_BU_Glovebox 64;
BA_ "FlexKomSID" SG_ 898 VC_BU_Glovebox 2027;
BA_ "FlexKomIsMotorola" SG_ 898 VC_BU_Glovebox 1;
BA_ "FlexKomComment" SG_ 898 VC_BU_Glovebox "Backup for vehicle configuration 7 packet";
BA_ "GenSigSNA" SG_ 898 VC_BU_MOC_Type "0h";
BA_ "GenSigSendType" SG_ 898 VC_BU_MOC_Type 1;
BA_ "FlexKomSigStartValue" SG_ 898 VC_BU_MOC_Type "033F000000000000h";
BA_ "FlexKomSigStartPos" SG_ 898 VC_BU_MOC_Type 7;
BA_ "FlexKomSigName" SG_ 898 VC_BU_MOC_Type "VehCfgBU7_Pkt";
BA_ "FlexKomSigLaenge" SG_ 898 VC_BU_MOC_Type 64;
BA_ "FlexKomSID" SG_ 898 VC_BU_MOC_Type 2027;
BA_ "FlexKomIsMotorola" SG_ 898 VC_BU_MOC_Type 1;
BA_ "FlexKomComment" SG_ 898 VC_BU_MOC_Type "Backup for vehicle configuration 7 packet";
BA_ "GenSigSNA" SG_ 898 VC_BU_SUNR_Prsnt "0h";
BA_ "GenSigSendType" SG_ 898 VC_BU_SUNR_Prsnt 1;
BA_ "FlexKomSigStartValue" SG_ 898 VC_BU_SUNR_Prsnt "033F000000000000h";
BA_ "FlexKomSigStartPos" SG_ 898 VC_BU_SUNR_Prsnt 7;
BA_ "FlexKomSigName" SG_ 898 VC_BU_SUNR_Prsnt "VehCfgBU7_Pkt";
BA_ "FlexKomSigLaenge" SG_ 898 VC_BU_SUNR_Prsnt 64;
BA_ "FlexKomSID" SG_ 898 VC_BU_SUNR_Prsnt 2027;
BA_ "FlexKomIsMotorola" SG_ 898 VC_BU_SUNR_Prsnt 1;
BA_ "FlexKomComment" SG_ 898 VC_BU_SUNR_Prsnt "Backup for vehicle configuration 7 packet";
BA_ "GenSigSNA" SG_ 898 VC_BU_Brake_Type "0h";
BA_ "GenSigSendType" SG_ 898 VC_BU_Brake_Type 1;
BA_ "FlexKomSigStartValue" SG_ 898 VC_BU_Brake_Type "033F000000000000h";
BA_ "FlexKomSigStartPos" SG_ 898 VC_BU_Brake_Type 7;
BA_ "FlexKomSigName" SG_ 898 VC_BU_Brake_Type "VehCfgBU7_Pkt";
BA_ "FlexKomSigLaenge" SG_ 898 VC_BU_Brake_Type 64;
BA_ "FlexKomSID" SG_ 898 VC_BU_Brake_Type 2027;
BA_ "FlexKomIsMotorola" SG_ 898 VC_BU_Brake_Type 1;
BA_ "FlexKomComment" SG_ 898 VC_BU_Brake_Type "Backup for vehicle configuration 7 packet";
BA_ "GenSigSNA" SG_ 898 VC_BU_Suspension_Type "0h";
BA_ "GenSigSendType" SG_ 898 VC_BU_Suspension_Type 1;
BA_ "FlexKomSigStartValue" SG_ 898 VC_BU_Suspension_Type "033F000000000000h";
BA_ "FlexKomSigStartPos" SG_ 898 VC_BU_Suspension_Type 7;
BA_ "FlexKomSigName" SG_ 898 VC_BU_Suspension_Type "VehCfgBU7_Pkt";
BA_ "FlexKomSigLaenge" SG_ 898 VC_BU_Suspension_Type 64;
BA_ "FlexKomSID" SG_ 898 VC_BU_Suspension_Type 2027;
BA_ "FlexKomIsMotorola" SG_ 898 VC_BU_Suspension_Type 1;
BA_ "FlexKomComment" SG_ 898 VC_BU_Suspension_Type "Backup for vehicle configuration 7 packet";
BA_ "GenSigSNA" SG_ 898 VC_BU_GlareFree_Prsnt "0h";
BA_ "GenSigSendType" SG_ 898 VC_BU_GlareFree_Prsnt 1;
BA_ "FlexKomSigStartValue" SG_ 898 VC_BU_GlareFree_Prsnt "033F000000000000h";
BA_ "FlexKomSigStartPos" SG_ 898 VC_BU_GlareFree_Prsnt 7;
BA_ "FlexKomSigName" SG_ 898 VC_BU_GlareFree_Prsnt "VehCfgBU7_Pkt";
BA_ "FlexKomSigLaenge" SG_ 898 VC_BU_GlareFree_Prsnt 64;
BA_ "FlexKomSID" SG_ 898 VC_BU_GlareFree_Prsnt 2027;
BA_ "FlexKomIsMotorola" SG_ 898 VC_BU_GlareFree_Prsnt 1;
BA_ "FlexKomComment" SG_ 898 VC_BU_GlareFree_Prsnt "Backup for vehicle configuration 7 packet";
BA_ "GenSigSNA" SG_ 898 VC_BU_PAD_Lamp_Ctrl "0h";
BA_ "GenSigSendType" SG_ 898 VC_BU_PAD_Lamp_Ctrl 1;
BA_ "FlexKomSigStartValue" SG_ 898 VC_BU_PAD_Lamp_Ctrl "033F000000000000h";
BA_ "FlexKomSigStartPos" SG_ 898 VC_BU_PAD_Lamp_Ctrl 7;
BA_ "FlexKomSigName" SG_ 898 VC_BU_PAD_Lamp_Ctrl "VehCfgBU7_Pkt";
BA_ "FlexKomSigLaenge" SG_ 898 VC_BU_PAD_Lamp_Ctrl 64;
BA_ "FlexKomSID" SG_ 898 VC_BU_PAD_Lamp_Ctrl 2027;
BA_ "FlexKomIsMotorola" SG_ 898 VC_BU_PAD_Lamp_Ctrl 1;
BA_ "FlexKomComment" SG_ 898 VC_BU_PAD_Lamp_Ctrl "Backup for vehicle configuration 7 packet";
BA_ "GenSigSNA" SG_ 898 VC_BU_Vehicle_Package "0h";
BA_ "GenSigSendType" SG_ 898 VC_BU_Vehicle_Package 1;
BA_ "FlexKomSigStartValue" SG_ 898 VC_BU_Vehicle_Package "033F000000000000h";
BA_ "FlexKomSigStartPos" SG_ 898 VC_BU_Vehicle_Package 7;
BA_ "FlexKomSigName" SG_ 898 VC_BU_Vehicle_Package "VehCfgBU7_Pkt";
BA_ "FlexKomSigLaenge" SG_ 898 VC_BU_Vehicle_Package 64;
BA_ "FlexKomSID" SG_ 898 VC_BU_Vehicle_Package 2027;
BA_ "FlexKomIsMotorola" SG_ 898 VC_BU_Vehicle_Package 1;
BA_ "FlexKomComment" SG_ 898 VC_BU_Vehicle_Package "Backup for vehicle configuration 7 packet";
BA_ "GenSigSNA" SG_ 898 VC_BU_TrafficSignInfo "0h";
BA_ "GenSigSendType" SG_ 898 VC_BU_TrafficSignInfo 1;
BA_ "FlexKomSigStartValue" SG_ 898 VC_BU_TrafficSignInfo "033F000000000000h";
BA_ "FlexKomSigStartPos" SG_ 898 VC_BU_TrafficSignInfo 7;
BA_ "FlexKomSigName" SG_ 898 VC_BU_TrafficSignInfo "VehCfgBU7_Pkt";
BA_ "FlexKomSigLaenge" SG_ 898 VC_BU_TrafficSignInfo 64;
BA_ "FlexKomSID" SG_ 898 VC_BU_TrafficSignInfo 2027;
BA_ "FlexKomIsMotorola" SG_ 898 VC_BU_TrafficSignInfo 1;
BA_ "FlexKomComment" SG_ 898 VC_BU_TrafficSignInfo "Backup for vehicle configuration 7 packet";
BA_ "GenSigSNA" SG_ 898 VC_BU_LDW_Audio "0h";
BA_ "GenSigSendType" SG_ 898 VC_BU_LDW_Audio 1;
BA_ "FlexKomSigStartValue" SG_ 898 VC_BU_LDW_Audio "033F000000000000h";
BA_ "FlexKomSigStartPos" SG_ 898 VC_BU_LDW_Audio 7;
BA_ "FlexKomSigName" SG_ 898 VC_BU_LDW_Audio "VehCfgBU7_Pkt";
BA_ "FlexKomSigLaenge" SG_ 898 VC_BU_LDW_Audio 64;
BA_ "FlexKomSID" SG_ 898 VC_BU_LDW_Audio 2027;
BA_ "FlexKomIsMotorola" SG_ 898 VC_BU_LDW_Audio 1;
BA_ "FlexKomComment" SG_ 898 VC_BU_LDW_Audio "Backup for vehicle configuration";
BA_ "GenSigSNA" SG_ 898 VC_BU_LaneCentering "0h";
BA_ "GenSigSendType" SG_ 898 VC_BU_LaneCentering 1;
BA_ "FlexKomSigStartValue" SG_ 898 VC_BU_LaneCentering "033F000000000000h";
BA_ "FlexKomSigStartPos" SG_ 898 VC_BU_LaneCentering 7;
BA_ "FlexKomSigName" SG_ 898 VC_BU_LaneCentering "VehCfgBU7_Pkt";
BA_ "FlexKomSigLaenge" SG_ 898 VC_BU_LaneCentering 64;
BA_ "FlexKomSID" SG_ 898 VC_BU_LaneCentering 2027;
BA_ "FlexKomIsMotorola" SG_ 898 VC_BU_LaneCentering 1;
BA_ "FlexKomComment" SG_ 898 VC_BU_LaneCentering "Backup for vehicle configuration 7 packet";
BA_ "GenSigSNA" SG_ 904 TCM_HSC "0h";
BA_ "GenSigSendType" SG_ 904 TCM_HSC 1;
BA_ "FlexKomSigStartValue" SG_ 904 TCM_HSC "0000000000000000h";
BA_ "FlexKomSigStartPos" SG_ 904 TCM_HSC 7;
BA_ "FlexKomSigName" SG_ 904 TCM_HSC "TCM_HSC";
BA_ "FlexKomSigLaenge" SG_ 904 TCM_HSC 64;
BA_ "FlexKomSID" SG_ 904 TCM_HSC 801;
BA_ "FlexKomIsMotorola" SG_ 904 TCM_HSC 1;
BA_ "FlexKomComment" SG_ 904 TCM_HSC "Manual control at test bench";
BA_ "GenSigTimeout_ORC" SG_ 906 VC_VehCfg8_Stat 7000;
BA_ "GenSigTimeout_IC" SG_ 906 VC_VehCfg8_Stat 21000;
BA_ "GenSigStartValue" SG_ 906 VC_VehCfg8_Stat 3;
BA_ "GenSigSNA" SG_ 906 VC_VehCfg8_Stat "3h";
BA_ "GenSigSendType" SG_ 906 VC_VehCfg8_Stat 5;
BA_ "GenSigCycleTime" SG_ 906 VC_VehCfg8_Stat 2000;
BA_ "FlexKomSigStartValue" SG_ 906 VC_VehCfg8_Stat "0300000000000000h";
BA_ "FlexKomSigStartPos" SG_ 906 VC_VehCfg8_Stat 7;
BA_ "FlexKomSigName" SG_ 906 VC_VehCfg8_Stat "VehCfg8_Pkt";
BA_ "FlexKomSigLaenge" SG_ 906 VC_VehCfg8_Stat 64;
BA_ "FlexKomSID" SG_ 906 VC_VehCfg8_Stat 2722;
BA_ "FlexKomIsMotorola" SG_ 906 VC_VehCfg8_Stat 1;
BA_ "FlexKomComment" SG_ 906 VC_VehCfg8_Stat "Vehicle Configuration 8 Packet";
BA_ "GenSigSNA" SG_ 906 VC_TIPL_LOT "0h";
BA_ "GenSigSendType" SG_ 906 VC_TIPL_LOT 5;
BA_ "GenSigCycleTime" SG_ 906 VC_TIPL_LOT 2000;
BA_ "FlexKomSigStartValue" SG_ 906 VC_TIPL_LOT "0300000000000000h";
BA_ "FlexKomSigStartPos" SG_ 906 VC_TIPL_LOT 7;
BA_ "FlexKomSigName" SG_ 906 VC_TIPL_LOT "VehCfg8_Pkt";
BA_ "FlexKomSigLaenge" SG_ 906 VC_TIPL_LOT 64;
BA_ "FlexKomSID" SG_ 906 VC_TIPL_LOT 2722;
BA_ "FlexKomIsMotorola" SG_ 906 VC_TIPL_LOT 1;
BA_ "FlexKomComment" SG_ 906 VC_TIPL_LOT "Vehicle Configuration 8 Packet";
BA_ "GenSigTimeout_ORC" SG_ 906 VC_STFA_Prsnt 7000;
BA_ "GenSigTimeout_IC" SG_ 906 VC_STFA_Prsnt 21000;
BA_ "GenSigSNA" SG_ 906 VC_STFA_Prsnt "0h";
BA_ "GenSigSendType" SG_ 906 VC_STFA_Prsnt 5;
BA_ "GenSigCycleTime" SG_ 906 VC_STFA_Prsnt 2000;
BA_ "FlexKomSigStartValue" SG_ 906 VC_STFA_Prsnt "0300000000000000h";
BA_ "FlexKomSigStartPos" SG_ 906 VC_STFA_Prsnt 7;
BA_ "FlexKomSigName" SG_ 906 VC_STFA_Prsnt "VehCfg8_Pkt";
BA_ "FlexKomSigLaenge" SG_ 906 VC_STFA_Prsnt 64;
BA_ "FlexKomSID" SG_ 906 VC_STFA_Prsnt 2722;
BA_ "FlexKomIsMotorola" SG_ 906 VC_STFA_Prsnt 1;
BA_ "FlexKomComment" SG_ 906 VC_STFA_Prsnt "Vehicle Configuration 8 Packet";
BA_ "GenSigTimeout_ORC" SG_ 906 VC_Trans_Brake_PRSNT 7000;
BA_ "GenSigTimeout_IC" SG_ 906 VC_Trans_Brake_PRSNT 21000;
BA_ "GenSigSNA" SG_ 906 VC_Trans_Brake_PRSNT "0h";
BA_ "GenSigSendType" SG_ 906 VC_Trans_Brake_PRSNT 5;
BA_ "GenSigCycleTime" SG_ 906 VC_Trans_Brake_PRSNT 2000;
BA_ "FlexKomSigStartValue" SG_ 906 VC_Trans_Brake_PRSNT "0300000000000000h";
BA_ "FlexKomSigStartPos" SG_ 906 VC_Trans_Brake_PRSNT 7;
BA_ "FlexKomSigName" SG_ 906 VC_Trans_Brake_PRSNT "VehCfg8_Pkt";
BA_ "FlexKomSigLaenge" SG_ 906 VC_Trans_Brake_PRSNT 64;
BA_ "FlexKomSID" SG_ 906 VC_Trans_Brake_PRSNT 2722;
BA_ "FlexKomIsMotorola" SG_ 906 VC_Trans_Brake_PRSNT 1;
BA_ "FlexKomComment" SG_ 906 VC_Trans_Brake_PRSNT "Vehicle Configuration 8 Packet";
BA_ "GenSigTimeout_ORC" SG_ 906 VC_Steering_Cfactor 7000;
BA_ "GenSigTimeout_IC" SG_ 906 VC_Steering_Cfactor 21000;
BA_ "GenSigSNA" SG_ 906 VC_Steering_Cfactor "0h";
BA_ "GenSigSendType" SG_ 906 VC_Steering_Cfactor 5;
BA_ "GenSigCycleTime" SG_ 906 VC_Steering_Cfactor 2000;
BA_ "FlexKomSigStartValue" SG_ 906 VC_Steering_Cfactor "0300000000000000h";
BA_ "FlexKomSigStartPos" SG_ 906 VC_Steering_Cfactor 7;
BA_ "FlexKomSigName" SG_ 906 VC_Steering_Cfactor "VehCfg8_Pkt";
BA_ "FlexKomSigLaenge" SG_ 906 VC_Steering_Cfactor 64;
BA_ "FlexKomSID" SG_ 906 VC_Steering_Cfactor 2722;
BA_ "FlexKomIsMotorola" SG_ 906 VC_Steering_Cfactor 1;
BA_ "FlexKomComment" SG_ 906 VC_Steering_Cfactor "Vehicle Configuration 8 Packet";
BA_ "GenSigTimeout_ORC" SG_ 906 VC_LineLock_PRSNT 7000;
BA_ "GenSigTimeout_IC" SG_ 906 VC_LineLock_PRSNT 21000;
BA_ "GenSigSNA" SG_ 906 VC_LineLock_PRSNT "0h";
BA_ "GenSigSendType" SG_ 906 VC_LineLock_PRSNT 5;
BA_ "GenSigCycleTime" SG_ 906 VC_LineLock_PRSNT 2000;
BA_ "FlexKomSigStartValue" SG_ 906 VC_LineLock_PRSNT "0300000000000000h";
BA_ "FlexKomSigStartPos" SG_ 906 VC_LineLock_PRSNT 7;
BA_ "FlexKomSigName" SG_ 906 VC_LineLock_PRSNT "VehCfg8_Pkt";
BA_ "FlexKomSigLaenge" SG_ 906 VC_LineLock_PRSNT 64;
BA_ "FlexKomSID" SG_ 906 VC_LineLock_PRSNT 2722;
BA_ "FlexKomIsMotorola" SG_ 906 VC_LineLock_PRSNT 1;
BA_ "FlexKomComment" SG_ 906 VC_LineLock_PRSNT "Vehicle Configuration 8 Packet";
BA_ "GenSigTimeout_ORC" SG_ 906 VC_HighOctane_PRSNT 7000;
BA_ "GenSigTimeout_IC" SG_ 906 VC_HighOctane_PRSNT 21000;
BA_ "GenSigSNA" SG_ 906 VC_HighOctane_PRSNT "0h";
BA_ "GenSigSendType" SG_ 906 VC_HighOctane_PRSNT 5;
BA_ "GenSigCycleTime" SG_ 906 VC_HighOctane_PRSNT 2000;
BA_ "FlexKomSigStartValue" SG_ 906 VC_HighOctane_PRSNT "0300000000000000h";
BA_ "FlexKomSigStartPos" SG_ 906 VC_HighOctane_PRSNT 7;
BA_ "FlexKomSigName" SG_ 906 VC_HighOctane_PRSNT "VehCfg8_Pkt";
BA_ "FlexKomSigLaenge" SG_ 906 VC_HighOctane_PRSNT 64;
BA_ "FlexKomSID" SG_ 906 VC_HighOctane_PRSNT 2722;
BA_ "FlexKomIsMotorola" SG_ 906 VC_HighOctane_PRSNT 1;
BA_ "FlexKomComment" SG_ 906 VC_HighOctane_PRSNT "Vehicle Configuration 8 Packet";
BA_ "GenSigTimeout_ORC" SG_ 906 VC_CHILLER_PRSNT 7000;
BA_ "GenSigTimeout_IC" SG_ 906 VC_CHILLER_PRSNT 21000;
BA_ "GenSigSNA" SG_ 906 VC_CHILLER_PRSNT "0h";
BA_ "GenSigSendType" SG_ 906 VC_CHILLER_PRSNT 5;
BA_ "GenSigCycleTime" SG_ 906 VC_CHILLER_PRSNT 2000;
BA_ "FlexKomSigStartValue" SG_ 906 VC_CHILLER_PRSNT "0300000000000000h";
BA_ "FlexKomSigStartPos" SG_ 906 VC_CHILLER_PRSNT 7;
BA_ "FlexKomSigName" SG_ 906 VC_CHILLER_PRSNT "VehCfg8_Pkt";
BA_ "FlexKomSigLaenge" SG_ 906 VC_CHILLER_PRSNT 64;
BA_ "FlexKomSID" SG_ 906 VC_CHILLER_PRSNT 2722;
BA_ "FlexKomIsMotorola" SG_ 906 VC_CHILLER_PRSNT 1;
BA_ "FlexKomComment" SG_ 906 VC_CHILLER_PRSNT "Vehicle Configuration 8 Packet";
BA_ "GenSigTimeout_ORC" SG_ 906 VC_ARC_PRSNT 7000;
BA_ "GenSigTimeout_IC" SG_ 906 VC_ARC_PRSNT 21000;
BA_ "GenSigSNA" SG_ 906 VC_ARC_PRSNT "0h";
BA_ "GenSigSendType" SG_ 906 VC_ARC_PRSNT 5;
BA_ "GenSigCycleTime" SG_ 906 VC_ARC_PRSNT 2000;
BA_ "FlexKomSigStartValue" SG_ 906 VC_ARC_PRSNT "0300000000000000h";
BA_ "FlexKomSigStartPos" SG_ 906 VC_ARC_PRSNT 7;
BA_ "FlexKomSigName" SG_ 906 VC_ARC_PRSNT "VehCfg8_Pkt";
BA_ "FlexKomSigLaenge" SG_ 906 VC_ARC_PRSNT 64;
BA_ "FlexKomSID" SG_ 906 VC_ARC_PRSNT 2722;
BA_ "FlexKomIsMotorola" SG_ 906 VC_ARC_PRSNT 1;
BA_ "FlexKomComment" SG_ 906 VC_ARC_PRSNT "Vehicle Configuration 8 Packet";
BA_ "GenSigTimeout_RF_HUB" SG_ 906 VC_Speedometer_Tolerance 10500;
BA_ "GenSigTimeout_IC" SG_ 906 VC_Speedometer_Tolerance 10500;
BA_ "GenSigSNA" SG_ 906 VC_Speedometer_Tolerance "0h";
BA_ "GenSigSendType" SG_ 906 VC_Speedometer_Tolerance 5;
BA_ "GenSigCycleTime" SG_ 906 VC_Speedometer_Tolerance 2000;
BA_ "FlexKomSigStartValue" SG_ 906 VC_Speedometer_Tolerance "0300000000000000h";
BA_ "FlexKomSigStartPos" SG_ 906 VC_Speedometer_Tolerance 7;
BA_ "FlexKomSigName" SG_ 906 VC_Speedometer_Tolerance "VehCfg8_Pkt";
BA_ "FlexKomSigLaenge" SG_ 906 VC_Speedometer_Tolerance 64;
BA_ "FlexKomSID" SG_ 906 VC_Speedometer_Tolerance 2722;
BA_ "FlexKomIsMotorola" SG_ 906 VC_Speedometer_Tolerance 1;
BA_ "FlexKomComment" SG_ 906 VC_Speedometer_Tolerance "Vehicle Configuration 8 Packet";
BA_ "GenSigTimeout_RF_HUB" SG_ 906 VC_Increasing_Speed_Constant 10500;
BA_ "GenSigTimeout_IC" SG_ 906 VC_Increasing_Speed_Constant 10500;
BA_ "GenSigSNA" SG_ 906 VC_Increasing_Speed_Constant "0h";
BA_ "GenSigSendType" SG_ 906 VC_Increasing_Speed_Constant 5;
BA_ "GenSigCycleTime" SG_ 906 VC_Increasing_Speed_Constant 2000;
BA_ "FlexKomSigStartValue" SG_ 906 VC_Increasing_Speed_Constant "0300000000000000h";
BA_ "FlexKomSigStartPos" SG_ 906 VC_Increasing_Speed_Constant 7;
BA_ "FlexKomSigName" SG_ 906 VC_Increasing_Speed_Constant "VehCfg8_Pkt";
BA_ "FlexKomSigLaenge" SG_ 906 VC_Increasing_Speed_Constant 64;
BA_ "FlexKomSID" SG_ 906 VC_Increasing_Speed_Constant 2722;
BA_ "FlexKomIsMotorola" SG_ 906 VC_Increasing_Speed_Constant 1;
BA_ "FlexKomComment" SG_ 906 VC_Increasing_Speed_Constant "Vehicle Configuration 8 Packet";
BA_ "GenSigSNA" SG_ 906 VC_OvertakingBan "0h";
BA_ "GenSigSendType" SG_ 906 VC_OvertakingBan 5;
BA_ "GenSigCycleTime" SG_ 906 VC_OvertakingBan 2000;
BA_ "FlexKomSigStartValue" SG_ 906 VC_OvertakingBan "0300000000000000h";
BA_ "FlexKomSigStartPos" SG_ 906 VC_OvertakingBan 7;
BA_ "FlexKomSigName" SG_ 906 VC_OvertakingBan "VehCfg8_Pkt";
BA_ "FlexKomSigLaenge" SG_ 906 VC_OvertakingBan 64;
BA_ "FlexKomSID" SG_ 906 VC_OvertakingBan 2722;
BA_ "FlexKomIsMotorola" SG_ 906 VC_OvertakingBan 1;
BA_ "FlexKomComment" SG_ 906 VC_OvertakingBan "Vehicle Configuration 8 Packet";
BA_ "GenSigSNA" SG_ 906 VC_SBL_FBL_CORNERING_PRSNT "0h";
BA_ "GenSigSendType" SG_ 906 VC_SBL_FBL_CORNERING_PRSNT 5;
BA_ "GenSigCycleTime" SG_ 906 VC_SBL_FBL_CORNERING_PRSNT 2000;
BA_ "FlexKomSigStartValue" SG_ 906 VC_SBL_FBL_CORNERING_PRSNT "0300000000000000h";
BA_ "FlexKomSigStartPos" SG_ 906 VC_SBL_FBL_CORNERING_PRSNT 7;
BA_ "FlexKomSigName" SG_ 906 VC_SBL_FBL_CORNERING_PRSNT "VehCfg8_Pkt";
BA_ "FlexKomSigLaenge" SG_ 906 VC_SBL_FBL_CORNERING_PRSNT 64;
BA_ "FlexKomSID" SG_ 906 VC_SBL_FBL_CORNERING_PRSNT 2722;
BA_ "FlexKomIsMotorola" SG_ 906 VC_SBL_FBL_CORNERING_PRSNT 1;
BA_ "FlexKomComment" SG_ 906 VC_SBL_FBL_CORNERING_PRSNT "Vehicle Configuration 8 Packet";
BA_ "GenSigSNA" SG_ 906 VC_BEAM_SHAPING_PRSNT "0h";
BA_ "GenSigSendType" SG_ 906 VC_BEAM_SHAPING_PRSNT 5;
BA_ "GenSigCycleTime" SG_ 906 VC_BEAM_SHAPING_PRSNT 2000;
BA_ "FlexKomSigStartValue" SG_ 906 VC_BEAM_SHAPING_PRSNT "0300000000000000h";
BA_ "FlexKomSigStartPos" SG_ 906 VC_BEAM_SHAPING_PRSNT 7;
BA_ "FlexKomSigName" SG_ 906 VC_BEAM_SHAPING_PRSNT "VehCfg8_Pkt";
BA_ "FlexKomSigLaenge" SG_ 906 VC_BEAM_SHAPING_PRSNT 64;
BA_ "FlexKomSID" SG_ 906 VC_BEAM_SHAPING_PRSNT 2722;
BA_ "FlexKomIsMotorola" SG_ 906 VC_BEAM_SHAPING_PRSNT 1;
BA_ "FlexKomComment" SG_ 906 VC_BEAM_SHAPING_PRSNT "Vehicle Configuration 8 Packet";
BA_ "GenSigSNA" SG_ 906 VC_DBL_PRSNT "0h";
BA_ "GenSigSendType" SG_ 906 VC_DBL_PRSNT 5;
BA_ "GenSigCycleTime" SG_ 906 VC_DBL_PRSNT 2000;
BA_ "FlexKomSigStartValue" SG_ 906 VC_DBL_PRSNT "0300000000000000h";
BA_ "FlexKomSigStartPos" SG_ 906 VC_DBL_PRSNT 7;
BA_ "FlexKomSigName" SG_ 906 VC_DBL_PRSNT "VehCfg8_Pkt";
BA_ "FlexKomSigLaenge" SG_ 906 VC_DBL_PRSNT 64;
BA_ "FlexKomSID" SG_ 906 VC_DBL_PRSNT 2722;
BA_ "FlexKomIsMotorola" SG_ 906 VC_DBL_PRSNT 1;
BA_ "FlexKomComment" SG_ 906 VC_DBL_PRSNT "Vehicle Configuration 8 Packet";
BA_ "GenSigSNA" SG_ 906 VC_FADPrsnt "0h";
BA_ "GenSigSendType" SG_ 906 VC_FADPrsnt 5;
BA_ "GenSigCycleTime" SG_ 906 VC_FADPrsnt 2000;
BA_ "FlexKomSigStartValue" SG_ 906 VC_FADPrsnt "0300000000000000h";
BA_ "FlexKomSigStartPos" SG_ 906 VC_FADPrsnt 7;
BA_ "FlexKomSigName" SG_ 906 VC_FADPrsnt "VehCfg8_Pkt";
BA_ "FlexKomSigLaenge" SG_ 906 VC_FADPrsnt 64;
BA_ "FlexKomSID" SG_ 906 VC_FADPrsnt 2722;
BA_ "FlexKomIsMotorola" SG_ 906 VC_FADPrsnt 1;
BA_ "FlexKomComment" SG_ 906 VC_FADPrsnt "Vehicle Configuration 8 Packet";
BA_ "GenSigSNA" SG_ 906 VC_AVAC_PRSNT "0h";
BA_ "GenSigSendType" SG_ 906 VC_AVAC_PRSNT 5;
BA_ "GenSigCycleTime" SG_ 906 VC_AVAC_PRSNT 2000;
BA_ "FlexKomSigStartValue" SG_ 906 VC_AVAC_PRSNT "0300000000000000h";
BA_ "FlexKomSigStartPos" SG_ 906 VC_AVAC_PRSNT 7;
BA_ "FlexKomSigName" SG_ 906 VC_AVAC_PRSNT "VehCfg8_Pkt";
BA_ "FlexKomSigLaenge" SG_ 906 VC_AVAC_PRSNT 64;
BA_ "FlexKomSID" SG_ 906 VC_AVAC_PRSNT 2722;
BA_ "FlexKomIsMotorola" SG_ 906 VC_AVAC_PRSNT 1;
BA_ "FlexKomComment" SG_ 906 VC_AVAC_PRSNT "Vehicle Configuration 8 Packet";
BA_ "GenSigSendType" SG_ 906 VC_WHL_BASE_LENGTH 5;
BA_ "GenSigCycleTime" SG_ 906 VC_WHL_BASE_LENGTH 2000;
BA_ "FlexKomSigStartValue" SG_ 906 VC_WHL_BASE_LENGTH "0300000000000000h";
BA_ "FlexKomSigStartPos" SG_ 906 VC_WHL_BASE_LENGTH 7;
BA_ "FlexKomSigName" SG_ 906 VC_WHL_BASE_LENGTH "VehCfg8_Pkt";
BA_ "FlexKomSigLaenge" SG_ 906 VC_WHL_BASE_LENGTH 64;
BA_ "FlexKomSID" SG_ 906 VC_WHL_BASE_LENGTH 2722;
BA_ "FlexKomIsMotorola" SG_ 906 VC_WHL_BASE_LENGTH 1;
BA_ "FlexKomComment" SG_ 906 VC_WHL_BASE_LENGTH "Vehicle Configuration 8 Packet";
BA_ "GenSigSendType" SG_ 906 VC_VP_Level 5;
BA_ "GenSigCycleTime" SG_ 906 VC_VP_Level 2000;
BA_ "FlexKomSigStartValue" SG_ 906 VC_VP_Level "0300000000000000h";
BA_ "FlexKomSigStartPos" SG_ 906 VC_VP_Level 7;
BA_ "FlexKomSigName" SG_ 906 VC_VP_Level "VehCfg8_Pkt";
BA_ "FlexKomSigLaenge" SG_ 906 VC_VP_Level 64;
BA_ "FlexKomSID" SG_ 906 VC_VP_Level 2722;
BA_ "FlexKomIsMotorola" SG_ 906 VC_VP_Level 1;
BA_ "FlexKomComment" SG_ 906 VC_VP_Level "Vehicle Configuration 8 Packet";
BA_ "GenSigSNA" SG_ 906 VC_OFFRoadModePrsnt "0h";
BA_ "GenSigSendType" SG_ 906 VC_OFFRoadModePrsnt 5;
BA_ "GenSigCycleTime" SG_ 906 VC_OFFRoadModePrsnt 2000;
BA_ "FlexKomSigStartValue" SG_ 906 VC_OFFRoadModePrsnt "0300000000000000h";
BA_ "FlexKomSigStartPos" SG_ 906 VC_OFFRoadModePrsnt 7;
BA_ "FlexKomSigName" SG_ 906 VC_OFFRoadModePrsnt "VehCfg8_Pkt";
BA_ "FlexKomSigLaenge" SG_ 906 VC_OFFRoadModePrsnt 64;
BA_ "FlexKomSID" SG_ 906 VC_OFFRoadModePrsnt 2722;
BA_ "FlexKomIsMotorola" SG_ 906 VC_OFFRoadModePrsnt 1;
BA_ "FlexKomComment" SG_ 906 VC_OFFRoadModePrsnt "Vehicle Configuration 8 Packet";
BA_ "GenSigSNA" SG_ 906 VC_OFFroad_Camera "0h";
BA_ "GenSigSendType" SG_ 906 VC_OFFroad_Camera 5;
BA_ "GenSigCycleTime" SG_ 906 VC_OFFroad_Camera 2000;
BA_ "FlexKomSigStartValue" SG_ 906 VC_OFFroad_Camera "0300000000000000h";
BA_ "FlexKomSigStartPos" SG_ 906 VC_OFFroad_Camera 7;
BA_ "FlexKomSigName" SG_ 906 VC_OFFroad_Camera "VehCfg8_Pkt";
BA_ "FlexKomSigLaenge" SG_ 906 VC_OFFroad_Camera 64;
BA_ "FlexKomSID" SG_ 906 VC_OFFroad_Camera 2722;
BA_ "FlexKomIsMotorola" SG_ 906 VC_OFFroad_Camera 1;
BA_ "FlexKomComment" SG_ 906 VC_OFFroad_Camera "Vehicle Configuration 8 Packet";
BA_ "GenSigSNA" SG_ 906 VC_PPPAHardBtn "0h";
BA_ "GenSigSendType" SG_ 906 VC_PPPAHardBtn 5;
BA_ "GenSigCycleTime" SG_ 906 VC_PPPAHardBtn 2000;
BA_ "FlexKomSigStartValue" SG_ 906 VC_PPPAHardBtn "0300000000000000h";
BA_ "FlexKomSigStartPos" SG_ 906 VC_PPPAHardBtn 7;
BA_ "FlexKomSigName" SG_ 906 VC_PPPAHardBtn "VehCfg8_Pkt";
BA_ "FlexKomSigLaenge" SG_ 906 VC_PPPAHardBtn 64;
BA_ "FlexKomSID" SG_ 906 VC_PPPAHardBtn 2722;
BA_ "FlexKomIsMotorola" SG_ 906 VC_PPPAHardBtn 1;
BA_ "FlexKomComment" SG_ 906 VC_PPPAHardBtn "Vehicle Configuration 8 Packet";
BA_ "GenSigSNA" SG_ 906 VC_PEB_PRSNT "0h";
BA_ "GenSigSendType" SG_ 906 VC_PEB_PRSNT 5;
BA_ "GenSigCycleTime" SG_ 906 VC_PEB_PRSNT 2000;
BA_ "FlexKomSigStartValue" SG_ 906 VC_PEB_PRSNT "0300000000000000h";
BA_ "FlexKomSigStartPos" SG_ 906 VC_PEB_PRSNT 7;
BA_ "FlexKomSigName" SG_ 906 VC_PEB_PRSNT "VehCfg8_Pkt";
BA_ "FlexKomSigLaenge" SG_ 906 VC_PEB_PRSNT 64;
BA_ "FlexKomSID" SG_ 906 VC_PEB_PRSNT 2722;
BA_ "FlexKomIsMotorola" SG_ 906 VC_PEB_PRSNT 1;
BA_ "FlexKomComment" SG_ 906 VC_PEB_PRSNT "Vehicle Configuration 8 Packet";
BA_ "GenSigSNA" SG_ 906 VC_TACHO_TYPE "0h";
BA_ "GenSigSendType" SG_ 906 VC_TACHO_TYPE 5;
BA_ "GenSigCycleTime" SG_ 906 VC_TACHO_TYPE 2000;
BA_ "FlexKomSigStartValue" SG_ 906 VC_TACHO_TYPE "0300000000000000h";
BA_ "FlexKomSigStartPos" SG_ 906 VC_TACHO_TYPE 7;
BA_ "FlexKomSigName" SG_ 906 VC_TACHO_TYPE "VehCfg8_Pkt";
BA_ "FlexKomSigLaenge" SG_ 906 VC_TACHO_TYPE 64;
BA_ "FlexKomSID" SG_ 906 VC_TACHO_TYPE 2722;
BA_ "FlexKomIsMotorola" SG_ 906 VC_TACHO_TYPE 1;
BA_ "FlexKomComment" SG_ 906 VC_TACHO_TYPE "Vehicle Configuration 8 Packet";
BA_ "GenSigSNA" SG_ 906 VC_INDIA_SPEED_WARNING "0h";
BA_ "GenSigSendType" SG_ 906 VC_INDIA_SPEED_WARNING 5;
BA_ "GenSigCycleTime" SG_ 906 VC_INDIA_SPEED_WARNING 2000;
BA_ "FlexKomSigStartValue" SG_ 906 VC_INDIA_SPEED_WARNING "0300000000000000h";
BA_ "FlexKomSigStartPos" SG_ 906 VC_INDIA_SPEED_WARNING 7;
BA_ "FlexKomSigName" SG_ 906 VC_INDIA_SPEED_WARNING "VehCfg8_Pkt";
BA_ "FlexKomSigLaenge" SG_ 906 VC_INDIA_SPEED_WARNING 64;
BA_ "FlexKomSID" SG_ 906 VC_INDIA_SPEED_WARNING 2722;
BA_ "FlexKomIsMotorola" SG_ 906 VC_INDIA_SPEED_WARNING 1;
BA_ "FlexKomComment" SG_ 906 VC_INDIA_SPEED_WARNING "Vehicle Configuration 8 Packet";
BA_ "GenSigTimeout_CBC" SG_ 907 VC_BU_Increasing_Speed_Constant 10500;
BA_ "GenSigSNA" SG_ 907 VC_BU_Increasing_Speed_Constant "0h";
BA_ "GenSigSendType" SG_ 907 VC_BU_Increasing_Speed_Constant 1;
BA_ "FlexKomSigStartValue" SG_ 907 VC_BU_Increasing_Speed_Constant "0300000000000000h";
BA_ "FlexKomSigStartPos" SG_ 907 VC_BU_Increasing_Speed_Constant 7;
BA_ "FlexKomSigName" SG_ 907 VC_BU_Increasing_Speed_Constant "VehCfgBU8_Pkt";
BA_ "FlexKomSigLaenge" SG_ 907 VC_BU_Increasing_Speed_Constant 64;
BA_ "FlexKomSID" SG_ 907 VC_BU_Increasing_Speed_Constant 2723;
BA_ "FlexKomIsMotorola" SG_ 907 VC_BU_Increasing_Speed_Constant 1;
BA_ "FlexKomComment" SG_ 907 VC_BU_Increasing_Speed_Constant "Backup Vehicle Configuration 8 Packet";
BA_ "GenSigSNA" SG_ 907 VC_BU_OvertakingBan "0h";
BA_ "GenSigSendType" SG_ 907 VC_BU_OvertakingBan 1;
BA_ "FlexKomSigStartValue" SG_ 907 VC_BU_OvertakingBan "0300000000000000h";
BA_ "FlexKomSigStartPos" SG_ 907 VC_BU_OvertakingBan 7;
BA_ "FlexKomSigName" SG_ 907 VC_BU_OvertakingBan "VehCfgBU8_Pkt";
BA_ "FlexKomSigLaenge" SG_ 907 VC_BU_OvertakingBan 64;
BA_ "FlexKomSID" SG_ 907 VC_BU_OvertakingBan 2723;
BA_ "FlexKomIsMotorola" SG_ 907 VC_BU_OvertakingBan 1;
BA_ "FlexKomComment" SG_ 907 VC_BU_OvertakingBan "Backup Vehicle Configuration 8 Packet";
BA_ "GenSigSNA" SG_ 907 VC_BU_SBL_FBL_CORNERING_PRSNT "0h";
BA_ "GenSigSendType" SG_ 907 VC_BU_SBL_FBL_CORNERING_PRSNT 1;
BA_ "FlexKomSigStartValue" SG_ 907 VC_BU_SBL_FBL_CORNERING_PRSNT "0300000000000000h";
BA_ "FlexKomSigStartPos" SG_ 907 VC_BU_SBL_FBL_CORNERING_PRSNT 7;
BA_ "FlexKomSigName" SG_ 907 VC_BU_SBL_FBL_CORNERING_PRSNT "VehCfgBU8_Pkt";
BA_ "FlexKomSigLaenge" SG_ 907 VC_BU_SBL_FBL_CORNERING_PRSNT 64;
BA_ "FlexKomSID" SG_ 907 VC_BU_SBL_FBL_CORNERING_PRSNT 2723;
BA_ "FlexKomIsMotorola" SG_ 907 VC_BU_SBL_FBL_CORNERING_PRSNT 1;
BA_ "FlexKomComment" SG_ 907 VC_BU_SBL_FBL_CORNERING_PRSNT "Backup Vehicle Configuration 8 Packet";
BA_ "GenSigSNA" SG_ 907 VC_BU_BEAM_SHAPING_PRSNT "0h";
BA_ "GenSigSendType" SG_ 907 VC_BU_BEAM_SHAPING_PRSNT 1;
BA_ "FlexKomSigStartValue" SG_ 907 VC_BU_BEAM_SHAPING_PRSNT "0300000000000000h";
BA_ "FlexKomSigStartPos" SG_ 907 VC_BU_BEAM_SHAPING_PRSNT 7;
BA_ "FlexKomSigName" SG_ 907 VC_BU_BEAM_SHAPING_PRSNT "VehCfgBU8_Pkt";
BA_ "FlexKomSigLaenge" SG_ 907 VC_BU_BEAM_SHAPING_PRSNT 64;
BA_ "FlexKomSID" SG_ 907 VC_BU_BEAM_SHAPING_PRSNT 2723;
BA_ "FlexKomIsMotorola" SG_ 907 VC_BU_BEAM_SHAPING_PRSNT 1;
BA_ "FlexKomComment" SG_ 907 VC_BU_BEAM_SHAPING_PRSNT "Backup Vehicle Configuration 8 Packet";
BA_ "GenSigSNA" SG_ 907 VC_BU_DBL_PRSNT "0h";
BA_ "GenSigSendType" SG_ 907 VC_BU_DBL_PRSNT 1;
BA_ "FlexKomSigStartValue" SG_ 907 VC_BU_DBL_PRSNT "0300000000000000h";
BA_ "FlexKomSigStartPos" SG_ 907 VC_BU_DBL_PRSNT 7;
BA_ "FlexKomSigName" SG_ 907 VC_BU_DBL_PRSNT "VehCfgBU8_Pkt";
BA_ "FlexKomSigLaenge" SG_ 907 VC_BU_DBL_PRSNT 64;
BA_ "FlexKomSID" SG_ 907 VC_BU_DBL_PRSNT 2723;
BA_ "FlexKomIsMotorola" SG_ 907 VC_BU_DBL_PRSNT 1;
BA_ "FlexKomComment" SG_ 907 VC_BU_DBL_PRSNT "Backup Vehicle Configuration 8 Packet";
BA_ "GenSigSNA" SG_ 907 VC_BU_FADPrsnt "0h";
BA_ "GenSigSendType" SG_ 907 VC_BU_FADPrsnt 1;
BA_ "FlexKomSigStartValue" SG_ 907 VC_BU_FADPrsnt "0300000000000000h";
BA_ "FlexKomSigStartPos" SG_ 907 VC_BU_FADPrsnt 7;
BA_ "FlexKomSigName" SG_ 907 VC_BU_FADPrsnt "VehCfgBU8_Pkt";
BA_ "FlexKomSigLaenge" SG_ 907 VC_BU_FADPrsnt 64;
BA_ "FlexKomSID" SG_ 907 VC_BU_FADPrsnt 2723;
BA_ "FlexKomIsMotorola" SG_ 907 VC_BU_FADPrsnt 1;
BA_ "FlexKomComment" SG_ 907 VC_BU_FADPrsnt "Backup Vehicle Configuration 8 Packet";
BA_ "GenSigSNA" SG_ 907 VC_BU_AVAC_PRSNT "0h";
BA_ "GenSigSendType" SG_ 907 VC_BU_AVAC_PRSNT 1;
BA_ "FlexKomSigStartValue" SG_ 907 VC_BU_AVAC_PRSNT "0300000000000000h";
BA_ "FlexKomSigStartPos" SG_ 907 VC_BU_AVAC_PRSNT 7;
BA_ "FlexKomSigName" SG_ 907 VC_BU_AVAC_PRSNT "VehCfgBU8_Pkt";
BA_ "FlexKomSigLaenge" SG_ 907 VC_BU_AVAC_PRSNT 64;
BA_ "FlexKomSID" SG_ 907 VC_BU_AVAC_PRSNT 2723;
BA_ "FlexKomIsMotorola" SG_ 907 VC_BU_AVAC_PRSNT 1;
BA_ "FlexKomComment" SG_ 907 VC_BU_AVAC_PRSNT "Backup Vehicle Configuration 8 Packet";
BA_ "GenSigSendType" SG_ 907 VC_BU_WHL_BASE_LENGTH 1;
BA_ "FlexKomSigStartValue" SG_ 907 VC_BU_WHL_BASE_LENGTH "0300000000000000h";
BA_ "FlexKomSigStartPos" SG_ 907 VC_BU_WHL_BASE_LENGTH 7;
BA_ "FlexKomSigName" SG_ 907 VC_BU_WHL_BASE_LENGTH "VehCfgBU8_Pkt";
BA_ "FlexKomSigLaenge" SG_ 907 VC_BU_WHL_BASE_LENGTH 64;
BA_ "FlexKomSID" SG_ 907 VC_BU_WHL_BASE_LENGTH 2723;
BA_ "FlexKomIsMotorola" SG_ 907 VC_BU_WHL_BASE_LENGTH 1;
BA_ "FlexKomComment" SG_ 907 VC_BU_WHL_BASE_LENGTH "Backup Vehicle Configuration 8 Packet";
BA_ "GenSigSendType" SG_ 907 VC_BU_VP_Level 1;
BA_ "FlexKomSigStartValue" SG_ 907 VC_BU_VP_Level "0300000000000000h";
BA_ "FlexKomSigStartPos" SG_ 907 VC_BU_VP_Level 7;
BA_ "FlexKomSigName" SG_ 907 VC_BU_VP_Level "VehCfgBU8_Pkt";
BA_ "FlexKomSigLaenge" SG_ 907 VC_BU_VP_Level 64;
BA_ "FlexKomSID" SG_ 907 VC_BU_VP_Level 2723;
BA_ "FlexKomIsMotorola" SG_ 907 VC_BU_VP_Level 1;
BA_ "FlexKomComment" SG_ 907 VC_BU_VP_Level "Backup Vehicle Configuration 8 Packet";
BA_ "GenSigSNA" SG_ 907 VC_BU_OFFRoadModePrsnt "0h";
BA_ "GenSigSendType" SG_ 907 VC_BU_OFFRoadModePrsnt 1;
BA_ "FlexKomSigStartValue" SG_ 907 VC_BU_OFFRoadModePrsnt "0300000000000000h";
BA_ "FlexKomSigStartPos" SG_ 907 VC_BU_OFFRoadModePrsnt 7;
BA_ "FlexKomSigName" SG_ 907 VC_BU_OFFRoadModePrsnt "VehCfgBU8_Pkt";
BA_ "FlexKomSigLaenge" SG_ 907 VC_BU_OFFRoadModePrsnt 64;
BA_ "FlexKomSID" SG_ 907 VC_BU_OFFRoadModePrsnt 2723;
BA_ "FlexKomIsMotorola" SG_ 907 VC_BU_OFFRoadModePrsnt 1;
BA_ "FlexKomComment" SG_ 907 VC_BU_OFFRoadModePrsnt "Backup Vehicle Configuration 8 Packet";
BA_ "GenSigSNA" SG_ 907 VC_BU_OFFroad_Camera "0h";
BA_ "GenSigSendType" SG_ 907 VC_BU_OFFroad_Camera 1;
BA_ "FlexKomSigStartValue" SG_ 907 VC_BU_OFFroad_Camera "0300000000000000h";
BA_ "FlexKomSigStartPos" SG_ 907 VC_BU_OFFroad_Camera 7;
BA_ "FlexKomSigName" SG_ 907 VC_BU_OFFroad_Camera "VehCfgBU8_Pkt";
BA_ "FlexKomSigLaenge" SG_ 907 VC_BU_OFFroad_Camera 64;
BA_ "FlexKomSID" SG_ 907 VC_BU_OFFroad_Camera 2723;
BA_ "FlexKomIsMotorola" SG_ 907 VC_BU_OFFroad_Camera 1;
BA_ "FlexKomComment" SG_ 907 VC_BU_OFFroad_Camera "Backup Vehicle Configuration 8 Packet";
BA_ "GenSigSNA" SG_ 907 VC_BU_PPPAHardBtn "0h";
BA_ "GenSigSendType" SG_ 907 VC_BU_PPPAHardBtn 1;
BA_ "FlexKomSigStartValue" SG_ 907 VC_BU_PPPAHardBtn "0300000000000000h";
BA_ "FlexKomSigStartPos" SG_ 907 VC_BU_PPPAHardBtn 7;
BA_ "FlexKomSigName" SG_ 907 VC_BU_PPPAHardBtn "VehCfgBU8_Pkt";
BA_ "FlexKomSigLaenge" SG_ 907 VC_BU_PPPAHardBtn 64;
BA_ "FlexKomSID" SG_ 907 VC_BU_PPPAHardBtn 2723;
BA_ "FlexKomIsMotorola" SG_ 907 VC_BU_PPPAHardBtn 1;
BA_ "FlexKomComment" SG_ 907 VC_BU_PPPAHardBtn "Backup Vehicle Configuration 8 Packet";
BA_ "GenSigTimeout_CBC" SG_ 907 VC_BU_Speedometer_Tolerance 10500;
BA_ "GenSigSNA" SG_ 907 VC_BU_Speedometer_Tolerance "0h";
BA_ "GenSigSendType" SG_ 907 VC_BU_Speedometer_Tolerance 1;
BA_ "FlexKomSigStartValue" SG_ 907 VC_BU_Speedometer_Tolerance "0300000000000000h";
BA_ "FlexKomSigStartPos" SG_ 907 VC_BU_Speedometer_Tolerance 7;
BA_ "FlexKomSigName" SG_ 907 VC_BU_Speedometer_Tolerance "VehCfgBU8_Pkt";
BA_ "FlexKomSigLaenge" SG_ 907 VC_BU_Speedometer_Tolerance 64;
BA_ "FlexKomSID" SG_ 907 VC_BU_Speedometer_Tolerance 2723;
BA_ "FlexKomIsMotorola" SG_ 907 VC_BU_Speedometer_Tolerance 1;
BA_ "FlexKomComment" SG_ 907 VC_BU_Speedometer_Tolerance "Backup Vehicle Configuration 8 Packet";
BA_ "GenSigStartValue" SG_ 907 VC_BU_VehCfg8_Stat 3;
BA_ "GenSigSNA" SG_ 907 VC_BU_VehCfg8_Stat "3h";
BA_ "GenSigSendType" SG_ 907 VC_BU_VehCfg8_Stat 1;
BA_ "FlexKomSigStartValue" SG_ 907 VC_BU_VehCfg8_Stat "0300000000000000h";
BA_ "FlexKomSigStartPos" SG_ 907 VC_BU_VehCfg8_Stat 7;
BA_ "FlexKomSigName" SG_ 907 VC_BU_VehCfg8_Stat "VehCfgBU8_Pkt";
BA_ "FlexKomSigLaenge" SG_ 907 VC_BU_VehCfg8_Stat 64;
BA_ "FlexKomSID" SG_ 907 VC_BU_VehCfg8_Stat 2723;
BA_ "FlexKomIsMotorola" SG_ 907 VC_BU_VehCfg8_Stat 1;
BA_ "FlexKomComment" SG_ 907 VC_BU_VehCfg8_Stat "Backup Vehicle Configuration 8 Packet";
BA_ "GenSigSNA" SG_ 907 VC_BU_TIPL_LOT "0h";
BA_ "GenSigSendType" SG_ 907 VC_BU_TIPL_LOT 1;
BA_ "FlexKomSigStartValue" SG_ 907 VC_BU_TIPL_LOT "0300000000000000h";
BA_ "FlexKomSigStartPos" SG_ 907 VC_BU_TIPL_LOT 7;
BA_ "FlexKomSigName" SG_ 907 VC_BU_TIPL_LOT "VehCfgBU8_Pkt";
BA_ "FlexKomSigLaenge" SG_ 907 VC_BU_TIPL_LOT 64;
BA_ "FlexKomSID" SG_ 907 VC_BU_TIPL_LOT 2723;
BA_ "FlexKomIsMotorola" SG_ 907 VC_BU_TIPL_LOT 1;
BA_ "FlexKomComment" SG_ 907 VC_BU_TIPL_LOT "Backup Vehicle Configuration 8 Packet";
BA_ "GenSigSNA" SG_ 907 VC_BU_STFA_Prsnt "0h";
BA_ "GenSigSendType" SG_ 907 VC_BU_STFA_Prsnt 1;
BA_ "FlexKomSigStartValue" SG_ 907 VC_BU_STFA_Prsnt "0300000000000000h";
BA_ "FlexKomSigStartPos" SG_ 907 VC_BU_STFA_Prsnt 7;
BA_ "FlexKomSigName" SG_ 907 VC_BU_STFA_Prsnt "VehCfgBU8_Pkt";
BA_ "FlexKomSigLaenge" SG_ 907 VC_BU_STFA_Prsnt 64;
BA_ "FlexKomSID" SG_ 907 VC_BU_STFA_Prsnt 2723;
BA_ "FlexKomIsMotorola" SG_ 907 VC_BU_STFA_Prsnt 1;
BA_ "FlexKomComment" SG_ 907 VC_BU_STFA_Prsnt "Backup Vehicle Configuration 8 Packet";
BA_ "GenSigSNA" SG_ 907 VC_BU_Steering_Cfactor "0h";
BA_ "GenSigSendType" SG_ 907 VC_BU_Steering_Cfactor 1;
BA_ "FlexKomSigStartValue" SG_ 907 VC_BU_Steering_Cfactor "0300000000000000h";
BA_ "FlexKomSigStartPos" SG_ 907 VC_BU_Steering_Cfactor 7;
BA_ "FlexKomSigName" SG_ 907 VC_BU_Steering_Cfactor "VehCfgBU8_Pkt";
BA_ "FlexKomSigLaenge" SG_ 907 VC_BU_Steering_Cfactor 64;
BA_ "FlexKomSID" SG_ 907 VC_BU_Steering_Cfactor 2723;
BA_ "FlexKomIsMotorola" SG_ 907 VC_BU_Steering_Cfactor 1;
BA_ "FlexKomComment" SG_ 907 VC_BU_Steering_Cfactor "Backup Vehicle Configuration 8 Packet";
BA_ "GenSigSNA" SG_ 907 VC_BU_LineLock_PRSNT "0h";
BA_ "GenSigSendType" SG_ 907 VC_BU_LineLock_PRSNT 1;
BA_ "FlexKomSigStartValue" SG_ 907 VC_BU_LineLock_PRSNT "0300000000000000h";
BA_ "FlexKomSigStartPos" SG_ 907 VC_BU_LineLock_PRSNT 7;
BA_ "FlexKomSigName" SG_ 907 VC_BU_LineLock_PRSNT "VehCfgBU8_Pkt";
BA_ "FlexKomSigLaenge" SG_ 907 VC_BU_LineLock_PRSNT 64;
BA_ "FlexKomSID" SG_ 907 VC_BU_LineLock_PRSNT 2723;
BA_ "FlexKomIsMotorola" SG_ 907 VC_BU_LineLock_PRSNT 1;
BA_ "FlexKomComment" SG_ 907 VC_BU_LineLock_PRSNT "Backup Vehicle Configuration 8 Packet";
BA_ "GenSigSNA" SG_ 907 VC_BU_ARC_PRSNT "0h";
BA_ "GenSigSendType" SG_ 907 VC_BU_ARC_PRSNT 1;
BA_ "FlexKomSigStartValue" SG_ 907 VC_BU_ARC_PRSNT "0300000000000000h";
BA_ "FlexKomSigStartPos" SG_ 907 VC_BU_ARC_PRSNT 7;
BA_ "FlexKomSigName" SG_ 907 VC_BU_ARC_PRSNT "VehCfgBU8_Pkt";
BA_ "FlexKomSigLaenge" SG_ 907 VC_BU_ARC_PRSNT 64;
BA_ "FlexKomSID" SG_ 907 VC_BU_ARC_PRSNT 2723;
BA_ "FlexKomIsMotorola" SG_ 907 VC_BU_ARC_PRSNT 1;
BA_ "FlexKomComment" SG_ 907 VC_BU_ARC_PRSNT "Backup Vehicle Configuration 8 Packet";
BA_ "GenSigSNA" SG_ 907 VC_BU_CHILLER_PRSNT "0h";
BA_ "GenSigSendType" SG_ 907 VC_BU_CHILLER_PRSNT 1;
BA_ "FlexKomSigStartValue" SG_ 907 VC_BU_CHILLER_PRSNT "0300000000000000h";
BA_ "FlexKomSigStartPos" SG_ 907 VC_BU_CHILLER_PRSNT 7;
BA_ "FlexKomSigName" SG_ 907 VC_BU_CHILLER_PRSNT "VehCfgBU8_Pkt";
BA_ "FlexKomSigLaenge" SG_ 907 VC_BU_CHILLER_PRSNT 64;
BA_ "FlexKomSID" SG_ 907 VC_BU_CHILLER_PRSNT 2723;
BA_ "FlexKomIsMotorola" SG_ 907 VC_BU_CHILLER_PRSNT 1;
BA_ "FlexKomComment" SG_ 907 VC_BU_CHILLER_PRSNT "Backup Vehicle Configuration 8 Packet";
BA_ "GenSigSNA" SG_ 907 VC_BU_HighOctane_PRSNT "0h";
BA_ "GenSigSendType" SG_ 907 VC_BU_HighOctane_PRSNT 1;
BA_ "FlexKomSigStartValue" SG_ 907 VC_BU_HighOctane_PRSNT "0300000000000000h";
BA_ "FlexKomSigStartPos" SG_ 907 VC_BU_HighOctane_PRSNT 7;
BA_ "FlexKomSigName" SG_ 907 VC_BU_HighOctane_PRSNT "VehCfgBU8_Pkt";
BA_ "FlexKomSigLaenge" SG_ 907 VC_BU_HighOctane_PRSNT 64;
BA_ "FlexKomSID" SG_ 907 VC_BU_HighOctane_PRSNT 2723;
BA_ "FlexKomIsMotorola" SG_ 907 VC_BU_HighOctane_PRSNT 1;
BA_ "FlexKomComment" SG_ 907 VC_BU_HighOctane_PRSNT "Backup Vehicle Configuration 8 Packet";
BA_ "GenSigSNA" SG_ 907 VC_BU_Trans_Brake_PRSNT "0h";
BA_ "GenSigSendType" SG_ 907 VC_BU_Trans_Brake_PRSNT 1;
BA_ "FlexKomSigStartValue" SG_ 907 VC_BU_Trans_Brake_PRSNT "0300000000000000h";
BA_ "FlexKomSigStartPos" SG_ 907 VC_BU_Trans_Brake_PRSNT 7;
BA_ "FlexKomSigName" SG_ 907 VC_BU_Trans_Brake_PRSNT "VehCfgBU8_Pkt";
BA_ "FlexKomSigLaenge" SG_ 907 VC_BU_Trans_Brake_PRSNT 64;
BA_ "FlexKomSID" SG_ 907 VC_BU_Trans_Brake_PRSNT 2723;
BA_ "FlexKomIsMotorola" SG_ 907 VC_BU_Trans_Brake_PRSNT 1;
BA_ "FlexKomComment" SG_ 907 VC_BU_Trans_Brake_PRSNT "Backup Vehicle Configuration 8 Packet";
BA_ "GenSigSNA" SG_ 907 VC_BU_PEB_PRSNT "0h";
BA_ "GenSigSendType" SG_ 907 VC_BU_PEB_PRSNT 1;
BA_ "FlexKomSigStartValue" SG_ 907 VC_BU_PEB_PRSNT "0300000000000000h";
BA_ "FlexKomSigStartPos" SG_ 907 VC_BU_PEB_PRSNT 7;
BA_ "FlexKomSigName" SG_ 907 VC_BU_PEB_PRSNT "VehCfgBU8_Pkt";
BA_ "FlexKomSigLaenge" SG_ 907 VC_BU_PEB_PRSNT 64;
BA_ "FlexKomSID" SG_ 907 VC_BU_PEB_PRSNT 2723;
BA_ "FlexKomIsMotorola" SG_ 907 VC_BU_PEB_PRSNT 1;
BA_ "FlexKomComment" SG_ 907 VC_BU_PEB_PRSNT "Backup Vehicle Configuration 8 Packet";
BA_ "GenSigSNA" SG_ 907 VC_BU_TACHO_TYPE "0h";
BA_ "GenSigSendType" SG_ 907 VC_BU_TACHO_TYPE 1;
BA_ "FlexKomSigStartValue" SG_ 907 VC_BU_TACHO_TYPE "0300000000000000h";
BA_ "FlexKomSigStartPos" SG_ 907 VC_BU_TACHO_TYPE 7;
BA_ "FlexKomSigName" SG_ 907 VC_BU_TACHO_TYPE "VehCfgBU8_Pkt";
BA_ "FlexKomSigLaenge" SG_ 907 VC_BU_TACHO_TYPE 64;
BA_ "FlexKomSID" SG_ 907 VC_BU_TACHO_TYPE 2723;
BA_ "FlexKomIsMotorola" SG_ 907 VC_BU_TACHO_TYPE 1;
BA_ "FlexKomComment" SG_ 907 VC_BU_TACHO_TYPE "Backup Vehicle Configuration 8 Packet";
BA_ "GenSigSNA" SG_ 907 VC_BU_INDIA_SPEED_WARNING "0h";
BA_ "GenSigSendType" SG_ 907 VC_BU_INDIA_SPEED_WARNING 1;
BA_ "FlexKomSigStartValue" SG_ 907 VC_BU_INDIA_SPEED_WARNING "0300000000000000h";
BA_ "FlexKomSigStartPos" SG_ 907 VC_BU_INDIA_SPEED_WARNING 7;
BA_ "FlexKomSigName" SG_ 907 VC_BU_INDIA_SPEED_WARNING "VehCfgBU8_Pkt";
BA_ "FlexKomSigLaenge" SG_ 907 VC_BU_INDIA_SPEED_WARNING 64;
BA_ "FlexKomSID" SG_ 907 VC_BU_INDIA_SPEED_WARNING 2723;
BA_ "FlexKomIsMotorola" SG_ 907 VC_BU_INDIA_SPEED_WARNING 1;
BA_ "FlexKomComment" SG_ 907 VC_BU_INDIA_SPEED_WARNING "Backup Vehicle Configuration 8 Packet";
BA_ "RID" SG_ 908 GPS_Date_Year "2896";
BA_ "GenSigStartValue" SG_ 908 GPS_Date_Year 65535;
BA_ "GenSigSNA" SG_ 908 GPS_Date_Year "FFFFh";
BA_ "GenSigCycleTime" SG_ 908 GPS_Date_Year 1000;
BA_ "FlexKomSigStartValue" SG_ 908 GPS_Date_Year "FFFFFFFFFFFFFFFFh";
BA_ "FlexKomSigStartPos" SG_ 908 GPS_Date_Year 7;
BA_ "FlexKomSigName" SG_ 908 GPS_Date_Year "GPS_Date_UTC";
BA_ "FlexKomSigLaenge" SG_ 908 GPS_Date_Year 64;
BA_ "FlexKomSID" SG_ 908 GPS_Date_Year 566;
BA_ "FlexKomIsMotorola" SG_ 908 GPS_Date_Year 1;
BA_ "FlexKomComment" SG_ 908 GPS_Date_Year "GPS Date and UTC";
BA_ "RID" SG_ 908 GPS_Date_Month "2895";
BA_ "GenSigStartValue" SG_ 908 GPS_Date_Month 255;
BA_ "GenSigSNA" SG_ 908 GPS_Date_Month "FFh";
BA_ "GenSigCycleTime" SG_ 908 GPS_Date_Month 1000;
BA_ "FlexKomSigStartValue" SG_ 908 GPS_Date_Month "FFFFFFFFFFFFFFFFh";
BA_ "FlexKomSigStartPos" SG_ 908 GPS_Date_Month 7;
BA_ "FlexKomSigName" SG_ 908 GPS_Date_Month "GPS_Date_UTC";
BA_ "FlexKomSigLaenge" SG_ 908 GPS_Date_Month 64;
BA_ "FlexKomSID" SG_ 908 GPS_Date_Month 566;
BA_ "FlexKomIsMotorola" SG_ 908 GPS_Date_Month 1;
BA_ "FlexKomComment" SG_ 908 GPS_Date_Month "GPS Date and UTC";
BA_ "RID" SG_ 908 GPS_Date_Day "2897";
BA_ "GenSigStartValue" SG_ 908 GPS_Date_Day 255;
BA_ "GenSigSNA" SG_ 908 GPS_Date_Day "FFh";
BA_ "GenSigCycleTime" SG_ 908 GPS_Date_Day 1000;
BA_ "FlexKomSigStartValue" SG_ 908 GPS_Date_Day "FFFFFFFFFFFFFFFFh";
BA_ "FlexKomSigStartPos" SG_ 908 GPS_Date_Day 7;
BA_ "FlexKomSigName" SG_ 908 GPS_Date_Day "GPS_Date_UTC";
BA_ "FlexKomSigLaenge" SG_ 908 GPS_Date_Day 64;
BA_ "FlexKomSID" SG_ 908 GPS_Date_Day 566;
BA_ "FlexKomIsMotorola" SG_ 908 GPS_Date_Day 1;
BA_ "FlexKomComment" SG_ 908 GPS_Date_Day "GPS Date and UTC";
BA_ "RID" SG_ 908 GPS_UTC_Hour "2899";
BA_ "GenSigStartValue" SG_ 908 GPS_UTC_Hour 255;
BA_ "GenSigSNA" SG_ 908 GPS_UTC_Hour "FFh";
BA_ "GenSigCycleTime" SG_ 908 GPS_UTC_Hour 1000;
BA_ "FlexKomSigStartValue" SG_ 908 GPS_UTC_Hour "FFFFFFFFFFFFFFFFh";
BA_ "FlexKomSigStartPos" SG_ 908 GPS_UTC_Hour 7;
BA_ "FlexKomSigName" SG_ 908 GPS_UTC_Hour "GPS_Date_UTC";
BA_ "FlexKomSigLaenge" SG_ 908 GPS_UTC_Hour 64;
BA_ "FlexKomSID" SG_ 908 GPS_UTC_Hour 566;
BA_ "FlexKomIsMotorola" SG_ 908 GPS_UTC_Hour 1;
BA_ "FlexKomComment" SG_ 908 GPS_UTC_Hour "GPS Date and UTC";
BA_ "RID" SG_ 908 GPS_UTC_Minute "2902";
BA_ "GenSigStartValue" SG_ 908 GPS_UTC_Minute 255;
BA_ "GenSigSNA" SG_ 908 GPS_UTC_Minute "FFh";
BA_ "GenSigCycleTime" SG_ 908 GPS_UTC_Minute 1000;
BA_ "FlexKomSigStartValue" SG_ 908 GPS_UTC_Minute "FFFFFFFFFFFFFFFFh";
BA_ "FlexKomSigStartPos" SG_ 908 GPS_UTC_Minute 7;
BA_ "FlexKomSigName" SG_ 908 GPS_UTC_Minute "GPS_Date_UTC";
BA_ "FlexKomSigLaenge" SG_ 908 GPS_UTC_Minute 64;
BA_ "FlexKomSID" SG_ 908 GPS_UTC_Minute 566;
BA_ "FlexKomIsMotorola" SG_ 908 GPS_UTC_Minute 1;
BA_ "FlexKomComment" SG_ 908 GPS_UTC_Minute "GPS Date and UTC";
BA_ "RID" SG_ 908 GPS_UTC_Second "2898";
BA_ "GenSigStartValue" SG_ 908 GPS_UTC_Second 65535;
BA_ "GenSigSNA" SG_ 908 GPS_UTC_Second "FFFFh";
BA_ "GenSigCycleTime" SG_ 908 GPS_UTC_Second 1000;
BA_ "FlexKomSigStartValue" SG_ 908 GPS_UTC_Second "FFFFFFFFFFFFFFFFh";
BA_ "FlexKomSigStartPos" SG_ 908 GPS_UTC_Second 7;
BA_ "FlexKomSigName" SG_ 908 GPS_UTC_Second "GPS_Date_UTC";
BA_ "FlexKomSigLaenge" SG_ 908 GPS_UTC_Second 64;
BA_ "FlexKomSID" SG_ 908 GPS_UTC_Second 566;
BA_ "FlexKomIsMotorola" SG_ 908 GPS_UTC_Second 1;
BA_ "FlexKomComment" SG_ 908 GPS_UTC_Second "GPS Date and UTC";
BA_ "RID" SG_ 910 IBS3_TempFailStatus "5082";
BA_ "GenSigSNA" SG_ 910 IBS3_TempFailStatus "0h";
BA_ "GenSigCycleTime" SG_ 910 IBS3_TempFailStatus 2000;
BA_ "FlexKomSigStartValue" SG_ 910 IBS3_TempFailStatus "00FFFF7F7F80h";
BA_ "FlexKomSigStartPos" SG_ 910 IBS3_TempFailStatus 23;
BA_ "FlexKomSigName" SG_ 910 IBS3_TempFailStatus "GW_LIN_I_C6_Pkt2";
BA_ "FlexKomSigLaenge" SG_ 910 IBS3_TempFailStatus 48;
BA_ "FlexKomSID" SG_ 910 IBS3_TempFailStatus 2657;
BA_ "FlexKomIsMotorola" SG_ 910 IBS3_TempFailStatus 1;
BA_ "FlexKomComment" SG_ 910 IBS3_TempFailStatus "Cyclic only";
BA_ "RID" SG_ 910 IBS3_SOF_Q_Accuracy "5133";
BA_ "GenSigSNA" SG_ 910 IBS3_SOF_Q_Accuracy "0h";
BA_ "GenSigCycleTime" SG_ 910 IBS3_SOF_Q_Accuracy 2000;
BA_ "FlexKomSigStartValue" SG_ 910 IBS3_SOF_Q_Accuracy "00FFFF7F7F80h";
BA_ "FlexKomSigStartPos" SG_ 910 IBS3_SOF_Q_Accuracy 23;
BA_ "FlexKomSigName" SG_ 910 IBS3_SOF_Q_Accuracy "GW_LIN_I_C6_Pkt2";
BA_ "FlexKomSigLaenge" SG_ 910 IBS3_SOF_Q_Accuracy 48;
BA_ "FlexKomSID" SG_ 910 IBS3_SOF_Q_Accuracy 2657;
BA_ "FlexKomIsMotorola" SG_ 910 IBS3_SOF_Q_Accuracy 1;
BA_ "FlexKomComment" SG_ 910 IBS3_SOF_Q_Accuracy "Cyclic only";
BA_ "RID" SG_ 910 IBS3_FLAG_DISCONNECT "5131";
BA_ "GenSigSNA" SG_ 910 IBS3_FLAG_DISCONNECT "0h";
BA_ "GenSigCycleTime" SG_ 910 IBS3_FLAG_DISCONNECT 2000;
BA_ "FlexKomSigStartValue" SG_ 910 IBS3_FLAG_DISCONNECT "00FFFF7F7F80h";
BA_ "FlexKomSigStartPos" SG_ 910 IBS3_FLAG_DISCONNECT 23;
BA_ "FlexKomSigName" SG_ 910 IBS3_FLAG_DISCONNECT "GW_LIN_I_C6_Pkt2";
BA_ "FlexKomSigLaenge" SG_ 910 IBS3_FLAG_DISCONNECT 48;
BA_ "FlexKomSID" SG_ 910 IBS3_FLAG_DISCONNECT 2657;
BA_ "FlexKomIsMotorola" SG_ 910 IBS3_FLAG_DISCONNECT 1;
BA_ "FlexKomComment" SG_ 910 IBS3_FLAG_DISCONNECT "Cyclic only";
BA_ "RID" SG_ 910 IBS3_SOF_Q "5145";
BA_ "GenSigStartValue" SG_ 910 IBS3_SOF_Q 255;
BA_ "GenSigSNA" SG_ 910 IBS3_SOF_Q "FFh";
BA_ "GenSigCycleTime" SG_ 910 IBS3_SOF_Q 2000;
BA_ "FlexKomSigStartValue" SG_ 910 IBS3_SOF_Q "00FFFF7F7F80h";
BA_ "FlexKomSigStartPos" SG_ 910 IBS3_SOF_Q 23;
BA_ "FlexKomSigName" SG_ 910 IBS3_SOF_Q "GW_LIN_I_C6_Pkt2";
BA_ "FlexKomSigLaenge" SG_ 910 IBS3_SOF_Q 48;
BA_ "FlexKomSID" SG_ 910 IBS3_SOF_Q 2657;
BA_ "FlexKomIsMotorola" SG_ 910 IBS3_SOF_Q 1;
BA_ "FlexKomComment" SG_ 910 IBS3_SOF_Q "Cyclic only";
BA_ "RID" SG_ 910 IBS3_T_BATT "5105";
BA_ "GenSigStartValue" SG_ 910 IBS3_T_BATT 255;
BA_ "GenSigSNA" SG_ 910 IBS3_T_BATT "FFh";
BA_ "GenSigCycleTime" SG_ 910 IBS3_T_BATT 2000;
BA_ "FlexKomSigStartValue" SG_ 910 IBS3_T_BATT "00FFFF7F7F80h";
BA_ "FlexKomSigStartPos" SG_ 910 IBS3_T_BATT 23;
BA_ "FlexKomSigName" SG_ 910 IBS3_T_BATT "GW_LIN_I_C6_Pkt2";
BA_ "FlexKomSigLaenge" SG_ 910 IBS3_T_BATT 48;
BA_ "FlexKomSID" SG_ 910 IBS3_T_BATT 2657;
BA_ "FlexKomIsMotorola" SG_ 910 IBS3_T_BATT 1;
BA_ "FlexKomComment" SG_ 910 IBS3_T_BATT "Cyclic only";
BA_ "RID" SG_ 910 IBS3_SOH_Q "5148";
BA_ "GenSigStartValue" SG_ 910 IBS3_SOH_Q 127;
BA_ "GenSigSNA" SG_ 910 IBS3_SOH_Q "7Fh";
BA_ "GenSigCycleTime" SG_ 910 IBS3_SOH_Q 2000;
BA_ "FlexKomSigStartValue" SG_ 910 IBS3_SOH_Q "00FFFF7F7F80h";
BA_ "FlexKomSigStartPos" SG_ 910 IBS3_SOH_Q 23;
BA_ "FlexKomSigName" SG_ 910 IBS3_SOH_Q "GW_LIN_I_C6_Pkt2";
BA_ "FlexKomSigLaenge" SG_ 910 IBS3_SOH_Q 48;
BA_ "FlexKomSID" SG_ 910 IBS3_SOH_Q 2657;
BA_ "FlexKomIsMotorola" SG_ 910 IBS3_SOH_Q 1;
BA_ "FlexKomComment" SG_ 910 IBS3_SOH_Q "Cyclic only";
BA_ "RID" SG_ 910 IBS3_SOH_Q_Accuracy "5086";
BA_ "GenSigSNA" SG_ 910 IBS3_SOH_Q_Accuracy "0h";
BA_ "GenSigCycleTime" SG_ 910 IBS3_SOH_Q_Accuracy 2000;
BA_ "FlexKomSigStartValue" SG_ 910 IBS3_SOH_Q_Accuracy "00FFFF7F7F80h";
BA_ "FlexKomSigStartPos" SG_ 910 IBS3_SOH_Q_Accuracy 23;
BA_ "FlexKomSigName" SG_ 910 IBS3_SOH_Q_Accuracy "GW_LIN_I_C6_Pkt2";
BA_ "FlexKomSigLaenge" SG_ 910 IBS3_SOH_Q_Accuracy 48;
BA_ "FlexKomSID" SG_ 910 IBS3_SOH_Q_Accuracy 2657;
BA_ "FlexKomIsMotorola" SG_ 910 IBS3_SOH_Q_Accuracy 1;
BA_ "FlexKomComment" SG_ 910 IBS3_SOH_Q_Accuracy "Cyclic only";
BA_ "RID" SG_ 910 IBS3_SOC "5121";
BA_ "GenSigStartValue" SG_ 910 IBS3_SOC 127;
BA_ "GenSigSNA" SG_ 910 IBS3_SOC "7Fh";
BA_ "GenSigCycleTime" SG_ 910 IBS3_SOC 2000;
BA_ "FlexKomSigStartValue" SG_ 910 IBS3_SOC "00FFFF7F7F80h";
BA_ "FlexKomSigStartPos" SG_ 910 IBS3_SOC 23;
BA_ "FlexKomSigName" SG_ 910 IBS3_SOC "GW_LIN_I_C6_Pkt2";
BA_ "FlexKomSigLaenge" SG_ 910 IBS3_SOC 48;
BA_ "FlexKomSID" SG_ 910 IBS3_SOC 2657;
BA_ "FlexKomIsMotorola" SG_ 910 IBS3_SOC 1;
BA_ "FlexKomComment" SG_ 910 IBS3_SOC "Cyclic only";
BA_ "RID" SG_ 910 IBS3_SOC_Accuracy "5104";
BA_ "GenSigSNA" SG_ 910 IBS3_SOC_Accuracy "0h";
BA_ "GenSigCycleTime" SG_ 910 IBS3_SOC_Accuracy 2000;
BA_ "FlexKomSigStartValue" SG_ 910 IBS3_SOC_Accuracy "00FFFF7F7F80h";
BA_ "FlexKomSigStartPos" SG_ 910 IBS3_SOC_Accuracy 23;
BA_ "FlexKomSigName" SG_ 910 IBS3_SOC_Accuracy "GW_LIN_I_C6_Pkt2";
BA_ "FlexKomSigLaenge" SG_ 910 IBS3_SOC_Accuracy 48;
BA_ "FlexKomSID" SG_ 910 IBS3_SOC_Accuracy 2657;
BA_ "FlexKomIsMotorola" SG_ 910 IBS3_SOC_Accuracy 1;
BA_ "FlexKomComment" SG_ 910 IBS3_SOC_Accuracy "Cyclic only";
BA_ "RID" SG_ 910 IBS3_SOF_VC "5115";
BA_ "GenSigSNA" SG_ 910 IBS3_SOF_VC "7Fh";
BA_ "GenSigCycleTime" SG_ 910 IBS3_SOF_VC 2000;
BA_ "FlexKomSigStartValue" SG_ 910 IBS3_SOF_VC "00FFFF7F7F80h";
BA_ "FlexKomSigStartPos" SG_ 910 IBS3_SOF_VC 23;
BA_ "FlexKomSigName" SG_ 910 IBS3_SOF_VC "GW_LIN_I_C6_Pkt2";
BA_ "FlexKomSigLaenge" SG_ 910 IBS3_SOF_VC 48;
BA_ "FlexKomSID" SG_ 910 IBS3_SOF_VC 2657;
BA_ "FlexKomIsMotorola" SG_ 910 IBS3_SOF_VC 1;
BA_ "FlexKomComment" SG_ 910 IBS3_SOF_VC "Cyclic only";
BA_ "RID" SG_ 910 IBS3_SOF_V_Accuracy "5129";
BA_ "GenSigStartValue" SG_ 910 IBS3_SOF_V_Accuracy 1;
BA_ "GenSigSNA" SG_ 910 IBS3_SOF_V_Accuracy "1h";
BA_ "GenSigCycleTime" SG_ 910 IBS3_SOF_V_Accuracy 2000;
BA_ "FlexKomSigStartValue" SG_ 910 IBS3_SOF_V_Accuracy "00FFFF7F7F80h";
BA_ "FlexKomSigStartPos" SG_ 910 IBS3_SOF_V_Accuracy 23;
BA_ "FlexKomSigName" SG_ 910 IBS3_SOF_V_Accuracy "GW_LIN_I_C6_Pkt2";
BA_ "FlexKomSigLaenge" SG_ 910 IBS3_SOF_V_Accuracy 48;
BA_ "FlexKomSID" SG_ 910 IBS3_SOF_V_Accuracy 2657;
BA_ "FlexKomIsMotorola" SG_ 910 IBS3_SOF_V_Accuracy 1;
BA_ "FlexKomComment" SG_ 910 IBS3_SOF_V_Accuracy "Cyclic only";
BA_ "GenSigSNA" SG_ 912 ECM_APPL5 "0h";
BA_ "GenSigSendType" SG_ 912 ECM_APPL5 1;
BA_ "FlexKomSigStartValue" SG_ 912 ECM_APPL5 "0000000000000000h";
BA_ "FlexKomSigStartPos" SG_ 912 ECM_APPL5 7;
BA_ "FlexKomSigName" SG_ 912 ECM_APPL5 "ECM_APPL5";
BA_ "FlexKomSigLaenge" SG_ 912 ECM_APPL5 64;
BA_ "FlexKomSID" SG_ 912 ECM_APPL5 783;
BA_ "FlexKomIsMotorola" SG_ 912 ECM_APPL5 1;
BA_ "FlexKomComment" SG_ 912 ECM_APPL5 "CCP 10ms DAQ  (from ENGINE to external tool)";
BA_ "RID" SG_ 913 CountryCode "6347";
BA_ "GenSigSNA" SG_ 913 CountryCode "0h";
BA_ "GenSigCycleTime" SG_ 913 CountryCode 5000;
BA_ "FlexKomSigStartValue" SG_ 913 CountryCode "00000000h";
BA_ "FlexKomSigStartPos" SG_ 913 CountryCode 7;
BA_ "FlexKomSigName" SG_ 913 CountryCode "META_DATA_pkt";
BA_ "FlexKomSigLaenge" SG_ 913 CountryCode 32;
BA_ "FlexKomSID" SG_ 913 CountryCode 2698;
BA_ "FlexKomIsMotorola" SG_ 913 CountryCode 1;
BA_ "FlexKomComment" SG_ 913 CountryCode "META_DATA packet";
BA_ "RID" SG_ 913 DrvSide "6354";
BA_ "GenSigSNA" SG_ 913 DrvSide "0h";
BA_ "GenSigCycleTime" SG_ 913 DrvSide 5000;
BA_ "FlexKomSigStartValue" SG_ 913 DrvSide "00000000h";
BA_ "FlexKomSigStartPos" SG_ 913 DrvSide 7;
BA_ "FlexKomSigName" SG_ 913 DrvSide "META_DATA_pkt";
BA_ "FlexKomSigLaenge" SG_ 913 DrvSide 32;
BA_ "FlexKomSID" SG_ 913 DrvSide 2698;
BA_ "FlexKomIsMotorola" SG_ 913 DrvSide 1;
BA_ "FlexKomComment" SG_ 913 DrvSide "META_DATA packet";
BA_ "RID" SG_ 913 SpdUnits "6343";
BA_ "GenSigSNA" SG_ 913 SpdUnits "0h";
BA_ "GenSigCycleTime" SG_ 913 SpdUnits 5000;
BA_ "FlexKomSigStartValue" SG_ 913 SpdUnits "00000000h";
BA_ "FlexKomSigStartPos" SG_ 913 SpdUnits 7;
BA_ "FlexKomSigName" SG_ 913 SpdUnits "META_DATA_pkt";
BA_ "FlexKomSigLaenge" SG_ 913 SpdUnits 32;
BA_ "FlexKomSID" SG_ 913 SpdUnits 2698;
BA_ "FlexKomIsMotorola" SG_ 913 SpdUnits 1;
BA_ "FlexKomComment" SG_ 913 SpdUnits "META_DATA packet";
BA_ "GenSigSNA" SG_ 920 TCM_HSD "0h";
BA_ "GenSigSendType" SG_ 920 TCM_HSD 1;
BA_ "FlexKomSigStartValue" SG_ 920 TCM_HSD "0000000000000000h";
BA_ "FlexKomSigStartPos" SG_ 920 TCM_HSD 7;
BA_ "FlexKomSigName" SG_ 920 TCM_HSD "TCM_HSD";
BA_ "FlexKomSigLaenge" SG_ 920 TCM_HSD 64;
BA_ "FlexKomSID" SG_ 920 TCM_HSD 802;
BA_ "FlexKomIsMotorola" SG_ 920 TCM_HSD 1;
BA_ "FlexKomComment" SG_ 920 TCM_HSD "Manual control at test bench";
BA_ "GenSigSNA" SG_ 926 NetCfg_IDCM_ePT "0h";
BA_ "GenSigSendType" SG_ 926 NetCfg_IDCM_ePT 5;
BA_ "GenSigCycleTime" SG_ 926 NetCfg_IDCM_ePT 2000;
BA_ "FlexKomSigStartValue" SG_ 926 NetCfg_IDCM_ePT "030000h";
BA_ "FlexKomSigStartPos" SG_ 926 NetCfg_IDCM_ePT 7;
BA_ "FlexKomSigName" SG_ 926 NetCfg_IDCM_ePT "NET_CFG_DATA_ePT";
BA_ "FlexKomSigLaenge" SG_ 926 NetCfg_IDCM_ePT 24;
BA_ "FlexKomSID" SG_ 926 NetCfg_IDCM_ePT 2469;
BA_ "FlexKomIsMotorola" SG_ 926 NetCfg_IDCM_ePT 1;
BA_ "FlexKomComment" SG_ 926 NetCfg_IDCM_ePT "Network ECU config data for hybrid bus";
BA_ "GenSigSNA" SG_ 926 NetCfg_MCPA_ePT "0h";
BA_ "GenSigSendType" SG_ 926 NetCfg_MCPA_ePT 5;
BA_ "GenSigCycleTime" SG_ 926 NetCfg_MCPA_ePT 2000;
BA_ "FlexKomSigStartValue" SG_ 926 NetCfg_MCPA_ePT "030000h";
BA_ "FlexKomSigStartPos" SG_ 926 NetCfg_MCPA_ePT 7;
BA_ "FlexKomSigName" SG_ 926 NetCfg_MCPA_ePT "NET_CFG_DATA_ePT";
BA_ "FlexKomSigLaenge" SG_ 926 NetCfg_MCPA_ePT 24;
BA_ "FlexKomSID" SG_ 926 NetCfg_MCPA_ePT 2469;
BA_ "FlexKomIsMotorola" SG_ 926 NetCfg_MCPA_ePT 1;
BA_ "FlexKomComment" SG_ 926 NetCfg_MCPA_ePT "Network ECU config data for hybrid bus";
BA_ "GenSigTimeout_RF_HUB" SG_ 926 NET_CFG_STAT_ePT 21000;
BA_ "GenSigStartValue" SG_ 926 NET_CFG_STAT_ePT 3;
BA_ "GenSigSNA" SG_ 926 NET_CFG_STAT_ePT "3h";
BA_ "GenSigSendType" SG_ 926 NET_CFG_STAT_ePT 5;
BA_ "GenSigCycleTime" SG_ 926 NET_CFG_STAT_ePT 2000;
BA_ "FlexKomSigStartValue" SG_ 926 NET_CFG_STAT_ePT "030000h";
BA_ "FlexKomSigStartPos" SG_ 926 NET_CFG_STAT_ePT 7;
BA_ "FlexKomSigName" SG_ 926 NET_CFG_STAT_ePT "NET_CFG_DATA_ePT";
BA_ "FlexKomSigLaenge" SG_ 926 NET_CFG_STAT_ePT 24;
BA_ "FlexKomSID" SG_ 926 NET_CFG_STAT_ePT 2469;
BA_ "FlexKomIsMotorola" SG_ 926 NET_CFG_STAT_ePT 1;
BA_ "FlexKomComment" SG_ 926 NET_CFG_STAT_ePT "Network ECU config data for hybrid bus";
BA_ "GenSigTimeout_RF_HUB" SG_ 926 NetCfg_EBCM_ePT 21000;
BA_ "GenSigSNA" SG_ 926 NetCfg_EBCM_ePT "0h";
BA_ "GenSigSendType" SG_ 926 NetCfg_EBCM_ePT 5;
BA_ "GenSigCycleTime" SG_ 926 NetCfg_EBCM_ePT 2000;
BA_ "FlexKomSigStartValue" SG_ 926 NetCfg_EBCM_ePT "030000h";
BA_ "FlexKomSigStartPos" SG_ 926 NetCfg_EBCM_ePT 7;
BA_ "FlexKomSigName" SG_ 926 NetCfg_EBCM_ePT "NET_CFG_DATA_ePT";
BA_ "FlexKomSigLaenge" SG_ 926 NetCfg_EBCM_ePT 24;
BA_ "FlexKomSID" SG_ 926 NetCfg_EBCM_ePT 2469;
BA_ "FlexKomIsMotorola" SG_ 926 NetCfg_EBCM_ePT 1;
BA_ "FlexKomComment" SG_ 926 NetCfg_EBCM_ePT "Network ECU config data for hybrid bus";
BA_ "GenSigTimeout_RF_HUB" SG_ 926 NetCfg_ORC_ePT 21000;
BA_ "GenSigSNA" SG_ 926 NetCfg_ORC_ePT "0h";
BA_ "GenSigSendType" SG_ 926 NetCfg_ORC_ePT 5;
BA_ "GenSigCycleTime" SG_ 926 NetCfg_ORC_ePT 2000;
BA_ "FlexKomSigStartValue" SG_ 926 NetCfg_ORC_ePT "030000h";
BA_ "FlexKomSigStartPos" SG_ 926 NetCfg_ORC_ePT 7;
BA_ "FlexKomSigName" SG_ 926 NetCfg_ORC_ePT "NET_CFG_DATA_ePT";
BA_ "FlexKomSigLaenge" SG_ 926 NetCfg_ORC_ePT 24;
BA_ "FlexKomSID" SG_ 926 NetCfg_ORC_ePT 2469;
BA_ "FlexKomIsMotorola" SG_ 926 NetCfg_ORC_ePT 1;
BA_ "FlexKomComment" SG_ 926 NetCfg_ORC_ePT "Network ECU config data for hybrid bus";
BA_ "GenSigTimeout_RF_HUB" SG_ 926 NetCfg_ESM_ePT 21000;
BA_ "GenSigSNA" SG_ 926 NetCfg_ESM_ePT "0h";
BA_ "GenSigSendType" SG_ 926 NetCfg_ESM_ePT 5;
BA_ "GenSigCycleTime" SG_ 926 NetCfg_ESM_ePT 2000;
BA_ "FlexKomSigStartValue" SG_ 926 NetCfg_ESM_ePT "030000h";
BA_ "FlexKomSigStartPos" SG_ 926 NetCfg_ESM_ePT 7;
BA_ "FlexKomSigName" SG_ 926 NetCfg_ESM_ePT "NET_CFG_DATA_ePT";
BA_ "FlexKomSigLaenge" SG_ 926 NetCfg_ESM_ePT 24;
BA_ "FlexKomSID" SG_ 926 NetCfg_ESM_ePT 2469;
BA_ "FlexKomIsMotorola" SG_ 926 NetCfg_ESM_ePT 1;
BA_ "FlexKomComment" SG_ 926 NetCfg_ESM_ePT "Network ECU config data for hybrid bus";
BA_ "GenSigTimeout_RF_HUB" SG_ 926 NetCfg_ESC_ePT 21000;
BA_ "GenSigSNA" SG_ 926 NetCfg_ESC_ePT "0h";
BA_ "GenSigSendType" SG_ 926 NetCfg_ESC_ePT 5;
BA_ "GenSigCycleTime" SG_ 926 NetCfg_ESC_ePT 2000;
BA_ "FlexKomSigStartValue" SG_ 926 NetCfg_ESC_ePT "030000h";
BA_ "FlexKomSigStartPos" SG_ 926 NetCfg_ESC_ePT 7;
BA_ "FlexKomSigName" SG_ 926 NetCfg_ESC_ePT "NET_CFG_DATA_ePT";
BA_ "FlexKomSigLaenge" SG_ 926 NetCfg_ESC_ePT 24;
BA_ "FlexKomSID" SG_ 926 NetCfg_ESC_ePT 2469;
BA_ "FlexKomIsMotorola" SG_ 926 NetCfg_ESC_ePT 1;
BA_ "FlexKomComment" SG_ 926 NetCfg_ESC_ePT "Network ECU config data for hybrid bus";
BA_ "GenSigTimeout_RF_HUB" SG_ 926 NetCfg_ECM_ePT 21000;
BA_ "GenSigSNA" SG_ 926 NetCfg_ECM_ePT "0h";
BA_ "GenSigSendType" SG_ 926 NetCfg_ECM_ePT 5;
BA_ "GenSigCycleTime" SG_ 926 NetCfg_ECM_ePT 2000;
BA_ "FlexKomSigStartValue" SG_ 926 NetCfg_ECM_ePT "030000h";
BA_ "FlexKomSigStartPos" SG_ 926 NetCfg_ECM_ePT 7;
BA_ "FlexKomSigName" SG_ 926 NetCfg_ECM_ePT "NET_CFG_DATA_ePT";
BA_ "FlexKomSigLaenge" SG_ 926 NetCfg_ECM_ePT 24;
BA_ "FlexKomSID" SG_ 926 NetCfg_ECM_ePT 2469;
BA_ "FlexKomIsMotorola" SG_ 926 NetCfg_ECM_ePT 1;
BA_ "FlexKomComment" SG_ 926 NetCfg_ECM_ePT "Network ECU config data for hybrid bus";
BA_ "GenSigTimeout_RF_HUB" SG_ 926 NetCfg_HCP_ePT 21000;
BA_ "GenSigSNA" SG_ 926 NetCfg_HCP_ePT "0h";
BA_ "GenSigSendType" SG_ 926 NetCfg_HCP_ePT 5;
BA_ "GenSigCycleTime" SG_ 926 NetCfg_HCP_ePT 2000;
BA_ "FlexKomSigStartValue" SG_ 926 NetCfg_HCP_ePT "030000h";
BA_ "FlexKomSigStartPos" SG_ 926 NetCfg_HCP_ePT 7;
BA_ "FlexKomSigName" SG_ 926 NetCfg_HCP_ePT "NET_CFG_DATA_ePT";
BA_ "FlexKomSigLaenge" SG_ 926 NetCfg_HCP_ePT 24;
BA_ "FlexKomSID" SG_ 926 NetCfg_HCP_ePT 2469;
BA_ "FlexKomIsMotorola" SG_ 926 NetCfg_HCP_ePT 1;
BA_ "FlexKomComment" SG_ 926 NetCfg_HCP_ePT "Network ECU config data for hybrid bus";
BA_ "GenSigTimeout_RF_HUB" SG_ 926 NetCfg_OBCM_ePT 21000;
BA_ "GenSigSNA" SG_ 926 NetCfg_OBCM_ePT "0h";
BA_ "GenSigSendType" SG_ 926 NetCfg_OBCM_ePT 5;
BA_ "GenSigCycleTime" SG_ 926 NetCfg_OBCM_ePT 2000;
BA_ "FlexKomSigStartValue" SG_ 926 NetCfg_OBCM_ePT "030000h";
BA_ "FlexKomSigStartPos" SG_ 926 NetCfg_OBCM_ePT 7;
BA_ "FlexKomSigName" SG_ 926 NetCfg_OBCM_ePT "NET_CFG_DATA_ePT";
BA_ "FlexKomSigLaenge" SG_ 926 NetCfg_OBCM_ePT 24;
BA_ "FlexKomSID" SG_ 926 NetCfg_OBCM_ePT 2469;
BA_ "FlexKomIsMotorola" SG_ 926 NetCfg_OBCM_ePT 1;
BA_ "FlexKomComment" SG_ 926 NetCfg_OBCM_ePT "Network ECU config data for hybrid bus";
BA_ "GenSigTimeout_RF_HUB" SG_ 926 NetCfg_AHCP_ePT 21000;
BA_ "GenSigSNA" SG_ 926 NetCfg_AHCP_ePT "0h";
BA_ "GenSigSendType" SG_ 926 NetCfg_AHCP_ePT 5;
BA_ "GenSigCycleTime" SG_ 926 NetCfg_AHCP_ePT 2000;
BA_ "FlexKomSigStartValue" SG_ 926 NetCfg_AHCP_ePT "030000h";
BA_ "FlexKomSigStartPos" SG_ 926 NetCfg_AHCP_ePT 7;
BA_ "FlexKomSigName" SG_ 926 NetCfg_AHCP_ePT "NET_CFG_DATA_ePT";
BA_ "FlexKomSigLaenge" SG_ 926 NetCfg_AHCP_ePT 24;
BA_ "FlexKomSID" SG_ 926 NetCfg_AHCP_ePT 2469;
BA_ "FlexKomIsMotorola" SG_ 926 NetCfg_AHCP_ePT 1;
BA_ "FlexKomComment" SG_ 926 NetCfg_AHCP_ePT "Network ECU config data for hybrid bus";
BA_ "GenSigTimeout_RF_HUB" SG_ 926 NetCfg_SCA_ePT 21000;
BA_ "GenSigSNA" SG_ 926 NetCfg_SCA_ePT "0h";
BA_ "GenSigSendType" SG_ 926 NetCfg_SCA_ePT 5;
BA_ "GenSigCycleTime" SG_ 926 NetCfg_SCA_ePT 2000;
BA_ "FlexKomSigStartValue" SG_ 926 NetCfg_SCA_ePT "030000h";
BA_ "FlexKomSigStartPos" SG_ 926 NetCfg_SCA_ePT 7;
BA_ "FlexKomSigName" SG_ 926 NetCfg_SCA_ePT "NET_CFG_DATA_ePT";
BA_ "FlexKomSigLaenge" SG_ 926 NetCfg_SCA_ePT 24;
BA_ "FlexKomSID" SG_ 926 NetCfg_SCA_ePT 2469;
BA_ "FlexKomIsMotorola" SG_ 926 NetCfg_SCA_ePT 1;
BA_ "FlexKomComment" SG_ 926 NetCfg_SCA_ePT "Network ECU config data for hybrid bus";
BA_ "GenSigTimeout_RF_HUB" SG_ 926 NetCfg_EAC_ePT 21000;
BA_ "GenSigSNA" SG_ 926 NetCfg_EAC_ePT "0h";
BA_ "GenSigSendType" SG_ 926 NetCfg_EAC_ePT 5;
BA_ "GenSigCycleTime" SG_ 926 NetCfg_EAC_ePT 2000;
BA_ "FlexKomSigStartValue" SG_ 926 NetCfg_EAC_ePT "030000h";
BA_ "FlexKomSigStartPos" SG_ 926 NetCfg_EAC_ePT 7;
BA_ "FlexKomSigName" SG_ 926 NetCfg_EAC_ePT "NET_CFG_DATA_ePT";
BA_ "FlexKomSigLaenge" SG_ 926 NetCfg_EAC_ePT 24;
BA_ "FlexKomSID" SG_ 926 NetCfg_EAC_ePT 2469;
BA_ "FlexKomIsMotorola" SG_ 926 NetCfg_EAC_ePT 1;
BA_ "FlexKomComment" SG_ 926 NetCfg_EAC_ePT "Network ECU config data for hybrid bus";
BA_ "GenSigTimeout_RF_HUB" SG_ 926 NetCfg_BPCM_ePT 21000;
BA_ "GenSigSNA" SG_ 926 NetCfg_BPCM_ePT "0h";
BA_ "GenSigSendType" SG_ 926 NetCfg_BPCM_ePT 5;
BA_ "GenSigCycleTime" SG_ 926 NetCfg_BPCM_ePT 2000;
BA_ "FlexKomSigStartValue" SG_ 926 NetCfg_BPCM_ePT "030000h";
BA_ "FlexKomSigStartPos" SG_ 926 NetCfg_BPCM_ePT 7;
BA_ "FlexKomSigName" SG_ 926 NetCfg_BPCM_ePT "NET_CFG_DATA_ePT";
BA_ "FlexKomSigLaenge" SG_ 926 NetCfg_BPCM_ePT 24;
BA_ "FlexKomSID" SG_ 926 NetCfg_BPCM_ePT 2469;
BA_ "FlexKomIsMotorola" SG_ 926 NetCfg_BPCM_ePT 1;
BA_ "FlexKomComment" SG_ 926 NetCfg_BPCM_ePT "Network ECU config data for hybrid bus";
BA_ "GenSigTimeout_RF_HUB" SG_ 926 NetCfg_APM_ePT 21000;
BA_ "GenSigSNA" SG_ 926 NetCfg_APM_ePT "0h";
BA_ "GenSigSendType" SG_ 926 NetCfg_APM_ePT 5;
BA_ "GenSigCycleTime" SG_ 926 NetCfg_APM_ePT 2000;
BA_ "FlexKomSigStartValue" SG_ 926 NetCfg_APM_ePT "030000h";
BA_ "FlexKomSigStartPos" SG_ 926 NetCfg_APM_ePT 7;
BA_ "FlexKomSigName" SG_ 926 NetCfg_APM_ePT "NET_CFG_DATA_ePT";
BA_ "FlexKomSigLaenge" SG_ 926 NetCfg_APM_ePT 24;
BA_ "FlexKomSID" SG_ 926 NetCfg_APM_ePT 2469;
BA_ "FlexKomIsMotorola" SG_ 926 NetCfg_APM_ePT 1;
BA_ "FlexKomComment" SG_ 926 NetCfg_APM_ePT "Network ECU config data for hybrid bus";
BA_ "GenSigSNA" SG_ 926 NetCfg_BSMO_ePT "0h";
BA_ "GenSigSendType" SG_ 926 NetCfg_BSMO_ePT 5;
BA_ "GenSigCycleTime" SG_ 926 NetCfg_BSMO_ePT 2000;
BA_ "FlexKomSigStartValue" SG_ 926 NetCfg_BSMO_ePT "030000h";
BA_ "FlexKomSigStartPos" SG_ 926 NetCfg_BSMO_ePT 7;
BA_ "FlexKomSigName" SG_ 926 NetCfg_BSMO_ePT "NET_CFG_DATA_ePT";
BA_ "FlexKomSigLaenge" SG_ 926 NetCfg_BSMO_ePT 24;
BA_ "FlexKomSID" SG_ 926 NetCfg_BSMO_ePT 2469;
BA_ "FlexKomIsMotorola" SG_ 926 NetCfg_BSMO_ePT 1;
BA_ "FlexKomComment" SG_ 926 NetCfg_BSMO_ePT "Network ECU config data for hybrid bus";
BA_ "GenSigSNA" SG_ 926 NetCfg_EVCU2_ePT "0h";
BA_ "GenSigSendType" SG_ 926 NetCfg_EVCU2_ePT 5;
BA_ "GenSigCycleTime" SG_ 926 NetCfg_EVCU2_ePT 2000;
BA_ "FlexKomSigStartValue" SG_ 926 NetCfg_EVCU2_ePT "030000h";
BA_ "FlexKomSigStartPos" SG_ 926 NetCfg_EVCU2_ePT 7;
BA_ "FlexKomSigName" SG_ 926 NetCfg_EVCU2_ePT "NET_CFG_DATA_ePT";
BA_ "FlexKomSigLaenge" SG_ 926 NetCfg_EVCU2_ePT 24;
BA_ "FlexKomSID" SG_ 926 NetCfg_EVCU2_ePT 2469;
BA_ "FlexKomIsMotorola" SG_ 926 NetCfg_EVCU2_ePT 1;
BA_ "FlexKomComment" SG_ 926 NetCfg_EVCU2_ePT "Network ECU config data for hybrid bus";
BA_ "GenSigStartValue" SG_ 927 BU_NET_CFG_STAT_ePT 3;
BA_ "GenSigSNA" SG_ 927 BU_NET_CFG_STAT_ePT "3h";
BA_ "GenSigSendType" SG_ 927 BU_NET_CFG_STAT_ePT 1;
BA_ "FlexKomSigStartValue" SG_ 927 BU_NET_CFG_STAT_ePT "030000h";
BA_ "FlexKomSigStartPos" SG_ 927 BU_NET_CFG_STAT_ePT 7;
BA_ "FlexKomSigName" SG_ 927 BU_NET_CFG_STAT_ePT "BU_NET_CFG_DATA_ePT";
BA_ "FlexKomSigLaenge" SG_ 927 BU_NET_CFG_STAT_ePT 24;
BA_ "FlexKomSID" SG_ 927 BU_NET_CFG_STAT_ePT 2470;
BA_ "FlexKomIsMotorola" SG_ 927 BU_NET_CFG_STAT_ePT 1;
BA_ "FlexKomComment" SG_ 927 BU_NET_CFG_STAT_ePT "Backup for network ECU config data for hybrid netw";
BA_ "GenSigSNA" SG_ 927 BU_NetCfg_EBCM_ePT "0h";
BA_ "GenSigSendType" SG_ 927 BU_NetCfg_EBCM_ePT 1;
BA_ "FlexKomSigStartValue" SG_ 927 BU_NetCfg_EBCM_ePT "030000h";
BA_ "FlexKomSigStartPos" SG_ 927 BU_NetCfg_EBCM_ePT 7;
BA_ "FlexKomSigName" SG_ 927 BU_NetCfg_EBCM_ePT "BU_NET_CFG_DATA_ePT";
BA_ "FlexKomSigLaenge" SG_ 927 BU_NetCfg_EBCM_ePT 24;
BA_ "FlexKomSID" SG_ 927 BU_NetCfg_EBCM_ePT 2470;
BA_ "FlexKomIsMotorola" SG_ 927 BU_NetCfg_EBCM_ePT 1;
BA_ "FlexKomComment" SG_ 927 BU_NetCfg_EBCM_ePT "Backup for network ECU config data for hybrid netw";
BA_ "GenSigSNA" SG_ 927 BU_NetCfg_ORC_ePT "0h";
BA_ "GenSigSendType" SG_ 927 BU_NetCfg_ORC_ePT 1;
BA_ "FlexKomSigStartValue" SG_ 927 BU_NetCfg_ORC_ePT "030000h";
BA_ "FlexKomSigStartPos" SG_ 927 BU_NetCfg_ORC_ePT 7;
BA_ "FlexKomSigName" SG_ 927 BU_NetCfg_ORC_ePT "BU_NET_CFG_DATA_ePT";
BA_ "FlexKomSigLaenge" SG_ 927 BU_NetCfg_ORC_ePT 24;
BA_ "FlexKomSID" SG_ 927 BU_NetCfg_ORC_ePT 2470;
BA_ "FlexKomIsMotorola" SG_ 927 BU_NetCfg_ORC_ePT 1;
BA_ "FlexKomComment" SG_ 927 BU_NetCfg_ORC_ePT "Backup for network ECU config data for hybrid netw";
BA_ "GenSigSNA" SG_ 927 BU_NetCfg_ESM_ePT "0h";
BA_ "GenSigSendType" SG_ 927 BU_NetCfg_ESM_ePT 1;
BA_ "FlexKomSigStartValue" SG_ 927 BU_NetCfg_ESM_ePT "030000h";
BA_ "FlexKomSigStartPos" SG_ 927 BU_NetCfg_ESM_ePT 7;
BA_ "FlexKomSigName" SG_ 927 BU_NetCfg_ESM_ePT "BU_NET_CFG_DATA_ePT";
BA_ "FlexKomSigLaenge" SG_ 927 BU_NetCfg_ESM_ePT 24;
BA_ "FlexKomSID" SG_ 927 BU_NetCfg_ESM_ePT 2470;
BA_ "FlexKomIsMotorola" SG_ 927 BU_NetCfg_ESM_ePT 1;
BA_ "FlexKomComment" SG_ 927 BU_NetCfg_ESM_ePT "Backup for network ECU config data for hybrid netw";
BA_ "GenSigSNA" SG_ 927 BU_NetCfg_ESC_ePT "0h";
BA_ "GenSigSendType" SG_ 927 BU_NetCfg_ESC_ePT 1;
BA_ "FlexKomSigStartValue" SG_ 927 BU_NetCfg_ESC_ePT "030000h";
BA_ "FlexKomSigStartPos" SG_ 927 BU_NetCfg_ESC_ePT 7;
BA_ "FlexKomSigName" SG_ 927 BU_NetCfg_ESC_ePT "BU_NET_CFG_DATA_ePT";
BA_ "FlexKomSigLaenge" SG_ 927 BU_NetCfg_ESC_ePT 24;
BA_ "FlexKomSID" SG_ 927 BU_NetCfg_ESC_ePT 2470;
BA_ "FlexKomIsMotorola" SG_ 927 BU_NetCfg_ESC_ePT 1;
BA_ "FlexKomComment" SG_ 927 BU_NetCfg_ESC_ePT "Backup for network ECU config data for hybrid netw";
BA_ "GenSigSNA" SG_ 927 BU_NetCfg_ECM_ePT "0h";
BA_ "GenSigSendType" SG_ 927 BU_NetCfg_ECM_ePT 1;
BA_ "FlexKomSigStartValue" SG_ 927 BU_NetCfg_ECM_ePT "030000h";
BA_ "FlexKomSigStartPos" SG_ 927 BU_NetCfg_ECM_ePT 7;
BA_ "FlexKomSigName" SG_ 927 BU_NetCfg_ECM_ePT "BU_NET_CFG_DATA_ePT";
BA_ "FlexKomSigLaenge" SG_ 927 BU_NetCfg_ECM_ePT 24;
BA_ "FlexKomSID" SG_ 927 BU_NetCfg_ECM_ePT 2470;
BA_ "FlexKomIsMotorola" SG_ 927 BU_NetCfg_ECM_ePT 1;
BA_ "FlexKomComment" SG_ 927 BU_NetCfg_ECM_ePT "Backup for network ECU config data for hybrid netw";
BA_ "GenSigSNA" SG_ 927 BU_NetCfg_HCP_ePT "0h";
BA_ "GenSigSendType" SG_ 927 BU_NetCfg_HCP_ePT 1;
BA_ "FlexKomSigStartValue" SG_ 927 BU_NetCfg_HCP_ePT "030000h";
BA_ "FlexKomSigStartPos" SG_ 927 BU_NetCfg_HCP_ePT 7;
BA_ "FlexKomSigName" SG_ 927 BU_NetCfg_HCP_ePT "BU_NET_CFG_DATA_ePT";
BA_ "FlexKomSigLaenge" SG_ 927 BU_NetCfg_HCP_ePT 24;
BA_ "FlexKomSID" SG_ 927 BU_NetCfg_HCP_ePT 2470;
BA_ "FlexKomIsMotorola" SG_ 927 BU_NetCfg_HCP_ePT 1;
BA_ "FlexKomComment" SG_ 927 BU_NetCfg_HCP_ePT "Backup for network ECU config data for hybrid netw";
BA_ "GenSigSNA" SG_ 927 BU_NetCfg_OBCM_ePT "0h";
BA_ "GenSigSendType" SG_ 927 BU_NetCfg_OBCM_ePT 1;
BA_ "FlexKomSigStartValue" SG_ 927 BU_NetCfg_OBCM_ePT "030000h";
BA_ "FlexKomSigStartPos" SG_ 927 BU_NetCfg_OBCM_ePT 7;
BA_ "FlexKomSigName" SG_ 927 BU_NetCfg_OBCM_ePT "BU_NET_CFG_DATA_ePT";
BA_ "FlexKomSigLaenge" SG_ 927 BU_NetCfg_OBCM_ePT 24;
BA_ "FlexKomSID" SG_ 927 BU_NetCfg_OBCM_ePT 2470;
BA_ "FlexKomIsMotorola" SG_ 927 BU_NetCfg_OBCM_ePT 1;
BA_ "FlexKomComment" SG_ 927 BU_NetCfg_OBCM_ePT "Backup for network ECU config data for hybrid netw";
BA_ "GenSigSNA" SG_ 927 BU_NetCfg_AHCP_ePT "0h";
BA_ "GenSigSendType" SG_ 927 BU_NetCfg_AHCP_ePT 1;
BA_ "FlexKomSigStartValue" SG_ 927 BU_NetCfg_AHCP_ePT "030000h";
BA_ "FlexKomSigStartPos" SG_ 927 BU_NetCfg_AHCP_ePT 7;
BA_ "FlexKomSigName" SG_ 927 BU_NetCfg_AHCP_ePT "BU_NET_CFG_DATA_ePT";
BA_ "FlexKomSigLaenge" SG_ 927 BU_NetCfg_AHCP_ePT 24;
BA_ "FlexKomSID" SG_ 927 BU_NetCfg_AHCP_ePT 2470;
BA_ "FlexKomIsMotorola" SG_ 927 BU_NetCfg_AHCP_ePT 1;
BA_ "FlexKomComment" SG_ 927 BU_NetCfg_AHCP_ePT "Backup for network ECU config data for hybrid netw";
BA_ "GenSigSNA" SG_ 927 BU_NetCfg_SCA_ePT "0h";
BA_ "GenSigSendType" SG_ 927 BU_NetCfg_SCA_ePT 1;
BA_ "FlexKomSigStartValue" SG_ 927 BU_NetCfg_SCA_ePT "030000h";
BA_ "FlexKomSigStartPos" SG_ 927 BU_NetCfg_SCA_ePT 7;
BA_ "FlexKomSigName" SG_ 927 BU_NetCfg_SCA_ePT "BU_NET_CFG_DATA_ePT";
BA_ "FlexKomSigLaenge" SG_ 927 BU_NetCfg_SCA_ePT 24;
BA_ "FlexKomSID" SG_ 927 BU_NetCfg_SCA_ePT 2470;
BA_ "FlexKomIsMotorola" SG_ 927 BU_NetCfg_SCA_ePT 1;
BA_ "FlexKomComment" SG_ 927 BU_NetCfg_SCA_ePT "Backup for network ECU config data for hybrid netw";
BA_ "GenSigSNA" SG_ 927 BU_NetCfg_EAC_ePT "0h";
BA_ "GenSigSendType" SG_ 927 BU_NetCfg_EAC_ePT 1;
BA_ "FlexKomSigStartValue" SG_ 927 BU_NetCfg_EAC_ePT "030000h";
BA_ "FlexKomSigStartPos" SG_ 927 BU_NetCfg_EAC_ePT 7;
BA_ "FlexKomSigName" SG_ 927 BU_NetCfg_EAC_ePT "BU_NET_CFG_DATA_ePT";
BA_ "FlexKomSigLaenge" SG_ 927 BU_NetCfg_EAC_ePT 24;
BA_ "FlexKomSID" SG_ 927 BU_NetCfg_EAC_ePT 2470;
BA_ "FlexKomIsMotorola" SG_ 927 BU_NetCfg_EAC_ePT 1;
BA_ "FlexKomComment" SG_ 927 BU_NetCfg_EAC_ePT "Backup for network ECU config data for hybrid netw";
BA_ "GenSigSNA" SG_ 927 BU_NetCfg_BPCM_ePT "0h";
BA_ "GenSigSendType" SG_ 927 BU_NetCfg_BPCM_ePT 1;
BA_ "FlexKomSigStartValue" SG_ 927 BU_NetCfg_BPCM_ePT "030000h";
BA_ "FlexKomSigStartPos" SG_ 927 BU_NetCfg_BPCM_ePT 7;
BA_ "FlexKomSigName" SG_ 927 BU_NetCfg_BPCM_ePT "BU_NET_CFG_DATA_ePT";
BA_ "FlexKomSigLaenge" SG_ 927 BU_NetCfg_BPCM_ePT 24;
BA_ "FlexKomSID" SG_ 927 BU_NetCfg_BPCM_ePT 2470;
BA_ "FlexKomIsMotorola" SG_ 927 BU_NetCfg_BPCM_ePT 1;
BA_ "FlexKomComment" SG_ 927 BU_NetCfg_BPCM_ePT "Backup for network ECU config data for hybrid netw";
BA_ "GenSigSNA" SG_ 927 BU_NetCfg_APM_ePT "0h";
BA_ "GenSigSendType" SG_ 927 BU_NetCfg_APM_ePT 1;
BA_ "FlexKomSigStartValue" SG_ 927 BU_NetCfg_APM_ePT "030000h";
BA_ "FlexKomSigStartPos" SG_ 927 BU_NetCfg_APM_ePT 7;
BA_ "FlexKomSigName" SG_ 927 BU_NetCfg_APM_ePT "BU_NET_CFG_DATA_ePT";
BA_ "FlexKomSigLaenge" SG_ 927 BU_NetCfg_APM_ePT 24;
BA_ "FlexKomSID" SG_ 927 BU_NetCfg_APM_ePT 2470;
BA_ "FlexKomIsMotorola" SG_ 927 BU_NetCfg_APM_ePT 1;
BA_ "FlexKomComment" SG_ 927 BU_NetCfg_APM_ePT "Backup for network ECU config data for hybrid netw";
BA_ "GenSigSNA" SG_ 927 BU_NetCfg_BSMO_ePT "0h";
BA_ "GenSigSendType" SG_ 927 BU_NetCfg_BSMO_ePT 1;
BA_ "FlexKomSigStartValue" SG_ 927 BU_NetCfg_BSMO_ePT "030000h";
BA_ "FlexKomSigStartPos" SG_ 927 BU_NetCfg_BSMO_ePT 7;
BA_ "FlexKomSigName" SG_ 927 BU_NetCfg_BSMO_ePT "BU_NET_CFG_DATA_ePT";
BA_ "FlexKomSigLaenge" SG_ 927 BU_NetCfg_BSMO_ePT 24;
BA_ "FlexKomSID" SG_ 927 BU_NetCfg_BSMO_ePT 2470;
BA_ "FlexKomIsMotorola" SG_ 927 BU_NetCfg_BSMO_ePT 1;
BA_ "FlexKomComment" SG_ 927 BU_NetCfg_BSMO_ePT "Backup for network ECU config data for hybrid netw";
BA_ "GenSigSNA" SG_ 927 BU_NetCfg_IDCM_ePT "0h";
BA_ "GenSigSendType" SG_ 927 BU_NetCfg_IDCM_ePT 1;
BA_ "FlexKomSigStartValue" SG_ 927 BU_NetCfg_IDCM_ePT "030000h";
BA_ "FlexKomSigStartPos" SG_ 927 BU_NetCfg_IDCM_ePT 7;
BA_ "FlexKomSigName" SG_ 927 BU_NetCfg_IDCM_ePT "BU_NET_CFG_DATA_ePT";
BA_ "FlexKomSigLaenge" SG_ 927 BU_NetCfg_IDCM_ePT 24;
BA_ "FlexKomSID" SG_ 927 BU_NetCfg_IDCM_ePT 2470;
BA_ "FlexKomIsMotorola" SG_ 927 BU_NetCfg_IDCM_ePT 1;
BA_ "FlexKomComment" SG_ 927 BU_NetCfg_IDCM_ePT "Backup for network ECU config data for hybrid netw";
BA_ "GenSigSNA" SG_ 927 BU_NetCfg_MCPA_ePT "0h";
BA_ "GenSigSendType" SG_ 927 BU_NetCfg_MCPA_ePT 1;
BA_ "FlexKomSigStartValue" SG_ 927 BU_NetCfg_MCPA_ePT "030000h";
BA_ "FlexKomSigStartPos" SG_ 927 BU_NetCfg_MCPA_ePT 7;
BA_ "FlexKomSigName" SG_ 927 BU_NetCfg_MCPA_ePT "BU_NET_CFG_DATA_ePT";
BA_ "FlexKomSigLaenge" SG_ 927 BU_NetCfg_MCPA_ePT 24;
BA_ "FlexKomSID" SG_ 927 BU_NetCfg_MCPA_ePT 2470;
BA_ "FlexKomIsMotorola" SG_ 927 BU_NetCfg_MCPA_ePT 1;
BA_ "FlexKomComment" SG_ 927 BU_NetCfg_MCPA_ePT "Backup for network ECU config data for hybrid netw";
BA_ "GenSigSNA" SG_ 927 BU_NetCfg_EVCU2_ePT "0h";
BA_ "GenSigSendType" SG_ 927 BU_NetCfg_EVCU2_ePT 1;
BA_ "FlexKomSigStartValue" SG_ 927 BU_NetCfg_EVCU2_ePT "030000h";
BA_ "FlexKomSigStartPos" SG_ 927 BU_NetCfg_EVCU2_ePT 7;
BA_ "FlexKomSigName" SG_ 927 BU_NetCfg_EVCU2_ePT "BU_NET_CFG_DATA_ePT";
BA_ "FlexKomSigLaenge" SG_ 927 BU_NetCfg_EVCU2_ePT 24;
BA_ "FlexKomSID" SG_ 927 BU_NetCfg_EVCU2_ePT 2470;
BA_ "FlexKomIsMotorola" SG_ 927 BU_NetCfg_EVCU2_ePT 1;
BA_ "FlexKomComment" SG_ 927 BU_NetCfg_EVCU2_ePT "Backup for network ECU config data for hybrid netw";
BA_ "GenSigSNA" SG_ 927 BU_NetCfg_MCPB_ePT "0h";
BA_ "GenSigSendType" SG_ 927 BU_NetCfg_MCPB_ePT 1;
BA_ "FlexKomSigStartValue" SG_ 927 BU_NetCfg_MCPB_ePT "030000h";
BA_ "FlexKomSigStartPos" SG_ 927 BU_NetCfg_MCPB_ePT 7;
BA_ "FlexKomSigName" SG_ 927 BU_NetCfg_MCPB_ePT "BU_NET_CFG_DATA_ePT";
BA_ "FlexKomSigLaenge" SG_ 927 BU_NetCfg_MCPB_ePT 24;
BA_ "FlexKomSID" SG_ 927 BU_NetCfg_MCPB_ePT 2470;
BA_ "FlexKomIsMotorola" SG_ 927 BU_NetCfg_MCPB_ePT 1;
BA_ "FlexKomComment" SG_ 927 BU_NetCfg_MCPB_ePT "Backup for network ECU config data for hybrid netw";
BA_ "GenSigSNA" SG_ 928 ECM_APPL6 "0h";
BA_ "GenSigSendType" SG_ 928 ECM_APPL6 1;
BA_ "FlexKomSigStartValue" SG_ 928 ECM_APPL6 "0000000000000000h";
BA_ "FlexKomSigStartPos" SG_ 928 ECM_APPL6 7;
BA_ "FlexKomSigName" SG_ 928 ECM_APPL6 "ECM_APPL6";
BA_ "FlexKomSigLaenge" SG_ 928 ECM_APPL6 64;
BA_ "FlexKomSID" SG_ 928 ECM_APPL6 784;
BA_ "FlexKomIsMotorola" SG_ 928 ECM_APPL6 1;
BA_ "FlexKomComment" SG_ 928 ECM_APPL6 "CCP 80ms DAQ  (from ENGINE to external tool)";
BA_ "GenSigStartValue" SG_ 929 Nav_Display_Cluster_Setting 1;
BA_ "GenSigSNA" SG_ 929 Nav_Display_Cluster_Setting "0h";
BA_ "GenSigSendType" SG_ 929 Nav_Display_Cluster_Setting 5;
BA_ "GenSigCycleTime" SG_ 929 Nav_Display_Cluster_Setting 1000;
BA_ "FlexKomSigStartValue" SG_ 929 Nav_Display_Cluster_Setting "07FFFFFFFF004000h";
BA_ "FlexKomSigStartPos" SG_ 929 Nav_Display_Cluster_Setting 7;
BA_ "FlexKomSigName" SG_ 929 Nav_Display_Cluster_Setting "Radio_A3_Pkt";
BA_ "FlexKomSigLaenge" SG_ 929 Nav_Display_Cluster_Setting 64;
BA_ "FlexKomSID" SG_ 929 Nav_Display_Cluster_Setting 2562;
BA_ "FlexKomIsMotorola" SG_ 929 Nav_Display_Cluster_Setting 1;
BA_ "FlexKomComment" SG_ 929 Nav_Display_Cluster_Setting "Radio A3 packet";
BA_ "GenSigSNA" SG_ 936 ECM_APPL7 "0h";
BA_ "GenSigSendType" SG_ 936 ECM_APPL7 1;
BA_ "FlexKomSigStartValue" SG_ 936 ECM_APPL7 "0000000000000000h";
BA_ "FlexKomSigStartPos" SG_ 936 ECM_APPL7 7;
BA_ "FlexKomSigName" SG_ 936 ECM_APPL7 "ECM_APPL7";
BA_ "FlexKomSigLaenge" SG_ 936 ECM_APPL7 64;
BA_ "FlexKomSID" SG_ 936 ECM_APPL7 1111;
BA_ "FlexKomIsMotorola" SG_ 936 ECM_APPL7 1;
BA_ "FlexKomComment" SG_ 936 ECM_APPL7 "Application";
BA_ "GenSigTimeout_IC" SG_ 937 SOUND_LK 10500;
BA_ "GenSigSNA" SG_ 937 SOUND_LK "0h";
BA_ "GenSigSendType" SG_ 937 SOUND_LK 5;
BA_ "GenSigCycleTime" SG_ 937 SOUND_LK 1000;
BA_ "FlexKomSigStartValue" SG_ 937 SOUND_LK "00FFFFFFFF60h";
BA_ "FlexKomSigStartPos" SG_ 937 SOUND_LK 7;
BA_ "FlexKomSigName" SG_ 937 SOUND_LK "CBC_CFG_STAT";
BA_ "FlexKomSigLaenge" SG_ 937 SOUND_LK 48;
BA_ "FlexKomSID" SG_ 937 SOUND_LK 843;
BA_ "FlexKomIsMotorola" SG_ 937 SOUND_LK 1;
BA_ "FlexKomComment" SG_ 937 SOUND_LK "Configuration status CBC";
BA_ "GenSigTimeout_IC" SG_ 937 FLASH_LK 10500;
BA_ "GenSigSNA" SG_ 937 FLASH_LK "0h";
BA_ "GenSigSendType" SG_ 937 FLASH_LK 5;
BA_ "GenSigCycleTime" SG_ 937 FLASH_LK 1000;
BA_ "FlexKomSigStartValue" SG_ 937 FLASH_LK "00FFFFFFFF60h";
BA_ "FlexKomSigStartPos" SG_ 937 FLASH_LK 7;
BA_ "FlexKomSigName" SG_ 937 FLASH_LK "CBC_CFG_STAT";
BA_ "FlexKomSigLaenge" SG_ 937 FLASH_LK 48;
BA_ "FlexKomSID" SG_ 937 FLASH_LK 843;
BA_ "FlexKomIsMotorola" SG_ 937 FLASH_LK 1;
BA_ "FlexKomComment" SG_ 937 FLASH_LK "Configuration status CBC";
BA_ "GenSigTimeout_IC" SG_ 937 HL_WPR 10500;
BA_ "GenSigSNA" SG_ 937 HL_WPR "0h";
BA_ "GenSigSendType" SG_ 937 HL_WPR 5;
BA_ "GenSigCycleTime" SG_ 937 HL_WPR 1000;
BA_ "FlexKomSigStartValue" SG_ 937 HL_WPR "00FFFFFFFF60h";
BA_ "FlexKomSigStartPos" SG_ 937 HL_WPR 7;
BA_ "FlexKomSigName" SG_ 937 HL_WPR "CBC_CFG_STAT";
BA_ "FlexKomSigLaenge" SG_ 937 HL_WPR 48;
BA_ "FlexKomSID" SG_ 937 HL_WPR 843;
BA_ "FlexKomIsMotorola" SG_ 937 HL_WPR 1;
BA_ "FlexKomComment" SG_ 937 HL_WPR "Configuration status CBC";
BA_ "GenSigTimeout_IC" SG_ 937 ILL_APRCH_TIME 10500;
BA_ "GenSigStartValue" SG_ 937 ILL_APRCH_TIME 255;
BA_ "GenSigSNA" SG_ 937 ILL_APRCH_TIME "FFh";
BA_ "GenSigSendType" SG_ 937 ILL_APRCH_TIME 5;
BA_ "GenSigCycleTime" SG_ 937 ILL_APRCH_TIME 1000;
BA_ "FlexKomSigStartValue" SG_ 937 ILL_APRCH_TIME "00FFFFFFFF60h";
BA_ "FlexKomSigStartPos" SG_ 937 ILL_APRCH_TIME 7;
BA_ "FlexKomSigName" SG_ 937 ILL_APRCH_TIME "CBC_CFG_STAT";
BA_ "FlexKomSigLaenge" SG_ 937 ILL_APRCH_TIME 48;
BA_ "FlexKomSID" SG_ 937 ILL_APRCH_TIME 843;
BA_ "FlexKomIsMotorola" SG_ 937 ILL_APRCH_TIME 1;
BA_ "FlexKomComment" SG_ 937 ILL_APRCH_TIME "Configuration status CBC";
BA_ "GenSigTimeout_IC" SG_ 937 HL_DLY_TIME 10500;
BA_ "GenSigStartValue" SG_ 937 HL_DLY_TIME 255;
BA_ "GenSigSNA" SG_ 937 HL_DLY_TIME "FFh";
BA_ "GenSigSendType" SG_ 937 HL_DLY_TIME 5;
BA_ "GenSigCycleTime" SG_ 937 HL_DLY_TIME 1000;
BA_ "FlexKomSigStartValue" SG_ 937 HL_DLY_TIME "00FFFFFFFF60h";
BA_ "FlexKomSigStartPos" SG_ 937 HL_DLY_TIME 7;
BA_ "FlexKomSigName" SG_ 937 HL_DLY_TIME "CBC_CFG_STAT";
BA_ "FlexKomSigLaenge" SG_ 937 HL_DLY_TIME 48;
BA_ "FlexKomSID" SG_ 937 HL_DLY_TIME 843;
BA_ "FlexKomIsMotorola" SG_ 937 HL_DLY_TIME 1;
BA_ "FlexKomComment" SG_ 937 HL_DLY_TIME "Configuration status CBC";
BA_ "GenSigTimeout_IC" SG_ 937 DRL_ON 10500;
BA_ "GenSigSNA" SG_ 937 DRL_ON "0h";
BA_ "GenSigSendType" SG_ 937 DRL_ON 5;
BA_ "GenSigCycleTime" SG_ 937 DRL_ON 1000;
BA_ "FlexKomSigStartValue" SG_ 937 DRL_ON "00FFFFFFFF60h";
BA_ "FlexKomSigStartPos" SG_ 937 DRL_ON 7;
BA_ "FlexKomSigName" SG_ 937 DRL_ON "CBC_CFG_STAT";
BA_ "FlexKomSigLaenge" SG_ 937 DRL_ON 48;
BA_ "FlexKomSID" SG_ 937 DRL_ON 843;
BA_ "FlexKomIsMotorola" SG_ 937 DRL_ON 1;
BA_ "FlexKomComment" SG_ 937 DRL_ON "Configuration status CBC";
BA_ "GenSigTimeout_IC" SG_ 937 SOUND_RS 10500;
BA_ "GenSigSNA" SG_ 937 SOUND_RS "0h";
BA_ "GenSigSendType" SG_ 937 SOUND_RS 5;
BA_ "GenSigCycleTime" SG_ 937 SOUND_RS 1000;
BA_ "FlexKomSigStartValue" SG_ 937 SOUND_RS "00h";
BA_ "FlexKomSigStartPos" SG_ 937 SOUND_RS 52;
BA_ "FlexKomSigName" SG_ 937 SOUND_RS "SOUND_RS";
BA_ "FlexKomSigLaenge" SG_ 937 SOUND_RS 1;
BA_ "FlexKomSID" SG_ 937 SOUND_RS 966;
BA_ "FlexKomIsMotorola" SG_ 937 SOUND_RS 1;
BA_ "FlexKomComment" SG_ 937 SOUND_RS "Sound horn on Remote Start ; no = [0], yes = [1]";
BA_ "GenSigTimeout_IC" SG_ 937 SOUND_LK_1ST_2ND 10500;
BA_ "GenSigStartValue" SG_ 937 SOUND_LK_1ST_2ND 3;
BA_ "GenSigSNA" SG_ 937 SOUND_LK_1ST_2ND "3h";
BA_ "GenSigSendType" SG_ 937 SOUND_LK_1ST_2ND 5;
BA_ "GenSigCycleTime" SG_ 937 SOUND_LK_1ST_2ND 1000;
BA_ "FlexKomSigStartValue" SG_ 937 SOUND_LK_1ST_2ND "03h";
BA_ "FlexKomSigStartPos" SG_ 937 SOUND_LK_1ST_2ND 57;
BA_ "FlexKomSigName" SG_ 937 SOUND_LK_1ST_2ND "SOUND_LK_1ST_2ND";
BA_ "FlexKomSigLaenge" SG_ 937 SOUND_LK_1ST_2ND 2;
BA_ "FlexKomSID" SG_ 937 SOUND_LK_1ST_2ND 1956;
BA_ "FlexKomIsMotorola" SG_ 937 SOUND_LK_1ST_2ND 1;
BA_ "FlexKomComment" SG_ 937 SOUND_LK_1ST_2ND "Sound horn on lock status";
BA_ "GenSigTimeout_ETM" SG_ 938 A_MPG 10500;
BA_ "GenSigSNA" SG_ 938 A_MPG "3FFh";
BA_ "GenSigCycleTime" SG_ 938 A_MPG 1000;
BA_ "FlexKomSigStartValue" SG_ 938 A_MPG "0000000000000000h";
BA_ "FlexKomSigStartPos" SG_ 938 A_MPG 7;
BA_ "FlexKomSigName" SG_ 938 A_MPG "IC_TripData_Pkt_1";
BA_ "FlexKomSigLaenge" SG_ 938 A_MPG 64;
BA_ "FlexKomSID" SG_ 938 A_MPG 2585;
BA_ "FlexKomIsMotorola" SG_ 938 A_MPG 1;
BA_ "FlexKomComment" SG_ 938 A_MPG "IC Trip data packet 1";
BA_ "GenSigTimeout_ETM" SG_ 938 A_EV_Miles 10500;
BA_ "GenSigSNA" SG_ 938 A_EV_Miles "FFFFFFh";
BA_ "GenSigCycleTime" SG_ 938 A_EV_Miles 1000;
BA_ "FlexKomSigStartValue" SG_ 938 A_EV_Miles "0000000000000000h";
BA_ "FlexKomSigStartPos" SG_ 938 A_EV_Miles 7;
BA_ "FlexKomSigName" SG_ 938 A_EV_Miles "IC_TripData_Pkt_1";
BA_ "FlexKomSigLaenge" SG_ 938 A_EV_Miles 64;
BA_ "FlexKomSID" SG_ 938 A_EV_Miles 2585;
BA_ "FlexKomIsMotorola" SG_ 938 A_EV_Miles 1;
BA_ "FlexKomComment" SG_ 938 A_EV_Miles "IC Trip data packet 1";
BA_ "GenSigTimeout_ETM" SG_ 938 A_EV_Kilometers 10500;
BA_ "GenSigSNA" SG_ 938 A_EV_Kilometers "FFFFFFh";
BA_ "GenSigCycleTime" SG_ 938 A_EV_Kilometers 1000;
BA_ "FlexKomSigStartValue" SG_ 938 A_EV_Kilometers "0000000000000000h";
BA_ "FlexKomSigStartPos" SG_ 938 A_EV_Kilometers 7;
BA_ "FlexKomSigName" SG_ 938 A_EV_Kilometers "IC_TripData_Pkt_1";
BA_ "FlexKomSigLaenge" SG_ 938 A_EV_Kilometers 64;
BA_ "FlexKomSID" SG_ 938 A_EV_Kilometers 2585;
BA_ "FlexKomIsMotorola" SG_ 938 A_EV_Kilometers 1;
BA_ "FlexKomComment" SG_ 938 A_EV_Kilometers "IC Trip data packet 1";
BA_ "GenSigTimeout_ETM" SG_ 939 A_KMpL 10500;
BA_ "GenSigSNA" SG_ 939 A_KMpL "3FFh";
BA_ "GenSigCycleTime" SG_ 939 A_KMpL 1000;
BA_ "FlexKomSigStartValue" SG_ 939 A_KMpL "0000000000000000h";
BA_ "FlexKomSigStartPos" SG_ 939 A_KMpL 7;
BA_ "FlexKomSigName" SG_ 939 A_KMpL "IC_TripData_Pkt_2";
BA_ "FlexKomSigLaenge" SG_ 939 A_KMpL 64;
BA_ "FlexKomSID" SG_ 939 A_KMpL 2584;
BA_ "FlexKomIsMotorola" SG_ 939 A_KMpL 1;
BA_ "FlexKomComment" SG_ 939 A_KMpL "IC Trip data packet 2";
BA_ "GenSigTimeout_ETM" SG_ 939 A_Hybrid_Miles 10500;
BA_ "GenSigSNA" SG_ 939 A_Hybrid_Miles "FFFFFFh";
BA_ "GenSigCycleTime" SG_ 939 A_Hybrid_Miles 1000;
BA_ "FlexKomSigStartValue" SG_ 939 A_Hybrid_Miles "0000000000000000h";
BA_ "FlexKomSigStartPos" SG_ 939 A_Hybrid_Miles 7;
BA_ "FlexKomSigName" SG_ 939 A_Hybrid_Miles "IC_TripData_Pkt_2";
BA_ "FlexKomSigLaenge" SG_ 939 A_Hybrid_Miles 64;
BA_ "FlexKomSID" SG_ 939 A_Hybrid_Miles 2584;
BA_ "FlexKomIsMotorola" SG_ 939 A_Hybrid_Miles 1;
BA_ "FlexKomComment" SG_ 939 A_Hybrid_Miles "IC Trip data packet 2";
BA_ "GenSigTimeout_ETM" SG_ 939 A_Hybrid_Kilometers 10500;
BA_ "GenSigSNA" SG_ 939 A_Hybrid_Kilometers "FFFFFFh";
BA_ "GenSigCycleTime" SG_ 939 A_Hybrid_Kilometers 1000;
BA_ "FlexKomSigStartValue" SG_ 939 A_Hybrid_Kilometers "0000000000000000h";
BA_ "FlexKomSigStartPos" SG_ 939 A_Hybrid_Kilometers 7;
BA_ "FlexKomSigName" SG_ 939 A_Hybrid_Kilometers "IC_TripData_Pkt_2";
BA_ "FlexKomSigLaenge" SG_ 939 A_Hybrid_Kilometers 64;
BA_ "FlexKomSID" SG_ 939 A_Hybrid_Kilometers 2584;
BA_ "FlexKomIsMotorola" SG_ 939 A_Hybrid_Kilometers 1;
BA_ "FlexKomComment" SG_ 939 A_Hybrid_Kilometers "IC Trip data packet 2";
BA_ "GenSigTimeout_ETM" SG_ 940 A_Total_Dist_Miles 10500;
BA_ "GenSigSNA" SG_ 940 A_Total_Dist_Miles "FFFFFFh";
BA_ "GenSigCycleTime" SG_ 940 A_Total_Dist_Miles 1000;
BA_ "FlexKomSigStartValue" SG_ 940 A_Total_Dist_Miles "00FF000000000000h";
BA_ "FlexKomSigStartPos" SG_ 940 A_Total_Dist_Miles 7;
BA_ "FlexKomSigName" SG_ 940 A_Total_Dist_Miles "IC_TripData_Pkt_3";
BA_ "FlexKomSigLaenge" SG_ 940 A_Total_Dist_Miles 64;
BA_ "FlexKomSID" SG_ 940 A_Total_Dist_Miles 2583;
BA_ "FlexKomIsMotorola" SG_ 940 A_Total_Dist_Miles 1;
BA_ "FlexKomComment" SG_ 940 A_Total_Dist_Miles "IC Trip data packet 3";
BA_ "GenSigTimeout_ETM" SG_ 940 A_Total_Dist_Kilometers 10500;
BA_ "GenSigSNA" SG_ 940 A_Total_Dist_Kilometers "FFFFFFh";
BA_ "GenSigCycleTime" SG_ 940 A_Total_Dist_Kilometers 1000;
BA_ "FlexKomSigStartValue" SG_ 940 A_Total_Dist_Kilometers "00FF000000000000h";
BA_ "FlexKomSigStartPos" SG_ 940 A_Total_Dist_Kilometers 7;
BA_ "FlexKomSigName" SG_ 940 A_Total_Dist_Kilometers "IC_TripData_Pkt_3";
BA_ "FlexKomSigLaenge" SG_ 940 A_Total_Dist_Kilometers 64;
BA_ "FlexKomSID" SG_ 940 A_Total_Dist_Kilometers 2583;
BA_ "FlexKomIsMotorola" SG_ 940 A_Total_Dist_Kilometers 1;
BA_ "FlexKomComment" SG_ 940 A_Total_Dist_Kilometers "IC Trip data packet 3";
VAL_ 838 AS_CHIME_TYPE 0 "NONE" 1 "TYP_1" 2 "TYP_2" 3 "TYP_3" 4 "TYP_4" 5 "TYP_5" 6 "TYP_6" 7 "TYP_7" 8 "TYP_8" 9 "TYP_9" 10 "TYP_10" 11 "TYP_11" 12 "TYP_12" 13 "TYP_13" 14 "TYP_14" 15 "SNA" ;
VAL_ 840 FailSafeError 65535 "SNA" ;
VAL_ 848 DateTmMinute 255 "SNA" ;
VAL_ 848 DateTmHour 255 "SNA" ;
VAL_ 848 DateTmYear 65535 "SNA" ;
VAL_ 848 DateTmMonth 255 "SNA" ;
VAL_ 848 DateTmDay 255 "SNA" ;
VAL_ 848 DateTmFormat 0 "NDEF0" 1 "FORMAT_12H" 2 "FORMAT_24H" 3 "FORMAT_0" 4 "FORMAT_1" 5 "FORMAT_2" 6 "FORMAT_3" 7 "SNA" ;
VAL_ 848 DateTmSec 255 "SNA" ;
VAL_ 856 CMP_DIR 0 "CMP_N" 1 "CMP_N_E" 2 "CMP_E" 3 "CMP_S_E" 4 "CMP_S" 5 "CMP_S_W" 6 "CMP_W" 7 "CMP_N_W" 8 "NONE" 15 "SNA" ;
VAL_ 881 SwayBar_Sts 0 "UNLOCKED" 1 "LOCKED" 2 "S_I_P" 3 "SNA" ;
VAL_ 881 SwayBarEVICDisplay 0 "TM0" 1 "TM1" 2 "TM2" 3 "TM3" 4 "TM4" 5 "TM5" 6 "TM6" 7 "TM7" 8 "TM8" 9 "TM9" 10 "TM10" 11 "TM11" 12 "TM12" 13 "TM13" 14 "TM14" 15 "SNA" ;
VAL_ 881 SwayBar_LEDRq 0 "OFF" 1 "CONT" 2 "BLINK" 3 "SNA" ;
VAL_ 886 DIST_TO_TURN_2 65535 "SNA" ;
VAL_ 886 UNITS_2 0 "NO_UNITS" 1 "MILE" 2 "FEET" 3 "KM" 4 "METER" 5 "YARD" 7 "SNA" ;
VAL_ 886 NAV_ARROW_2 0 "NAV_NOT_ACT" ;
VAL_ 897 VC_PBTyp 0 "MECH" 1 "EPB_MOC" 2 "EPB_CP" 3 "IMOC" 4 "ICP" 7 "SNA" ;
VAL_ 897 VC_TPMS_Configuration 0 "NHTSA" 1 "NAFTA" 2 "ECE" 3 "OTHER" 4 "CHINA" 7 "SNA" ;
VAL_ 897 VC_HybridType 0 "NONE" 1 "BEV" 2 "HEV" 3 "PHEV" 4 "BSG48" ;
VAL_ 897 VC_Temp_Display_Resolution 0 "One_Degree_C" 1 "Half_Degree_C" ;
VAL_ 897 VC_AGSprsnt 0 "Not_Present" 1 "Present" ;
VAL_ 897 VC_MOC_Type 0 "NO_MOC" 1 "MOC_BREMBO" 2 "MOC_CONTI" ;
VAL_ 897 VC_Brake_Type 0 "None" 1 "1" 2 "2" 3 "3" 4 "4" 5 "5" 6 "6" 7 "7" 8 "8" 9 "9" 10 "10" 11 "11" 12 "12" 13 "13" 14 "14" 15 "15" ;
VAL_ 897 VC_Suspension_Type 0 "None" 1 "1" 2 "2" 3 "3" 4 "4" 5 "5" 6 "6" 7 "7" 8 "8" 9 "9" 10 "10" 11 "11" 12 "12" 13 "13" 14 "14" 15 "15" ;
VAL_ 897 VC_GlareFree_Prsnt 0 "Not_Present" 1 "Present" ;
VAL_ 897 VC_PAD_Lamp_Ctrl 0 "CLUSTER" 1 "ORC" ;
VAL_ 897 VC_Vehicle_Package 0 "None" 1 "Type_1" 2 "Type_2" 3 "Type_3" 4 "Type_4" 5 "Type_5" 6 "Type_6" 7 "Type_7" ;
VAL_ 897 VC_TrafficSignInfo 0 "Not_Present" 1 "Present" ;
VAL_ 897 VC_LaneCentering 0 "Not_Present" 1 "Present" ;
VAL_ 897 VC_LDW_Audio 0 "Not_Present" 1 "Present" ;
VAL_ 897 VC_VehCfg7_Stat 0 "NA" 1 "PROGAMMED" 2 "REQUEST_DATA" 3 "SNA" ;
VAL_ 897 VC_TransType 0 "NP" 1 "SI_EVT_Hybrid_Trans" 2 "MTA" 3 "c40TES" 4 "Aisin_LD" 5 "W5A580" 6 "c62TE" 7 "c65RFE" 8 "c66RFE" 9 "c68RFE" 10 "AISIN_HD" 11 "DDCT_C635" 12 "HPT_6F24" 13 "ZF_8Spd" 14 "ZF_9Spd" 63 "SNA" ;
VAL_ 897 VC_AS_ERS 0 "NONE" 1 "ERS" 2 "AS" 3 "SNA" ;
VAL_ 897 VC_ACC_Type 0 "NONE" 1 "ACC" 2 "STOP" 3 "GO" ;
VAL_ 897 VC_AxleLockerPrsnt 0 "NONE" 1 "REAR" 2 "FTRR" ;
VAL_ 898 VC_BU_VehCfg7_Stat 0 "NA" 1 "PROGAMMED" 2 "NA1" 3 "SNA" ;
VAL_ 898 VC_BU_TransType 0 "NP" 1 "SI_EVT_Hybrid_Trans" 2 "MTA" 3 "c40TES" 4 "Aisin_LD" 5 "W5A580" 6 "c62TE" 7 "c65RFE" 8 "c66RFE" 9 "c68RFE" 10 "AISIN_HD" 11 "DDCT_C635" 12 "HPT_6F24" 13 "ZF_8Spd" 14 "ZF_9Spd" 63 "SNA" ;
VAL_ 898 VC_BU_AS_ERS 0 "NONE" 1 "ERS" 2 "AS" 3 "SNA" ;
VAL_ 898 VC_BU_ACC_Type 0 "NONE" 1 "ACC" 2 "STOP" 3 "GO" ;
VAL_ 898 VC_BU_AxleLockerPrsnt 0 "NONE" 1 "REAR" 2 "FTRR" ;
VAL_ 898 VC_BU_PBTyp 0 "MECH" 1 "EPB_MOC" 2 "EPB_CP" 3 "IMOC" 4 "ICP" 7 "SNA" ;
VAL_ 898 VC_BU_TPMS_Configuration 0 "NHTSA" 1 "NAFTA" 2 "ECE" 3 "OTHER" 4 "CHINA" 7 "SNA" ;
VAL_ 898 VC_BU_HybridType 0 "NONE" 1 "BEV" 2 "HEV" 3 "PHEV" 4 "BSG48" ;
VAL_ 898 VC_BU_Temp_Display_Resolution 0 "One_Degree_C" 1 "Half_Degree_C" ;
VAL_ 898 VC_BU_AGSprsnt 0 "Not_Present" 1 "Present" ;
VAL_ 898 VC_BU_MOC_Type 0 "NO_MOC" 1 "MOC_BREMBO" 2 "MOC_CONTI" ;
VAL_ 898 VC_BU_Brake_Type 0 "None" 1 "1" 2 "2" 3 "3" 4 "4" 5 "5" 6 "6" 7 "7" 8 "8" 9 "9" 10 "10" 11 "11" 12 "12" 13 "13" 14 "14" 15 "15" ;
VAL_ 898 VC_BU_Suspension_Type 0 "None" 1 "1" 2 "2" 3 "3" 4 "4" 5 "5" 6 "6" 7 "7" 8 "8" 9 "9" 10 "10" 11 "11" 12 "12" 13 "13" 14 "14" 15 "15" ;
VAL_ 898 VC_BU_GlareFree_Prsnt 0 "Not_Present" 1 "Present" ;
VAL_ 898 VC_BU_PAD_Lamp_Ctrl 0 "CLUSTER" 1 "ORC" ;
VAL_ 898 VC_BU_Vehicle_Package 0 "NA" 1 "Type_1" 2 "Type_2" 3 "Type_3" 4 "Type_4" 5 "Type_5" 6 "Type_6" 7 "Type_7" ;
VAL_ 898 VC_BU_TrafficSignInfo 0 "Not_Present" 1 "Present" ;
VAL_ 898 VC_BU_LDW_Audio 0 "Not_Present" 1 "Present" ;
VAL_ 898 VC_BU_LaneCentering 0 "Not_Present" 1 "Present" ;
VAL_ 906 VC_VehCfg8_Stat 0 "NA" 1 "PROGAMMED" 2 "REQUEST_DATA" 3 "SNA" ;
VAL_ 906 VC_Steering_Cfactor 0 "TYPE_1" 1 "TYPE_2" 2 "TYPE_3" 3 "TYPE_4" ;
VAL_ 906 VC_Speedometer_Tolerance 0 "Tolerance_0" 1 "Tolerance_1" 2 "Tolerance_2" 3 "Tolerance_3" 4 "Tolerance_4" 5 "Tolerance_5" 6 "Tolerance_6" 7 "Tolerance_7" 8 "Tolerance_8" 9 "Tolerance_9" 10 "Tolerance_10" 11 "Tolerance_Neg1" 12 "Tolerance_Neg2" 13 "Tolerance_Neg3" 14 "Tolerance_Neg4" 15 "Tolerance_Neg5" ;
VAL_ 906 VC_Increasing_Speed_Constant 0 "Increasing_0" 1 "Increasing_1" 2 "Increasing_2" 3 "Increasing_3" 4 "Increasing_4" 5 "Increasing_5" 6 "Increasing_6" 7 "Increasing_7" ;
VAL_ 906 VC_SBL_FBL_CORNERING_PRSNT 0 "Not_Present" 1 "SBL_FBL_Present" 2 "Cornering_Present" ;
VAL_ 906 VC_BEAM_SHAPING_PRSNT 0 "Not_Present" 1 "Present" ;
VAL_ 906 VC_DBL_PRSNT 0 "Not_Present" 1 "Present" ;
VAL_ 906 VC_FADPrsnt 0 "Not_Present" 1 "Present" ;
VAL_ 906 VC_AVAC_PRSNT 0 "Not_Present" 1 "Present" ;
VAL_ 906 VC_WHL_BASE_LENGTH 0 "Not_Used" 1 "Length_1" 2 "Length_2" 3 "Length_3" 4 "Length_4" 5 "Length_5" 6 "Length_6" 7 "Length_7" 8 "Length_8" 9 "Length_9" 10 "Length_10" 11 "Length_11" 12 "Length_12" 13 "Length_13" 14 "Length_14" 15 "Length_15" ;
VAL_ 906 VC_VP_Level 0 "None" 1 "LTM" 2 "ETM" ;
VAL_ 906 VC_PPPAHardBtn 0 "Not_Present" 1 "Present" ;
VAL_ 906 VC_PEB_PRSNT 0 "Not_Present" 1 "Present" ;
VAL_ 906 VC_TACHO_TYPE 0 "DISABLED" 1 "TYP_1" 2 "TYP_2" 3 "TYP_3" ;
VAL_ 907 VC_BU_Increasing_Speed_Constant 0 "Increasing_0" 1 "Increasing_1" 2 "Increasing_2" 3 "Increasing_3" 4 "Increasing_4" 5 "Increasing_5" 6 "Increasing_6" 7 "Increasing_7" ;
VAL_ 907 VC_BU_SBL_FBL_CORNERING_PRSNT 0 "Not_Present" 1 "SBL_FBL_Present" 2 "Cornering_Present" ;
VAL_ 907 VC_BU_BEAM_SHAPING_PRSNT 0 "Not_Present" 1 "Present" ;
VAL_ 907 VC_BU_DBL_PRSNT 0 "Not_Present" 1 "Present" ;
VAL_ 907 VC_BU_FADPrsnt 0 "Not_Present" 1 "Present" ;
VAL_ 907 VC_BU_AVAC_PRSNT 0 "Not_Present" 1 "Present" ;
VAL_ 907 VC_BU_WHL_BASE_LENGTH 0 "Not_Used" 1 "Length_1" 2 "Length_2" 3 "Length_3" 4 "Length_4" 5 "Length_5" 6 "Length_6" 7 "Length_7" 8 "Length_8" 9 "Length_9" 10 "Length_10" 11 "Length_11" 12 "Length_12" 13 "Length_13" 14 "Length_14" 15 "Length_15" ;
VAL_ 907 VC_BU_VP_Level 0 "None" 1 "LTM" 2 "ETM" ;
VAL_ 907 VC_BU_PPPAHardBtn 0 "Not_Present" 1 "Present" ;
VAL_ 907 VC_BU_Speedometer_Tolerance 0 "Tolerance_0" 1 "Tolerance_1" 2 "Tolerance_2" 3 "Tolerance_3" 4 "Tolerance_4" 5 "Tolerance_5" 6 "Tolerance_6" 7 "Tolerance_7" 8 "Tolerance_8" 9 "Tolerance_9" 10 "Tolerance_10" 11 "Tolerance_Neg1" 12 "Tolerance_Neg2" 13 "Tolerance_Neg3" 14 "Tolerance_Neg4" 15 "Tolerance_Neg5" ;
VAL_ 907 VC_BU_VehCfg8_Stat 0 "NA" 1 "PROGAMMED" 2 "NA1" 3 "SNA" ;
VAL_ 907 VC_BU_Steering_Cfactor 0 "TYPE_1" 1 "TYPE_2" 2 "TYPE_3" 3 "TYPE_4" ;
VAL_ 907 VC_BU_PEB_PRSNT 0 "Not_Present" 1 "Present" ;
VAL_ 907 VC_BU_TACHO_TYPE 0 "DISABLED" 1 "TYP_1" 2 "TYP_2" 3 "TYP_3" ;
VAL_ 908 GPS_Date_Year 65535 "SNA" ;
VAL_ 908 GPS_Date_Month 255 "SNA" ;
VAL_ 908 GPS_Date_Day 255 "SNA" ;
VAL_ 908 GPS_UTC_Hour 255 "SNA" ;
VAL_ 908 GPS_UTC_Minute 255 "SNA" ;
VAL_ 908 GPS_UTC_Second 65535 "SNA" ;
VAL_ 910 IBS3_TempFailStatus 0 "Fail_not_present" 1 "Fail_present" ;
VAL_ 910 IBS3_SOF_Q_Accuracy 0 "Inaccurate" 1 "Accurate" ;
VAL_ 910 IBS3_FLAG_DISCONNECT 0 "No_Disconnect" 1 "Disconnect" ;
VAL_ 910 IBS3_SOF_Q 255 "SNA" ;
VAL_ 910 IBS3_T_BATT 255 "SNA" ;
VAL_ 910 IBS3_SOH_Q 127 "SNA" ;
VAL_ 910 IBS3_SOH_Q_Accuracy 0 "Inaccurate" 1 "Accurate" ;
VAL_ 910 IBS3_SOC 127 "SNA" ;
VAL_ 910 IBS3_SOC_Accuracy 0 "Inaccurate" 1 "Accurate" ;
VAL_ 910 IBS3_SOF_VC 127 "SNA" ;
VAL_ 910 IBS3_SOF_V_Accuracy 0 "Inaccurate" 1 "Accurate" ;
VAL_ 913 DrvSide 0 "Left" 1 "Right" ;
VAL_ 913 SpdUnits 0 "km_h" 1 "mph" ;
VAL_ 926 NET_CFG_STAT_ePT 0 "NA" 1 "PROGRAMMED" 2 "REQUEST_DATA" 3 "SNA" ;
VAL_ 926 NetCfg_BSMO_ePT 0 "Not_Present" 1 "Present" ;
VAL_ 927 BU_NET_CFG_STAT_ePT 0 "NA" 1 "PROGAMMED" 2 "NA1" 3 "SNA" ;
VAL_ 927 BU_NetCfg_BSMO_ePT 0 "Not_Present" 1 "Present" ;
VAL_ 937 ILL_APRCH_TIME 255 "SNA" ;
VAL_ 937 HL_DLY_TIME 255 "SNA" ;
VAL_ 937 SOUND_LK_1ST_2ND 0 "OFF" 1 "FIRST" 2 "SECOND" 3 "SNA" ;
VAL_ 938 A_MPG 1023 "SNA" ;
VAL_ 938 A_EV_Miles 16777215 "SNA" ;
VAL_ 938 A_EV_Kilometers 16777215 "SNA" ;
VAL_ 939 A_KMpL 1023 "SNA" ;
VAL_ 939 A_Hybrid_Miles 16777215 "SNA" ;
VAL_ 939 A_Hybrid_Kilometers 16777215 "SNA" ;
VAL_ 940 A_Total_Dist_Miles 16777215 "SNA" ;
VAL_ 940 A_Total_Dist_Kilometers 16777215 "SNA" ;
